VERSION ""

NS_ :

BS_:

BU_: AGSM ECM EVCU2 MCPA MCPB SGCP TCM

BO_ 262 ENGINE_FD_2: 64 ECM
 SG_ TxAC_EMCC_rq_W : 189|1@0+ (1,0) [0|1] "-"  TCM
 SG_ TRANS_CLU_SLIP_MODE_W : 71|3@0+ (1,0) [0|7] "-"  TCM
 SG_ PowertrainPrplsnActv : 181|1@0+ (1,0) [0|1] "" Vector__XXX
 SG_ MessageCounter_ENGINE2 : 435|4@0+ (1,0) [0|15] "-"  EVCU2,TCM
 SG_ LV12PwrFreeRq_W : 176|1@0+ (1,0) [0|1] "-"  EVCU2,TCM
 SG_ KickDownRequest_W : 182|1@0+ (1,0) [0|1] "-"  TCM
 SG_ IntakeAirTemperature_W : 151|8@0+ (1,-40) [-40|214] "C"  TCM
 SG_ GasPedalPositionFailSts_W : 169|1@0+ (1,0) [0|1] "-"  TCM
 SG_ GasPedalPosition_W : 143|8@0+ (0.392,0) [0|99.568] "%"  TCM
 SG_ ESS_RqShftPark_W : 115|1@0+ (1,0) [0|0] "-"  TCM
 SG_ ESS_ENG_ST_W : 175|4@0+ (1,0) [0|15] "-"  TCM
 SG_ EngTrq_Enbl_Rq_TCM_W : 178|1@0+ (1,0) [0|1] "-"  EVCU2,TCM
 SG_ EngineSts_W : 87|2@0+ (1,0) [0|3] "-"  EVCU2,TCM
 SG_ EngineSpeedFailSts_W : 168|1@0+ (1,0) [0|1] "-"  SGCP,MCPB,MCPA
 SG_ EngineSpeed_W : 21|14@0+ (1,0) [0|16382] "1/min"  SGCP,EVCU2,MCPB,MCPA,TCM
 SG_ EngineIdleRefSpeed : 35|12@0+ (1,0) [0|4094] "1/min"  EVCU2,TCM
 SG_ EngineFrictionTorque_W : 112|9@0+ (1,0) [0|510] "Nm"  EVCU2
 SG_ ECM_LHOM_W : 188|1@0+ (1,0) [0|1] "-"  EVCU2,TCM
 SG_ ECM_LHOM_Trans_W : 117|2@0+ (1,0) [0|3] "-"  EVCU2,TCM
 SG_ CRC_ENGINE2 : 447|8@0+ (1,0) [0|255] "-"  EVCU2,TCM
 SG_ CrankHold_W : 179|1@0+ (1,0) [0|1] "-" Vector__XXX
 SG_ ESS_EBOOST_BRKHLD_STATUS : 279|3@0+ (1,0) [0|6] "-" Vector__XXX
 SG_ Engine_Stall_Detected : 197|1@0+ (1,0) [0|1] "-"  EVCU2
 SG_ EssEngStrtIsNotAllwdID : 68|3@0+ (1,0) [0|7] ""  EVCU2
 SG_ EssEngStrtIsNotAllwd : 37|1@0+ (1,0) [0|1] ""  EVCU2
 SG_ EssEngStopIsNotAllwdID : 59|4@0+ (1,0) [0|15] ""  EVCU2
 SG_ EssEngStopIsNotAllwd : 255|1@0+ (1,0) [0|1] ""  EVCU2
 SG_ EssEngSt : 202|3@0+ (1,0) [0|7] ""  EVCU2
 SG_ EssEngModReq : 254|3@0+ (1,0) [0|7] ""  EVCU2
 SG_ CompressionTest : 36|1@0+ (1,0) [0|1] ""  EVCU2

BO_ 258 BRAKE_FD_2: 64 EVCU2
 SG_ VehicleSpeedVSOSig : 4|13@0+ (0.0625,0) [0|511.875] "Km/h"  SGCP,MCPB,MCPA
 SG_ MessageCounter_BRAKE2 : 435|4@0+ (1,0) [0|15] "-"  MCPB,MCPA
 SG_ LongAccelerationFailSts_BSM : 69|1@0+ (1,0) [0|1] "-"  MCPB,MCPA
 SG_ LongAcceleration_BSM : 35|12@0+ (0.02,-40.96) [-40.96|40.92] "m/s^2"  MCPB,MCPA
 SG_ LatAccelerationFailSts_BSM : 68|1@0+ (1,0) [0|1] "-"  MCPB,MCPA
 SG_ LatAcceleration_BSM : 19|12@0+ (0.02,-40.96) [-40.96|40.92] "m/s^2"  MCPB,MCPA
 SG_ ESCActive : 84|1@0+ (1,0) [0|1] "-"  MCPB,MCPA
 SG_ CRC_BRAKE2 : 447|8@0+ (1,0) [0|255] "-"  MCPB,MCPA
 SG_ ABSActive : 83|1@0+ (1,0) [0|1] "-"  MCPB,MCPA

BO_ 476 AGSM_FD_2: 32 AGSM
 SG_ ShiftLockFailSts : 91|1@0+ (1,0) [0|1] "-"  TCM
 SG_ PRNDFailSts : 82|1@0+ (1,0) [0|1] "-"  EVCU2,TCM
 SG_ PRNDdisplayFailSts : 83|1@0+ (1,0) [0|1] "-"  EVCU2,TCM
 SG_ MessageCounter_AGSM2 : 179|4@0+ (1,0) [0|15] "-"  EVCU2,TCM
 SG_ CRC_AGSM2 : 191|8@0+ (1,0) [0|255] "-"  EVCU2,TCM
 SG_ APCM_Stat : 107|2@0+ (1,0) [0|2] "-"  EVCU2,TCM
 SG_ SolenoidFlt : 100|1@0+ (1,0) [0|1] "-"  TCM
 SG_ ShiftLever_PositionFlt : 104|1@0+ (1,0) [0|1] "-"  TCM
 SG_ Low_Mode_Req : 5|1@0+ (1,0) [0|1] "-"  TCM
 SG_ ShiftLeverPositionReq : 95|4@0+ (1,0) [0|15] "-"  EVCU2,MCPB,TCM

BO_ 242 PIM_F: 64 MCPA
 SG_ MC_PF1 : 499|4@0+ (1,0) [0|15] "-"  EVCU2
 SG_ INVFInterlockSts : 229|2@0+ (1,0) [0|3] "-"  EVCU2
 SG_ InvF_DC_Voltage : 271|10@0+ (1,0) [0|1022] "V"  EVCU2
 SG_ CRC_PF1 : 511|8@0+ (1,0) [0|255] "-"  EVCU2
 SG_ InvF_DerateReason : 170|4@0+ (1,0) [0|15] "-"  EVCU2
 SG_ MCPA_Torque_Achieved : 44|13@0+ (0.125,-512) [-512|511.875] "Nm"  EVCU2
 SG_ MCPA_TorqAchieved_AEMD_V : 196|1@0+ (1,0) [0|1] ""  EVCU2
 SG_ MCPA_TorqAchieved_AEMD : 299|13@0+ (0.125,-512) [-512|511.875] "Nm"  EVCU2
 SG_ MCPA_Spd_Lim : 356|16@0+ (1,-32767) [-32767|32678] "rpm"  EVCU2
 SG_ MCPA_RPM_V : 234|1@0+ (1,0) [0|1] ""  EVCU2
 SG_ MCPA_RPM : 28|16@0+ (1,-32768) [-32768|32767] "rpm"  EVCU2
 SG_ MCPA_MtrMinCpbltyTrq : 321|13@0+ (0.125,-512) [-512|511.875] "Nm"  EVCU2
 SG_ MCPA_MtrMaxCpbltyTrq : 318|13@0+ (0.125,-512) [-512|511.875] "Nm"  EVCU2
 SG_ MCPA_MtrIndex : 398|5@0+ (1,0) [0|31] ""  EVCU2
 SG_ MCPA_MinTorq : 280|13@0+ (0.125,-512) [-512|511.875] "Nm"  EVCU2
 SG_ MCPA_MaxTorq : 277|13@0+ (0.125,-512) [-512|511.875] "Nm"  EVCU2
 SG_ MCPA_Invrtr_State : 186|4@0+ (1,0) [0|15] ""  EVCU2
 SG_ MCPA_HV_CnctrOpn_Req : 195|1@0+ (1,0) [0|1] ""  EVCU2
 SG_ MCPA_Dschrge_Status : 393|2@0+ (1,0) [0|3] ""  EVCU2
 SG_ MCPA_DeratingFactor : 388|6@0+ (0.02,0) [0|1.26] ""  EVCU2
 SG_ MCPA_DC_Volt_V : 197|1@0+ (1,0) [0|1] ""  EVCU2
 SG_ MCPA_DC_Current_V : 198|1@0+ (1,0) [0|1] ""  EVCU2
 SG_ MCPA_DC_Current : 63|15@0+ (0.1,-1638.4) [-1638.4|1638.3] "A"  EVCU2
 SG_ MCPA_CpbltySpdDivVolt : 340|16@0+ (1,0) [0|65535] "rpm"  EVCU2
 SG_ MCPA_AccelRawV : 193|1@0+ (1,0) [0|1] ""  EVCU2
 SG_ MCPA_AccelRaw : 372|16@0+ (1,0) [0|65535] ""  EVCU2
 SG_ MCPA_6SO_Status : 64|2@0+ (1,0) [0|3] ""  EVCU2
 SG_ MCPA_3PS_Pos : 194|1@0+ (1,0) [0|1] ""  EVCU2
 SG_ InvF_CoolantTemp : 407|11@0+ (0.1,-40) [-40|164.7] "°C"  EVCU2
 SG_ MCPA_Torque_Achieved_V : 129|1@0+ (1,0) [0|1] ""  EVCU2
 SG_ MCPA_SPT_Stat : 78|2@0+ (1,0) [0|3] ""  EVCU2

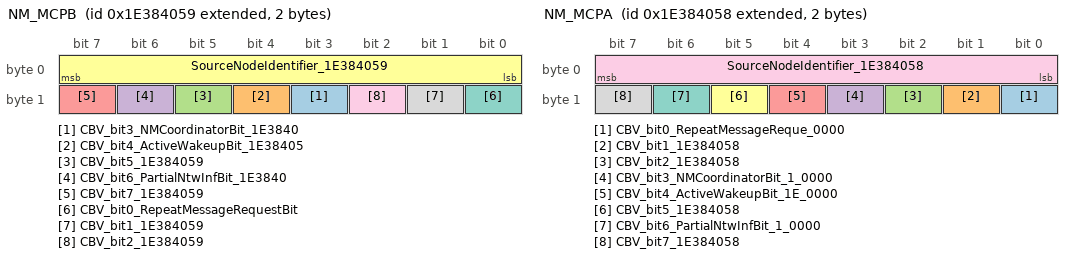
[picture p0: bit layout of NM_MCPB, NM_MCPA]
BO_ 2654486617 NM_MCPB: 2 MCPB
 SG_ CBV_bit3_NMCoordinatorBit_1E3840 : 11|1@0+ (1,0) [0|1] ""  SGCP,EVCU2,MCPA,AGSM
 SG_ CBV_bit4_ActiveWakeupBit_1E38405 : 12|1@0+ (1,0) [0|1] ""  SGCP,EVCU2,MCPA,AGSM
 SG_ CBV_bit5_1E384059 : 13|1@0+ (1,0) [0|1] ""  SGCP,EVCU2,MCPA,AGSM
 SG_ CBV_bit6_PartialNtwInfBit_1E3840 : 14|1@0+ (1,0) [0|1] ""  SGCP,EVCU2,MCPA,AGSM
 SG_ CBV_bit7_1E384059 : 15|1@0+ (1,0) [0|1] ""  SGCP,EVCU2,MCPA,AGSM
 SG_ SourceNodeIdentifier_1E384059 : 7|8@0+ (1,0) [0|255] "-"  SGCP,EVCU2,MCPA,AGSM
 SG_ CBV_bit0_RepeatMessageRequestBit : 8|1@0+ (1,0) [0|1] ""  SGCP,EVCU2,MCPA,AGSM
 SG_ CBV_bit1_1E384059 : 9|1@0+ (1,0) [0|1] ""  SGCP,EVCU2,MCPA,AGSM
 SG_ CBV_bit2_1E384059 : 10|1@0+ (1,0) [0|1] ""  SGCP,EVCU2,MCPA,AGSM

BO_ 2654486616 NM_MCPA: 2 MCPA
 SG_ CBV_bit0_RepeatMessageReque_0000 : 8|1@0+ (1,0) [0|1] ""  SGCP,EVCU2,MCPB,AGSM
 SG_ CBV_bit1_1E384058 : 9|1@0+ (1,0) [0|1] ""  SGCP,EVCU2,MCPB,AGSM
 SG_ CBV_bit2_1E384058 : 10|1@0+ (1,0) [0|1] ""  SGCP,EVCU2,MCPB,AGSM
 SG_ CBV_bit3_NMCoordinatorBit_1_0000 : 11|1@0+ (1,0) [0|1] ""  SGCP,EVCU2,MCPB,AGSM
 SG_ CBV_bit4_ActiveWakeupBit_1E_0000 : 12|1@0+ (1,0) [0|1] ""  SGCP,EVCU2,MCPB,AGSM
 SG_ CBV_bit5_1E384058 : 13|1@0+ (1,0) [0|1] ""  SGCP,EVCU2,MCPB,AGSM
 SG_ CBV_bit6_PartialNtwInfBit_1_0000 : 14|1@0+ (1,0) [0|1] ""  SGCP,EVCU2,MCPB,AGSM
 SG_ CBV_bit7_1E384058 : 15|1@0+ (1,0) [0|1] ""  SGCP,EVCU2,MCPB,AGSM
 SG_ SourceNodeIdentifier_1E384058 : 7|8@0+ (1,0) [0|255] "-"  SGCP,EVCU2,MCPB,AGSM

BO_ 2564682261 DIAGNOSTIC_ROE_FD_MCPB: 64 MCPB
 SG_ N_PDU_18DDF215 : 7|64@0+ (1,0) [0|0] ""  EVCU2

BO_ 2564682260 DIAGNOSTIC_ROE_FD_MCPA: 64 MCPA
 SG_ N_PDU_18DDF214 : 7|64@0+ (1,0) [0|0] ""  EVCU2

BO_ 2564485396 DIAGNOSTIC_RESPONSE_MCPA: 8 MCPA
 SG_ N_PDU_18DAF114 : 7|64@0+ (1,0) [0|0] ""  EVCU2

BO_ 2564485653 DIAGNOSTIC_RESPONSE_FD_MCPB: 64 MCPB
 SG_ N_PDU_18DAF215 : 7|64@0+ (1,0) [0|0] ""  EVCU2

BO_ 2564485652 DIAGNOSTIC_RESPONSE_FD_MCPA: 64 MCPA
 SG_ N_PDU_18DAF214 : 7|64@0+ (1,0) [0|0] ""  EVCU2

BO_ 2564429297 DIAGNOSTIC_REQUEST_MCPB: 8 EVCU2
 SG_ N_PDU_18DA15F1 : 7|64@0+ (1,0) [0|0] ""  MCPB

BO_ 2564429298 DIAGNOSTIC_REQUEST_FD_MCPB: 64 EVCU2
 SG_ N_PDU_18DA15F2 : 7|64@0+ (1,0) [0|0] ""  MCPB

BO_ 2564429042 DIAGNOSTIC_REQUEST_FD_MCPA: 64 EVCU2
 SG_ N_PDU_18DA14F2 : 7|64@0+ (1,0) [0|0] ""  MCPA

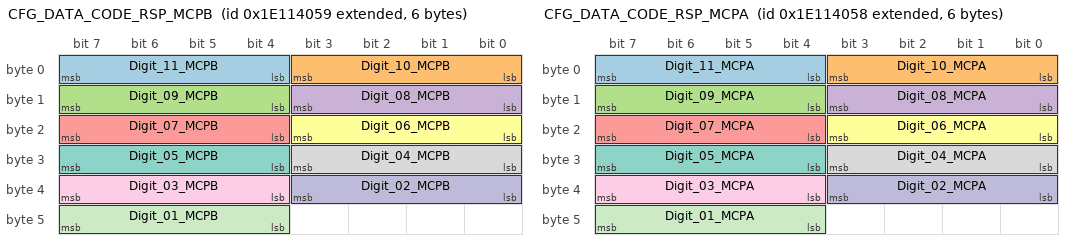
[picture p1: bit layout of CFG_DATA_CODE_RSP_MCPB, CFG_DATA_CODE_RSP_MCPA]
BO_ 2651930713 CFG_DATA_CODE_RSP_MCPB: 6 MCPB
 SG_ Digit_11_MCPB : 7|4@0+ (1,0) [0|15] "-"  EVCU2
 SG_ Digit_10_MCPB : 3|4@0+ (1,0) [0|15] "-"  EVCU2
 SG_ Digit_09_MCPB : 15|4@0+ (1,0) [0|15] "-"  EVCU2
 SG_ Digit_08_MCPB : 11|4@0+ (1,0) [0|15] "-"  EVCU2
 SG_ Digit_07_MCPB : 23|4@0+ (1,0) [0|15] "-"  EVCU2
 SG_ Digit_06_MCPB : 19|4@0+ (1,0) [0|15] "-"  EVCU2
 SG_ Digit_05_MCPB : 31|4@0+ (1,0) [0|15] "-"  EVCU2
 SG_ Digit_04_MCPB : 27|4@0+ (1,0) [0|15] "-"  EVCU2
 SG_ Digit_03_MCPB : 39|4@0+ (1,0) [0|15] "-"  EVCU2
 SG_ Digit_02_MCPB : 35|4@0+ (1,0) [0|15] "-"  EVCU2
 SG_ Digit_01_MCPB : 47|4@0+ (1,0) [0|15] "-"  EVCU2

BO_ 2651930712 CFG_DATA_CODE_RSP_MCPA: 6 MCPA
 SG_ Digit_11_MCPA : 7|4@0+ (1,0) [0|15] "-"  EVCU2
 SG_ Digit_10_MCPA : 3|4@0+ (1,0) [0|15] "-"  EVCU2
 SG_ Digit_09_MCPA : 15|4@0+ (1,0) [0|15] "-"  EVCU2
 SG_ Digit_08_MCPA : 11|4@0+ (1,0) [0|15] "-"  EVCU2
 SG_ Digit_07_MCPA : 23|4@0+ (1,0) [0|15] "-"  EVCU2
 SG_ Digit_06_MCPA : 19|4@0+ (1,0) [0|15] "-"  EVCU2
 SG_ Digit_05_MCPA : 31|4@0+ (1,0) [0|15] "-"  EVCU2
 SG_ Digit_04_MCPA : 27|4@0+ (1,0) [0|15] "-"  EVCU2
 SG_ Digit_03_MCPA : 39|4@0+ (1,0) [0|15] "-"  EVCU2
 SG_ Digit_02_MCPA : 35|4@0+ (1,0) [0|15] "-"  EVCU2
 SG_ Digit_01_MCPA : 47|4@0+ (1,0) [0|15] "-"  EVCU2

BO_ 496 PARK_DATA: 24 MCPB
 SG_ MessageCounter_PARK_DATA : 115|4@0+ (1,0) [0|15] ""  EVCU2
 SG_ CRC_PARK_DATA : 127|8@0+ (1,0) [0|255] ""  EVCU2
 SG_ PlockFailSts : 4|3@0+ (1,0) [0|6] ""  EVCU2
 SG_ Plock_PosSensor : 1|3@0+ (1,0) [0|6] ""  EVCU2
 SG_ Plock_MotorPosSts : 29|3@0+ (1,0) [0|6] ""  EVCU2
 SG_ MPR_PosSensor : 14|3@0+ (1,0) [0|6] ""  EVCU2
 SG_ Plock_fdbk_sts : 7|3@0+ (1,0) [0|7] ""  EVCU2

BO_ 1454 MCPB_DATA: 16 MCPB
 SG_ MCPB_Service_Lamp_Request : 22|1@0+ (1,0) [0|1] ""  EVCU2

BO_ 1444 MCPA_DATA: 16 MCPA
 SG_ MCPA_Service_Lamp_Request : 22|1@0+ (1,0) [0|1] ""  EVCU2

BO_ 105 VDCM_PWT3: 64 EVCU2
 SG_ T7_Sensor_Temp : 330|11@0+ (0.1,-40) [-40|164.7] "°C"  SGCP,MCPB,MCPA
 SG_ T7_CoolantTempVldty : 331|1@0+ (1,0) [0|1] ""  SGCP,MCPB,MCPA
 SG_ T4_Sensor_Temp : 378|11@0+ (0.1,-40) [-40|164.7] "°C"  SGCP,MCPB,MCPA
 SG_ PwrElecSnsr_TEMP : 55|8@0+ (1,-40) [-40|215] "°C"  SGCP
 SG_ PwrElecPmp_TEMP : 47|8@0+ (1,-40) [-40|215] "°C"  SGCP
 SG_ PIMRR_CoolantFlow : 318|7@0+ (0.5,0) [0|63.5] "Lpm"  SGCP

BO_ 260 PIM_RR: 64 MCPB
 SG_ INVRRInterlockSts : 253|2@0+ (1,0) [0|3] ""  EVCU2
 SG_ InvRR_DC_Voltage : 191|10@0+ (1,0) [0|1022] "V"  EVCU2
 SG_ InvRR_DerateReason : 143|4@0+ (1,0) [0|15] "-"  EVCU2
 SG_ InvRR_ACVoltage : 104|10@0+ (1,0) [0|1022] "V"  EVCU2
 SG_ RPM_MCPB : 22|16@0+ (1,-32768) [-32768|32767] "rpm"  EVCU2
 SG_ MCPB_Torque_Achieved_V : 38|1@0+ (1,0) [0|1] ""  EVCU2
 SG_ MCPB_Torque_Achieved : 251|13@0+ (0.125,-512) [-512|511.875] "Nm"  EVCU2
 SG_ MCPB_TorqAchieved_AEMD_V : 35|1@0+ (1,0) [0|1] ""  EVCU2
 SG_ MCPB_TorqAchieved_AEMD : 302|13@0+ (0.125,-512) [-512|511.875] "Nm"  EVCU2
 SG_ MCPB_Spd_Lim : 343|16@0+ (1,-32767) [-32767|32678] "rpm"  EVCU2
 SG_ MCPB_RPM_V : 204|1@0+ (1,0) [0|1] ""  EVCU2
 SG_ MCPB_MtrMinCpbltyTrq : 324|13@0+ (0.125,-512) [-512|511.875] "Nm"  EVCU2
 SG_ MCPB_MtrMaxCpbltyTrq : 305|13@0+ (0.125,-512) [-512|511.875] "Nm"  EVCU2
 SG_ MCPB_MtrIndex : 147|5@0+ (1,0) [0|31] ""  EVCU2
 SG_ MCPB_MinTorq : 283|13@0+ (0.125,-512) [-512|511.875] "Nm"  EVCU2
 SG_ MCPB_MaxTorq : 264|13@0+ (0.125,-512) [-512|511.875] "Nm"  EVCU2
 SG_ MCPB_Invrtr_State : 151|4@0+ (1,0) [0|15] ""  EVCU2
 SG_ MCPB_HV_CnctrOpn_Req : 34|1@0+ (1,0) [0|1] ""  EVCU2
 SG_ MCPB_Dschrge_Status : 102|2@0+ (1,0) [0|3] ""  EVCU2
 SG_ MCPB_DeratingFactor : 270|6@0+ (0.02,0) [0|1.26] ""  EVCU2
 SG_ MCPB_DC_Volt_V : 36|1@0+ (1,0) [0|1] ""  EVCU2
 SG_ MCPB_DC_Current_V : 37|1@0+ (1,0) [0|1] ""  EVCU2
 SG_ MCPB_DC_Current : 391|15@0+ (0.1,-1638.4) [-1638.4|1638.3] "A"  EVCU2
 SG_ MCPB_CpbltySpdDivVolt : 392|16@0+ (1,0) [0|65535] "V"  EVCU2
 SG_ MCPB_AccelRawV : 32|1@0+ (1,0) [0|1] ""  EVCU2
 SG_ MCPB_AccelRaw : 359|16@0+ (1,0) [0|65535] ""  EVCU2
 SG_ MCPB_6SO_Status : 47|2@0+ (1,0) [0|3] ""  EVCU2
 SG_ MCPB_3PS_Pos : 33|1@0+ (1,0) [0|1] ""  EVCU2
 SG_ MC_PRR1 : 499|4@0+ (1,0) [0|15] ""  EVCU2
 SG_ InvRR_CoolantTemp : 375|11@0+ (0.1,-40) [-40|164.7] "°C"  EVCU2
 SG_ CRC_PRR1 : 511|8@0+ (1,0) [0|255] ""  EVCU2
 SG_ MCPB_SPT_Stat : 158|2@0+ (1,0) [0|3] ""  EVCU2

BO_ 1062 MCPA_DATA2: 64 MCPA
 SG_ MCPA_Temp : 7|8@0+ (1,-40) [-40|215] "°C"  EVCU2
 SG_ MCPA_Rotor_Temperature : 31|8@0+ (1,-40) [-40|215] "°C"  EVCU2
 SG_ MCPA_Inverter_Temp : 15|8@0+ (1,-40) [-40|215] "°C"  EVCU2
 SG_ MCPA_Control_Board_Temperature : 23|8@0+ (1,-40) [-40|215] "°C"  EVCU2
 SG_ CLrDiagInfo_MCPA : 248|1@0+ (1,0) [0|1] ""  EVCU2
 SG_ MessageCounter_MCPA_DATA2 : 435|4@0+ (1,0) [0|15] ""  EVCU2
 SG_ CRC_MCPA_DATA2 : 447|8@0+ (1,0) [0|255] ""  EVCU2
 SG_ MCPA_PIM_DC_Side_Busbar_Temp : 423|8@0+ (1,-40) [-40|215] "°C"  EVCU2
 SG_ MCPA_Service_Lamp_Request_2 : 47|1@0+ (1,0) [0|1] ""  EVCU2

BO_ 300 INVTARGET1: 64 EVCU2
 SG_ UDCMax_Unlim_MCPB : 113|16@0+ (0.01,0) [0|655.35] "V"  MCPB
 SG_ UDCMax_Unlim_MCPA : 65|16@0+ (0.01,0) [0|655.35] "V"  MCPA
 SG_ TqGrdtLim_MCPB : 144|16@0+ (0.1,0) [0|6553.5] "Nm/s"  MCPB
 SG_ TqGrdtLim_MCPA : 97|16@0+ (0.1,0) [0|6553.5] "Nm/s"  MCPA
 SG_ TorqueCommand_MCPB : 201|13@0+ (0.125,-512) [-512|511.875] "Nm"  MCPB
 SG_ TorqueCommand_MCPA : 7|13@0+ (0.125,-512) [-512|511.875] "Nm"  MCPA
 SG_ TargetMotorRPM_MCPB : 216|16@0+ (0.5,-16384) [-16384|16383.5] "rpm"  MCPB
 SG_ TargetMotorRPM_MCPA : 22|16@0+ (0.5,-16384) [-16384|16383.5] "rpm"  MCPA
 SG_ SpdGrdtLim_MCPB : 273|11@0+ (20,0) [0|40940] "rpm/s"  MCPB
 SG_ SpdGrdtLim_MCPA : 160|11@0+ (20,0) [0|40940] "rpm/s"  MCPA
 SG_ Mtr_6SO_Request_MCPB : 145|1@0+ (1,0) [0|1] ""  MCPB
 SG_ Mtr_6SO_Request_MCPA : 38|1@0+ (1,0) [0|1] ""  MCPA
 SG_ ModeCommand_MCPB : 220|4@0+ (1,0) [0|15] ""  MCPB
 SG_ ModeCommand_MCPA : 10|4@0+ (1,0) [0|15] ""  MCPA
 SG_ MessageCounter_INVTARGET1 : 435|4@0+ (1,0) [0|15] ""  SGCP,MCPB,MCPA
 SG_ CRC_INVTARGET1 : 447|8@0+ (1,0) [0|255] ""  SGCP,MCPB,MCPA
 SG_ AEMD_MinOffset_MCPB : 252|12@0+ (0.125,-511.875) [-511.875|0] "Nm"  MCPB
 SG_ AEMD_MinOffset_MCPA : 41|12@0+ (0.125,-511.875) [-511.875|0] "Nm"  MCPA
 SG_ AEMD_MaxOffset_MCPB : 232|12@0+ (0.125,0) [0|511.875] "Nm"  MCPB
 SG_ AEMD_MaxOffset_MCPA : 37|12@0+ (0.125,0) [0|511.875] "Nm"  MCPA
 SG_ AEMD_Sclr_Gn_MCPB : 356|9@0+ (0.01,0) [0|5.11] "rad/s"  MCPB
 SG_ AEMD_Sclr_Gn_MCPA : 349|9@0+ (0.01,0) [0|5.11] "rad/s"  MCPA
 SG_ AEMD_Cutoff_FreqHigh_MCPB : 383|8@0+ (0.1,0) [0|25.5] "Hz"  MCPB
 SG_ AEMD_Cutoff_FreqHigh_MCPA : 375|8@0+ (0.1,0) [0|25.5] "Hz"  MCPA
 SG_ Pwr_Electronics_Loop_FlwRate_MCP : 57|8@0+ (0.1,0) [0|25.5] "LPM"  MCPA
 SG_ AEMD_Cutoff_FreqLow_MCPB : 407|8@0+ (0.1,4.5) [4.5|30] "Hz"  MCPB
 SG_ AEMD_Cutoff_FreqLow_MCPA : 399|8@0+ (0.1,4.5) [4.5|30] "Hz"  MCPA
 SG_ Pwr_Electronics_Loop_FlwRat_0000 : 265|8@0+ (0.1,0) [0|25.5] "LPM"  MCPB

BO_ 1063 MCPB_DATA2: 64 MCPB
 SG_ MCPB_Temp : 6|8@0+ (1,-40) [-40|215] "°C"  EVCU2
 SG_ MCPB_Rotor_Temperature : 30|8@0+ (1,-40) [-40|215] "°C"  EVCU2
 SG_ MCPB_Inverter_Temp : 14|8@0+ (1,-40) [-40|215] "°C"  EVCU2
 SG_ MCPB_Control_Board_Temperature : 22|8@0+ (1,-40) [-40|215] "°C"  EVCU2
 SG_ CLrDiagInfo_MCPB : 7|1@0+ (1,0) [0|1] ""  EVCU2
 SG_ MessageCounter_MCPB_DATA2 : 435|4@0+ (1,0) [0|15] ""  EVCU2
 SG_ CRC_MCPB_DATA2 : 447|8@0+ (1,0) [0|255] ""  EVCU2
 SG_ MCPB_PIM_DC_Side_Busbar_Temp : 55|8@0+ (1,-40) [-40|215] "°C"  EVCU2
 SG_ MCPB_Service_Lamp_Request_2 : 47|1@0+ (1,0) [0|1] ""  EVCU2

BO_ 292 BATTERY_HV_STATUS1: 64 EVCU2
 SG_ MessageCounter_BATT_HV_STATUS1 : 435|4@0+ (1,0) [0|15] "-"  SGCP,MCPB,MCPA
 SG_ CRC_BATT_HV_STATUS1 : 447|8@0+ (1,0) [0|255] "-"  SGCP,MCPB,MCPA
 SG_ BPCM_HV_TractionBusVoltage : 146|11@0+ (1,0) [0|2047] "V"  SGCP,MCPB,MCPA
 SG_ BPCM_HV_Trac_Bus_Sts : 36|3@0+ (1,0) [0|7] ""  SGCP,MCPB,MCPA

BO_ 2654339273 PDC_INFO_FD_SGCP: 32 SGCP
 SG_ GenericFailSts_FD16_SGCP : 180|1@0+ (1,0) [0|1] ""  EVCU2
 SG_ EOL_FD16_SGCP : 2|1@0+ (1,0) [0|1] "-"  EVCU2
 SG_ CurrentFailSts_FD16_SGCP : 181|1@0+ (1,0) [0|1] ""  EVCU2

BO_ 2654339161 PDC_INFO_FD_MCPB: 32 MCPB
 SG_ EOL_FD16_MCPB : 2|1@0+ (1,0) [0|1] "-"  EVCU2
 SG_ GenericFailSts_FD16_MCPB : 172|1@0+ (1,0) [0|1] ""  EVCU2
 SG_ CurrentFailSts_FD16_MCPB : 173|1@0+ (1,0) [0|1] ""  EVCU2

BO_ 2654339160 PDC_INFO_FD_MCPA: 32 MCPA
 SG_ EOL_FD16_MCPA : 2|1@0+ (1,0) [0|1] "-"  EVCU2
 SG_ GenericFailSts_FD16_MCPA : 172|1@0+ (1,0) [0|1] ""  EVCU2
 SG_ CurrentFailSts_FD16_MCPA : 173|1@0+ (1,0) [0|1] ""  EVCU2

BO_ 2564682364 DIAGNOSTIC_ROE_FD_SGCP: 64 SGCP
 SG_ N_PDU_18DDF27C : 7|64@0+ (1,0) [0|0] ""  EVCU2

BO_ 2564485756 DIAGNOSTIC_RESPONSE_FD_SGCP: 64 SGCP
 SG_ N_PDU_18DAF27C : 7|64@0+ (1,0) [0|0] ""  EVCU2

BO_ 2564455666 DIAGNOSTIC_REQUEST_FD_SGCP: 64 EVCU2
 SG_ N_PDU_18DA7CF2 : 7|64@0+ (1,0) [0|0] ""  SGCP

BO_ 243 SGCP_PWT1: 64 SGCP
 SG_ SGCP_Torque_Achieved_V : 195|1@0+ (1,0) [0|1] ""  EVCU2
 SG_ SGCP_Torque_Achieved : 44|13@0+ (0.125,-512) [-512|511.875] "Nm"  EVCU2
 SG_ SGCP_TorqAchieved_AEMD_V : 45|1@0+ (1,0) [0|1] ""  EVCU2
 SG_ SGCP_TorqAchieved_AEMD : 299|13@0+ (0.125,-512) [-512|511.875] "Nm"  EVCU2
 SG_ SGCP_SPT_Stat : 78|2@0+ (1,0) [0|3] ""  EVCU2
 SG_ SGCP_Spd_Lim : 356|16@0+ (1,-32767) [-32767|32678] "rpm"  EVCU2
 SG_ SGCP_RPM_V : 192|1@0+ (1,0) [0|1] ""  EVCU2
 SG_ SGCP_RPM : 7|16@0+ (1,-32768) [-32768|32767] "rpm"  EVCU2
 SG_ SGCP_MtrMinCpbltyTrq : 321|13@0+ (0.125,-512) [-512|511.875] "Nm"  EVCU2
 SG_ SGCP_MtrMaxCpbltyTrq : 318|13@0+ (0.125,-512) [-512|511.875] "Nm"  EVCU2
 SG_ SGCP_MtrIndex : 398|5@0+ (1,0) [0|31] ""  EVCU2
 SG_ SGCP_MinTorq : 280|13@0+ (0.125,-512) [-512|511.875] "Nm"  EVCU2
 SG_ SGCP_MaxTorq : 277|13@0+ (0.125,-512) [-512|511.875] "Nm"  EVCU2
 SG_ SGCP_Invrtr_State : 187|4@0+ (1,0) [0|15] ""  EVCU2
 SG_ SGCP_InterlockSts : 194|2@0+ (1,0) [0|3] "-"  EVCU2
 SG_ SGCP_HV_CnctrOpn_Req : 74|1@0+ (1,0) [0|1] ""  EVCU2
 SG_ SGCP_Dschrge_Status : 393|2@0+ (1,0) [0|3] ""  EVCU2
 SG_ SGCP_DeratingFactor : 388|6@0+ (0.02,0) [0|1.26] ""  EVCU2
 SG_ SGCP_DerateReason : 191|4@0+ (1,0) [0|15] "-"  EVCU2
 SG_ SGCP_DC_Voltage : 271|10@0+ (1,0) [0|1022] "V"  EVCU2
 SG_ SGCP_DC_Volt_V : 75|1@0+ (1,0) [0|1] ""  EVCU2
 SG_ SGCP_DC_Current_V : 76|1@0+ (1,0) [0|1] ""  EVCU2
 SG_ SGCP_DC_Current : 63|15@0+ (0.1,-1638.4) [-1638.4|1638.3] "A"  EVCU2
 SG_ SGCP_CpbltySpdDivVolt : 340|16@0+ (1,0) [0|65535] "rpm"  EVCU2
 SG_ SGCP_Comm_Fail_CAN : 199|4@0+ (1,0) [0|14] ""  EVCU2
 SG_ SGCP_AccelRawV : 72|1@0+ (1,0) [0|1] ""  EVCU2
 SG_ SGCP_AccelRaw : 372|16@0+ (1,0) [0|65535] ""  EVCU2
 SG_ SGCP_6SO_Status : 64|2@0+ (1,0) [0|3] ""  EVCU2
 SG_ SGCP_3PS_Pos : 73|1@0+ (1,0) [0|1] ""  EVCU2
 SG_ MC_SGCP_PWT1 : 435|4@0+ (1,0) [0|15] "-"  EVCU2
 SG_ CRC_SGCP_PWT1 : 447|8@0+ (1,0) [0|255] "-"  EVCU2

CM_ SG_ 262 TxAC_EMCC_rq_W "-";
CM_ SG_ 262 TRANS_CLU_SLIP_MODE_W "-";
CM_ SG_ 262 PowertrainPrplsnActv "Powertrain Propulsion Status.";
CM_ SG_ 262 MessageCounter_ENGINE2 "This signal is a counter used for safety checks strategies. This counter is incremented of 1 (one) unit at each frame transmission.";
CM_ SG_ 262 LV12PwrFreeRq_W "-";
CM_ SG_ 262 KickDownRequest_W "It is set to KD_requested whenever the Kick-Down condition is detected by the ECM.";
CM_ SG_ 262 GasPedalPositionFailSts_W "-";
CM_ SG_ 262 GasPedalPosition_W "-";
CM_ SG_ 262 ESS_RqShftPark_W "ESS Request shift to Park.  1 = True, 0 = False";
CM_ SG_ 262 ESS_ENG_ST_W "ESS Engine State";
CM_ SG_ 262 EngTrq_Enbl_Rq_TCM_W "Allow TRANS torque request";
CM_ SG_ 262 EngineSts_W "-";
CM_ SG_ 262 EngineSpeedFailSts_W "Used to indicate if a Fail is present for the engine speed";
CM_ SG_ 262 EngineSpeed_W "It gives information on C-CAN network about  engine speed";
CM_ SG_ 262 EngineIdleRefSpeed "This signal represents target of engine speed for the idle control function, at the end of dynamic transient conditions. It takes into account changes of idle speed due to temperature and auxiliary loads. It is updated even when the engine is ou(...)";
CM_ SG_ 262 EngineFrictionTorque_W "-";
CM_ SG_ 262 ECM_LHOM_W "-";
CM_ SG_ 262 ECM_LHOM_Trans_W "Indicates to the transmission the Limp Home Status of ECM and Torque Accuracy";
CM_ SG_ 262 CRC_ENGINE2 "CRC according to SAE J1850 standard at each frame transmission.";
CM_ SG_ 262 CrankHold_W "Used by ECM to command an action to the BCM cranking relay during cranking phase";
CM_ SG_ 262 ESS_EBOOST_BRKHLD_STATUS "ESS brake hold release status";
CM_ SG_ 262 Engine_Stall_Detected "Engine stall detected flag";
CM_ SG_ 262 EssEngStrtIsNotAllwdID "This is an enumerated interface that reports the reason why a Start is not allowed by the ECM";
CM_ SG_ 262 EssEngStrtIsNotAllwd "This is a flag that signifies if a start is allowed by the ECM";
CM_ SG_ 262 EssEngStopIsNotAllwdID "This is an enumerated interface that reports the reason why a Stop is not allowed by the ECM";
CM_ SG_ 262 EssEngStopIsNotAllwd "This is a flag that signifies if a stop is allowed by the ECM";
CM_ SG_ 262 EssEngSt "Signal that gives feedback on the current engine state";
CM_ SG_ 262 EssEngModReq "Command signal from EssEveMgr that directs the engine actuators for turning On or Off the engine";
CM_ SG_ 262 CompressionTest "This signal requests a compression test";
CM_ SG_ 258 VehicleSpeedVSOSig "It is the average vehicle speed calculated.";
CM_ SG_ 258 MessageCounter_BRAKE2 "This signal is a counter used for safety checks strategies. This counter is incremented of 1 (one) unit at each frame transmission.";
CM_ SG_ 258 LongAccelerationFailSts_BSM "This signal indicates the status of Longitudinal acceleration signal";
CM_ SG_ 258 LongAcceleration_BSM "This signal indicates the Longitudinal Acceleration Value";
CM_ SG_ 258 LatAccelerationFailSts_BSM "This signal indicates the status of Lateral Acceleration Signal";
CM_ SG_ 258 LatAcceleration_BSM "This signal indicates the Lateral Acceleration Value";
CM_ SG_ 258 ESCActive "This signal is set to Active when the brake intervention by ESC is active.";
CM_ SG_ 258 CRC_BRAKE2 "CRC according to SAE J1850 standard at each frame transmission.";
CM_ SG_ 258 ABSActive "This signal is set to Active when the ABS functionality is active.";
CM_ SG_ 476 ShiftLockFailSts "-";
CM_ SG_ 476 PRNDFailSts "-";
CM_ SG_ 476 PRNDdisplayFailSts "-";
CM_ SG_ 476 MessageCounter_AGSM2 "This signal is a counter used for safety checks strategies. This counter is incremented of 1 (one) unit at each frame transmission.";
CM_ SG_ 476 CRC_AGSM2 "CRC according to SAE J1850 standard at each frame transmission.";
CM_ SG_ 476 APCM_Stat "Auto position correction mode status";
CM_ SG_ 476 SolenoidFlt "Rack / detent sensor fault, 1=fault";
CM_ SG_ 476 ShiftLever_PositionFlt "Shifter Position Failure";
CM_ SG_ 476 Low_Mode_Req "Signal Indicating L Button Pressed Status";
CM_ SG_ 476 ShiftLeverPositionReq "This signal describes the shift lever position requested by the driver.";
CM_ SG_ 242 MC_PF1 "Message counter according to SAE J1850 standard that has to be calculated from bit 63 to bit 8 at each frame transmission.";
CM_ SG_ 242 INVFInterlockSts "Front inverter interlock state";
CM_ SG_ 242 InvF_DC_Voltage "Inverter Front DC Voltage.";
CM_ SG_ 242 CRC_PF1 "CRC according to SAE J1850 standard that has to be calculated from bit 63 to bit 8 at each frame transmission.";
CM_ SG_ 242 InvF_DerateReason "Inverter Derating Reason";
CM_ SG_ 242 MCPA_Torque_Achieved "Motr B Torque Achieved";
CM_ SG_ 242 MCPA_TorqAchieved_AEMD_V "Motor Torque Achieved Validity";
CM_ SG_ 242 MCPA_TorqAchieved_AEMD "Motor Torque Achieved";
CM_ SG_ 242 MCPA_Spd_Lim "Limited motor speed during reduced performance from MCP B";
CM_ SG_ 242 MCPA_RPM_V "Motor A Speed Validity, [1] = True";
CM_ SG_ 242 MCPA_RPM "Motor A Speed Raw";
CM_ SG_ 242 MCPA_MtrMinCpbltyTrq "Motor A Min Capability Torque";
CM_ SG_ 242 MCPA_MtrMaxCpbltyTrq "Motor A Max Capability Torque";
CM_ SG_ 242 MCPA_MtrIndex "Motor A Capability Curve Array Index";
CM_ SG_ 242 MCPA_MinTorq "Motor A Minimum Torque";
CM_ SG_ 242 MCPA_MaxTorq "Motor A Maximum Torque";
CM_ SG_ 242 MCPA_Invrtr_State "Inverter State of Operation of Motor A";
CM_ SG_ 242 MCPA_HV_CnctrOpn_Req "HV Battery pack contactor request";
CM_ SG_ 242 MCPA_Dschrge_Status "The active discharge status of MCPA";
CM_ SG_ 242 MCPA_DeratingFactor "Motor A Derating Factor";
CM_ SG_ 242 MCPA_DC_Volt_V "Motor A DC current  validity, [1] = True";
CM_ SG_ 242 MCPA_DC_Current_V "Motor A DC current  validity, [1] = True";
CM_ SG_ 242 MCPA_DC_Current "Motor A DC Current";
CM_ SG_ 242 MCPA_CpbltySpdDivVolt "Motor A Speed at Capability Curve";
CM_ SG_ 242 MCPA_AccelRawV "Motor A Acceleration Validity";
CM_ SG_ 242 MCPA_AccelRaw "Motor A Acceleration";
CM_ SG_ 242 MCPA_6SO_Status "Motor A 6SO Status";
CM_ SG_ 242 MCPA_3PS_Pos "3 phase motor short possible from MCP B; True = [1]";
CM_ SG_ 242 InvF_CoolantTemp "PIM Coolant Temperature";
CM_ SG_ 242 MCPA_Torque_Achieved_V "Achieved Torque value Validity, [1] = True";
CM_ SG_ 242 MCPA_SPT_Stat "Inverter Isolation Status";
CM_ SG_ 2654486617 CBV_bit3_NMCoordinatorBit_1E3840 "NM Coordinator Sleep Bit";
CM_ SG_ 2654486617 CBV_bit4_ActiveWakeupBit_1E38405 "Active Wakeup Bit";
CM_ SG_ 2654486617 CBV_bit6_PartialNtwInfBit_1E3840 "Partial Network Information Bit (PNI)";
CM_ SG_ 2654486617 SourceNodeIdentifier_1E384059 "Source Node Identifier";
CM_ SG_ 2654486617 CBV_bit0_RepeatMessageRequestBit "Repeat Message Request Bit";
CM_ SG_ 2654486616 CBV_bit0_RepeatMessageReque_0000 "Repeat Message Request Bit";
CM_ SG_ 2654486616 CBV_bit3_NMCoordinatorBit_1_0000 "NM Coordinator Sleep Bit";
CM_ SG_ 2654486616 CBV_bit4_ActiveWakeupBit_1E_0000 "Active Wakeup Bit";
CM_ SG_ 2654486616 CBV_bit6_PartialNtwInfBit_1_0000 "Partial Network Information Bit (PNI)";
CM_ SG_ 2654486616 SourceNodeIdentifier_1E384058 "Source Node Identifier";
CM_ SG_ 2564682261 N_PDU_18DDF215 "This signal is used for diagnostic purposes";
CM_ SG_ 2564682260 N_PDU_18DDF214 "This signal is used for diagnostic purposes";
CM_ SG_ 2564485396 N_PDU_18DAF114 "This signal is used for diagnostic purposes";
CM_ SG_ 2564485653 N_PDU_18DAF215 "This signal is used for diagnostic purposes";
CM_ SG_ 2564485652 N_PDU_18DAF214 "This signal is used for diagnostic purposes";
CM_ SG_ 2564429297 N_PDU_18DA15F1 "This signal is used for diagnostic purposes";
CM_ SG_ 2564429298 N_PDU_18DA15F2 "This signal is used for diagnostic purposes";
CM_ SG_ 2564429042 N_PDU_18DA14F2 "This signal is used for diagnostic purposes";
CM_ SG_ 496 MessageCounter_PARK_DATA "This signal is a counter used for safety checks strategies. This counter is incremented of 1 (one) unit at each frame transmission.";
CM_ SG_ 496 CRC_PARK_DATA "CRC according to SAE J1850 standard at each frame transmission.";
CM_ SG_ 496 PlockFailSts "Park Lock Fail Sts";
CM_ SG_ 496 Plock_PosSensor "Par lock physical position sensor feedback";
CM_ SG_ 496 Plock_MotorPosSts "Park lock motor position status";
CM_ SG_ 496 MPR_PosSensor "Manual Park Release sensor feedback";
CM_ SG_ 496 Plock_fdbk_sts "Park lock status";
CM_ SG_ 1454 MCPB_Service_Lamp_Request "The Service Lamp Request from the MCPB";
CM_ SG_ 1444 MCPA_Service_Lamp_Request "The Service Light Request from the MCPA";
CM_ SG_ 105 T7_Sensor_Temp "T7 Temperature sensor";
CM_ SG_ 105 T7_CoolantTempVldty "Inlet inverter temperature validity";
CM_ SG_ 105 T4_Sensor_Temp "T4 Temperature sensor";
CM_ SG_ 105 PwrElecSnsr_TEMP "PwrElecSensor_TEMP";
CM_ SG_ 105 PwrElecPmp_TEMP "PwrElecPmp temperature";
CM_ SG_ 105 PIMRR_CoolantFlow "Rear PIM flow rate";
CM_ SG_ 260 INVRRInterlockSts "Rear right inverter interlock state";
CM_ SG_ 260 InvRR_DC_Voltage "This signal indicates the Inverter Rear Right DC Voltage.";
CM_ SG_ 260 InvRR_DerateReason "Inverter Derating Reason.";
CM_ SG_ 260 InvRR_ACVoltage "AC RMS Voltage.";
CM_ SG_ 260 RPM_MCPB "Motor B Speed Raw";
CM_ SG_ 260 MCPB_Torque_Achieved_V "Achieved Torque value Validity, [1] = True";
CM_ SG_ 260 MCPB_Torque_Achieved "Motr B Torque Achieved";
CM_ SG_ 260 MCPB_TorqAchieved_AEMD_V "Motor Torque Achieved Validity";
CM_ SG_ 260 MCPB_TorqAchieved_AEMD "Motor Torque Achieved";
CM_ SG_ 260 MCPB_Spd_Lim "Limited motor speed during reduced performance from MCP B";
CM_ SG_ 260 MCPB_RPM_V "Motor B Speed Validity, [1] = True";
CM_ SG_ 260 MCPB_MtrMinCpbltyTrq "Motor B Min Capability Torque";
CM_ SG_ 260 MCPB_MtrMaxCpbltyTrq "Motor B Max Capability Torque";
CM_ SG_ 260 MCPB_MtrIndex "Motor B Capability Curve Array Index";
CM_ SG_ 260 MCPB_MinTorq "Motor B Minimum Torque";
CM_ SG_ 260 MCPB_MaxTorq "Motor B Maximum Torque";
CM_ SG_ 260 MCPB_Invrtr_State "Inverter State of Operation of Motor B";
CM_ SG_ 260 MCPB_HV_CnctrOpn_Req "HV Battery pack contactor request";
CM_ SG_ 260 MCPB_Dschrge_Status "The active discharge status of MCPB";
CM_ SG_ 260 MCPB_DeratingFactor "Motor B Derating Factor";
CM_ SG_ 260 MCPB_DC_Volt_V "Achieved Torque value Validity, [1] = True";
CM_ SG_ 260 MCPB_DC_Current_V "Achieved Torque value Validity, [1] = True";
CM_ SG_ 260 MCPB_DC_Current "Motor B DC Current";
CM_ SG_ 260 MCPB_CpbltySpdDivVolt "Motor B Speed at Capability Curve";
CM_ SG_ 260 MCPB_AccelRawV "Motor B Acceleration Validity";
CM_ SG_ 260 MCPB_AccelRaw "Motor B Acceleration";
CM_ SG_ 260 MCPB_6SO_Status "Motor B 6SO Status";
CM_ SG_ 260 MCPB_3PS_Pos "3 phase motor short possible from MCP B; True = [1]";
CM_ SG_ 260 MC_PRR1 "This signal indicates the Message Counter SaeJ1850.";
CM_ SG_ 260 InvRR_CoolantTemp "PIM Coolant Temperature";
CM_ SG_ 260 CRC_PRR1 "This signal indicates the CRC SaeJ1850.";
CM_ SG_ 260 MCPB_SPT_Stat "Inverter Isolation Status";
CM_ SG_ 1062 MCPA_Temp "Motor A temperature";
CM_ SG_ 1062 MCPA_Rotor_Temperature "Rotor Temperature from Motor";
CM_ SG_ 1062 MCPA_Inverter_Temp "Inverter B Temperature";
CM_ SG_ 1062 MCPA_Control_Board_Temperature "Control Board temperature from Motor";
CM_ SG_ 1062 CLrDiagInfo_MCPA "Legislative Diagnostic Clear information for MCPA";
CM_ SG_ 1062 MessageCounter_MCPA_DATA2 "This signal is a counter used for safety checks strategies. This counter is incremented of 1 (one) unit at each frame transmission.";
CM_ SG_ 1062 CRC_MCPA_DATA2 "CRC according to SAE J1850 standard at each frame transmission.";
CM_ SG_ 1062 MCPA_PIM_DC_Side_Busbar_Temp "MCPA busbar temperature in DC side";
CM_ SG_ 1062 MCPA_Service_Lamp_Request_2 "The Service Light Request from the MCPA";
CM_ SG_ 300 UDCMax_Unlim_MCPB "Maximum DC voltage limit before linear generator derating Consider Max or Min torque. Default 52V";
CM_ SG_ 300 UDCMax_Unlim_MCPA "Maximum DC voltage limit before linear generator derating Consider Max or Min torque. Default 52V";
CM_ SG_ 300 TqGrdtLim_MCPB "Positive or Negative Torque Gradient applied for Torque Control Mode and Speed Control Mode. Default 1000Nm/s";
CM_ SG_ 300 TqGrdtLim_MCPA "Positive or Negative Torque Gradient applied for Torque Control Mode and Speed Control Mode. Default 1000Nm/s";
CM_ SG_ 300 TorqueCommand_MCPB "Torque command for MCPB";
CM_ SG_ 300 TorqueCommand_MCPA "Torque command for MCPA";
CM_ SG_ 300 TargetMotorRPM_MCPB "Target Motor RPM for MCPB";
CM_ SG_ 300 TargetMotorRPM_MCPA "Target Motor RPM for MCPA";
CM_ SG_ 300 SpdGrdtLim_MCPB "Positive or negative (symetric) Speed Request Gradient applicable on both sign only for Speed Control Mode. Default 25,000 rpm/s";
CM_ SG_ 300 SpdGrdtLim_MCPA "Positive or negative (symetric) Speed Request Gradient applicable on both sign only for Speed Control Mode. Default 25,000 rpm/s";
CM_ SG_ 300 Mtr_6SO_Request_MCPB "Six Switch Open Request  for MCPB (1=RequestActive; 0=RequestNotActive)";
CM_ SG_ 300 Mtr_6SO_Request_MCPA "Six Switch Open Request  for MCPA (1=RequestActive; 0=RequestNotActive)";
CM_ SG_ 300 ModeCommand_MCPB "Mode command for MCPB";
CM_ SG_ 300 ModeCommand_MCPA "Mode command for MCPA";
CM_ SG_ 300 MessageCounter_INVTARGET1 "This signal is a counter used for safety checks strategies. This counter is incremented of 1 (one) unit at each frame transmission.";
CM_ SG_ 300 CRC_INVTARGET1 "CRC according to SAE J1850 standard at each frame transmission.";
CM_ SG_ 300 AEMD_MinOffset_MCPB "MCPB AEMD Min Offset";
CM_ SG_ 300 AEMD_MinOffset_MCPA "MCPA AEMD Min Offset";
CM_ SG_ 300 AEMD_MaxOffset_MCPB "MCPB AEMD Max Offset";
CM_ SG_ 300 AEMD_MaxOffset_MCPA "MCPA AEMD Max Offset";
CM_ SG_ 300 AEMD_Sclr_Gn_MCPB "MCPB AEMD Scalar Gain";
CM_ SG_ 300 AEMD_Sclr_Gn_MCPA "MCPA AEMD Scalar Gain";
CM_ SG_ 300 AEMD_Cutoff_FreqHigh_MCPB "AEMD cut-off Frequency High for MCPB";
CM_ SG_ 300 AEMD_Cutoff_FreqHigh_MCPA "AEMD cut-off Frequency High for MCPA";
CM_ SG_ 300 Pwr_Electronics_Loop_FlwRate_MCP "Inverter cooling liquid flow rate information";
CM_ SG_ 300 AEMD_Cutoff_FreqLow_MCPB "AEMD cut-off Frequency Low for MCPB";
CM_ SG_ 300 AEMD_Cutoff_FreqLow_MCPA "AEMD cut-off Frequency Low for MCPA";
CM_ SG_ 300 Pwr_Electronics_Loop_FlwRat_0000 "Inverter cooling liquid flow rate information";
CM_ SG_ 1063 MCPB_Temp "Motor B temperature";
CM_ SG_ 1063 MCPB_Rotor_Temperature "Rotor Temperature from Motor";
CM_ SG_ 1063 MCPB_Inverter_Temp "Inverter B Temperature";
CM_ SG_ 1063 MCPB_Control_Board_Temperature "Control Board temperature from Motor";
CM_ SG_ 1063 CLrDiagInfo_MCPB "Legislative Diagnostic Clear information for MCPB";
CM_ SG_ 1063 MessageCounter_MCPB_DATA2 "This signal is a counter used for safety checks strategies. This counter is incremented of 1 (one) unit at each frame transmission.";
CM_ SG_ 1063 CRC_MCPB_DATA2 "CRC according to SAE J1850 standard at each frame transmission.";
CM_ SG_ 1063 MCPB_PIM_DC_Side_Busbar_Temp "MCPB busbar temperature in DC side";
CM_ SG_ 1063 MCPB_Service_Lamp_Request_2 "The Service Light Request from the MCPB";
CM_ SG_ 292 MessageCounter_BATT_HV_STATUS1 "This signal is a counter used for safety checks strategies. This counter is incremented of 1 (one) unit at each frame transmission.";
CM_ SG_ 292 CRC_BATT_HV_STATUS1 "CRC according to SAE J1850 standard at each frame transmission.";
CM_ SG_ 292 BPCM_HV_TractionBusVoltage "Battery link traction bus voltage.";
CM_ SG_ 2654339273 GenericFailSts_FD16_SGCP "Indicates the presence/absent of at least one DTC in the System Memory";
CM_ SG_ 2654339273 EOL_FD16_SGCP "Indicates if the ECU requires configuration data at the assembly plant End Of Line";
CM_ SG_ 2654339273 CurrentFailSts_FD16_SGCP "Indicates the presence/absence of at least one DTC with DTCStatus = present in the System Memory";
CM_ SG_ 2654339161 EOL_FD16_MCPB "Indicates if the ECU requires configuration data at the assembly plant End Of Line";
CM_ SG_ 2654339161 GenericFailSts_FD16_MCPB "Indicates the presence/absent of at least one DTC in the System Memory";
CM_ SG_ 2654339161 CurrentFailSts_FD16_MCPB "Indicates the presence/absence of at least one DTC with DTCStatus = present in the System Memory";
CM_ SG_ 2654339160 EOL_FD16_MCPA "Indicates if the ECU requires configuration data at the assembly plant End Of Line";
CM_ SG_ 2654339160 GenericFailSts_FD16_MCPA "Indicates the presence/absent of at least one DTC in the System Memory";
CM_ SG_ 2654339160 CurrentFailSts_FD16_MCPA "Indicates the presence/absence of at least one DTC with DTCStatus = present in the System Memory";
CM_ SG_ 2564682364 N_PDU_18DDF27C "This signal is used for diagnostic purposes";
CM_ SG_ 2564485756 N_PDU_18DAF27C "This signal is used for diagnostic purposes";
CM_ SG_ 2564455666 N_PDU_18DA7CF2 "This signal is used for diagnostic purposes";
CM_ SG_ 243 SGCP_Torque_Achieved_V "Achieved Torque value Validity, [1] = True";
CM_ SG_ 243 SGCP_Torque_Achieved "SGCP Torque Achieved";
CM_ SG_ 243 SGCP_TorqAchieved_AEMD_V "Motor Torque Achieved Validity";
CM_ SG_ 243 SGCP_TorqAchieved_AEMD "SGCP Torque Achieved";
CM_ SG_ 243 SGCP_SPT_Stat "Inverter Isolation Status";
CM_ SG_ 243 SGCP_Spd_Lim "Limited motor speed during reduced performance from SGCP";
CM_ SG_ 243 SGCP_RPM_V "SGCP Speed Validity, [1] = True";
CM_ SG_ 243 SGCP_RPM "SGCP Speed Raw";
CM_ SG_ 243 SGCP_MtrMinCpbltyTrq "SGCP Min Capability Torque";
CM_ SG_ 243 SGCP_MtrMaxCpbltyTrq "SGCP Max Capability Torque";
CM_ SG_ 243 SGCP_MtrIndex "SGCP Capability Curve Array Index";
CM_ SG_ 243 SGCP_MinTorq "Motor A Minimum Torque";
CM_ SG_ 243 SGCP_MaxTorq "SGCP Maximum Torque";
CM_ SG_ 243 SGCP_Invrtr_State "Inverter State of Operation of SGCP";
CM_ SG_ 243 SGCP_InterlockSts "SGCP interlock state";
CM_ SG_ 243 SGCP_HV_CnctrOpn_Req "HV Battery pack contactor request";
CM_ SG_ 243 SGCP_Dschrge_Status "The active discharge status of SGCP";
CM_ SG_ 243 SGCP_DeratingFactor "SGCP Derating Factor";
CM_ SG_ 243 SGCP_DerateReason "Inverter Derating Reason";
CM_ SG_ 243 SGCP_DC_Voltage "SGCP DC Voltage.";
CM_ SG_ 243 SGCP_DC_Volt_V "SGCP DC current  validity, [1] = True";
CM_ SG_ 243 SGCP_DC_Current_V "SGCP DC current  validity, [1] = True";
CM_ SG_ 243 SGCP_DC_Current "SGCP DC Current";
CM_ SG_ 243 SGCP_CpbltySpdDivVolt "SGCP Speed at Capability Curve";
CM_ SG_ 243 SGCP_Comm_Fail_CAN "Communication fault on CAN detected by SGCP.";
CM_ SG_ 243 SGCP_AccelRawV "SGCP Acceleration Validity";
CM_ SG_ 243 SGCP_AccelRaw "SGCP Acceleration";
CM_ SG_ 243 SGCP_6SO_Status "SGCP 6SO Status";
CM_ SG_ 243 SGCP_3PS_Pos "3 phase motor short possible from SGCP; True = [1]";
CM_ SG_ 243 MC_SGCP_PWT1 "Message counter according to SAE J1850 standard that has to be calculated from bit 63 to bit 8 at each frame transmission.";
CM_ SG_ 243 CRC_SGCP_PWT1 "CRC according to SAE J1850 standard that has to be calculated from bit 63 to bit 8 at each frame transmission.";
BA_DEF_ BO_  "CANFD_BRS" ENUM  "0","1";
BA_DEF_ BO_  "VFrameFormat" ENUM  "StandardCAN","ExtendedCAN","reserved","reserved","reserved","reserved","reserved","reserved","reserved","reserved","reserved","reserved","reserved","reserved","StandardCAN_FD","ExtendedCAN_FD";
BA_DEF_ BO_  "DiagConnection" HEX 0 65535;
BA_DEF_ BO_  "DiagState" ENUM  "No","Yes";
BA_DEF_ BO_  "NmAsrMessage" ENUM  "No","Yes";
BA_DEF_ BO_  "GenMsgDelayTime" INT 0 65535;
BA_DEF_ BO_  "GenMsgCycleTime" INT 0 65535;
BA_DEF_ BO_  "GenMsgCycleTimeFast" INT 0 65535;
BA_DEF_ BO_  "GenMsgStartDelayTime" INT 0 65535;
BA_DEF_ BO_  "GenMsgILSupport" ENUM  "No","Yes";
BA_DEF_ BO_  "GenMsgNrOfRepetition" INT 0 255;
BA_DEF_ BO_  "GenMsgSendType" ENUM  "Cyclic","NotUsed","NotUsed","NotUsed","NotUsed","NotUsed","NotUsed","NotUsed","NoMsgSendType";
BA_DEF_ BO_  "NmMessage" ENUM  "No","Yes";
BA_DEF_ BO_  "DiagResponse" ENUM  "No","Yes";
BA_DEF_ BO_  "Type" ENUM  "P","C","PE","COC","PE_Cntrl","E","E_Cntrl","OC","S","BAF","DC","EM","MM","ISO-TP","-";
BA_DEF_ BO_  "DiagRequest" ENUM  "No","Yes";
BA_DEF_ SG_  "GenSigTimeoutTime_TCM" INT 0 65535;
BA_DEF_ SG_  "GenSigTimeoutTime_SGCP" INT 0 65535;
BA_DEF_ SG_  "GenSigTimeoutTime_MCPB" INT 0 65535;
BA_DEF_ SG_  "GenSigTimeoutTime_MCPA" INT 0 65535;
BA_DEF_ SG_  "GenSigTimeoutTime_EVCU2" INT 0 65535;
BA_DEF_ SG_  "GenSigTimeoutTime_ECM" INT 0 65535;
BA_DEF_ SG_  "GenSigTimeoutTime_AGSM" INT 0 65535;
BA_DEF_ SG_  "GenSigSendType" ENUM  "NotUsed","OnWrite","OnWriteWithRepetition","OnChange","OnChangeWithRepetition","IfActive","IfActiveWithRepetition","NoSigSendType";
BA_DEF_ SG_  "GenSigInactiveValue" INT 0 2147483647;
BA_DEF_ SG_  "GenSigStartValue" INT 0 2147483647;
BA_DEF_ SG_  "SystemSignalLongSymbol" STRING ;
BA_DEF_DEF_  "CANFD_BRS" "0";
BA_DEF_DEF_  "VFrameFormat" "StandardCAN_FD";
BA_DEF_DEF_  "DiagConnection" 0;
BA_DEF_DEF_  "DiagState" "No";
BA_DEF_DEF_  "NmAsrMessage" "No";
BA_DEF_DEF_  "GenMsgDelayTime" 0;
BA_DEF_DEF_  "GenMsgCycleTime" 0;
BA_DEF_DEF_  "GenMsgCycleTimeFast" 0;
BA_DEF_DEF_  "GenMsgStartDelayTime" 0;
BA_DEF_DEF_  "GenMsgILSupport" "No";
BA_DEF_DEF_  "GenMsgNrOfRepetition" 0;
BA_DEF_DEF_  "GenMsgSendType" "NoMsgSendType";
BA_DEF_DEF_  "NmMessage" "No";
BA_DEF_DEF_  "DiagResponse" "No";
BA_DEF_DEF_  "Type" "-";
BA_DEF_DEF_  "DiagRequest" "No";
BA_DEF_DEF_  "GenSigTimeoutTime_TCM" 2500;
BA_DEF_DEF_  "GenSigTimeoutTime_SGCP" 2500;
BA_DEF_DEF_  "GenSigTimeoutTime_MCPB" 2500;
BA_DEF_DEF_  "GenSigTimeoutTime_MCPA" 2500;
BA_DEF_DEF_  "GenSigTimeoutTime_EVCU2" 2500;
BA_DEF_DEF_  "GenSigTimeoutTime_ECM" 2500;
BA_DEF_DEF_  "GenSigTimeoutTime_AGSM" 2500;
BA_DEF_DEF_  "GenSigSendType" "NoSigSendType";
BA_DEF_DEF_  "GenSigInactiveValue" 0;
BA_DEF_DEF_  "GenSigStartValue" 0;
BA_DEF_DEF_  "SystemSignalLongSymbol" "";
BA_ "GenMsgCycleTime" BO_ 262 10;
BA_ "CANFD_BRS" BO_ 262 1;
BA_ "Type" BO_ 262 1;
BA_ "GenMsgSendType" BO_ 262 0;
BA_ "GenMsgILSupport" BO_ 262 1;
BA_ "GenMsgCycleTime" BO_ 258 10;
BA_ "CANFD_BRS" BO_ 258 1;
BA_ "Type" BO_ 258 1;
BA_ "GenMsgSendType" BO_ 258 0;
BA_ "GenMsgILSupport" BO_ 258 1;
BA_ "Type" BO_ 476 3;
BA_ "GenMsgSendType" BO_ 476 0;
BA_ "GenMsgNrOfRepetition" BO_ 476 2;
BA_ "GenMsgILSupport" BO_ 476 1;
BA_ "GenMsgCycleTimeFast" BO_ 476 20;
BA_ "GenMsgCycleTime" BO_ 476 20;
BA_ "GenMsgDelayTime" BO_ 476 15;
BA_ "CANFD_BRS" BO_ 476 1;
BA_ "Type" BO_ 242 1;
BA_ "GenMsgSendType" BO_ 242 0;
BA_ "GenMsgILSupport" BO_ 242 1;
BA_ "GenMsgCycleTime" BO_ 242 10;
BA_ "CANFD_BRS" BO_ 242 1;
BA_ "Type" BO_ 2654486617 8;
BA_ "NmMessage" BO_ 2654486617 1;
BA_ "NmAsrMessage" BO_ 2654486617 1;
BA_ "CANFD_BRS" BO_ 2654486617 1;
BA_ "VFrameFormat" BO_ 2654486617 15;
BA_ "Type" BO_ 2654486616 8;
BA_ "NmMessage" BO_ 2654486616 1;
BA_ "NmAsrMessage" BO_ 2654486616 1;
BA_ "CANFD_BRS" BO_ 2654486616 1;
BA_ "VFrameFormat" BO_ 2654486616 15;
BA_ "Type" BO_ 2564682261 8;
BA_ "DiagResponse" BO_ 2564682261 1;
BA_ "DiagConnection" BO_ 2564682261 61973;
BA_ "CANFD_BRS" BO_ 2564682261 1;
BA_ "VFrameFormat" BO_ 2564682261 15;
BA_ "Type" BO_ 2564682260 8;
BA_ "DiagResponse" BO_ 2564682260 1;
BA_ "DiagConnection" BO_ 2564682260 61972;
BA_ "CANFD_BRS" BO_ 2564682260 1;
BA_ "VFrameFormat" BO_ 2564682260 15;
BA_ "Type" BO_ 2564485396 8;
BA_ "DiagResponse" BO_ 2564485396 1;
BA_ "DiagConnection" BO_ 2564485396 61716;
BA_ "VFrameFormat" BO_ 2564485396 1;
BA_ "Type" BO_ 2564485653 8;
BA_ "DiagResponse" BO_ 2564485653 1;
BA_ "DiagConnection" BO_ 2564485653 61973;
BA_ "CANFD_BRS" BO_ 2564485653 1;
BA_ "VFrameFormat" BO_ 2564485653 15;
BA_ "Type" BO_ 2564485652 8;
BA_ "DiagResponse" BO_ 2564485652 1;
BA_ "DiagConnection" BO_ 2564485652 61972;
BA_ "CANFD_BRS" BO_ 2564485652 1;
BA_ "VFrameFormat" BO_ 2564485652 15;
BA_ "DiagRequest" BO_ 2564429297 1;
BA_ "Type" BO_ 2564429297 8;
BA_ "DiagConnection" BO_ 2564429297 61717;
BA_ "VFrameFormat" BO_ 2564429297 1;
BA_ "DiagRequest" BO_ 2564429298 1;
BA_ "Type" BO_ 2564429298 8;
BA_ "DiagConnection" BO_ 2564429298 61973;
BA_ "CANFD_BRS" BO_ 2564429298 1;
BA_ "VFrameFormat" BO_ 2564429298 15;
BA_ "DiagRequest" BO_ 2564429042 1;
BA_ "Type" BO_ 2564429042 8;
BA_ "DiagConnection" BO_ 2564429042 61972;
BA_ "CANFD_BRS" BO_ 2564429042 1;
BA_ "VFrameFormat" BO_ 2564429042 15;
BA_ "Type" BO_ 2651930713 11;
BA_ "GenMsgILSupport" BO_ 2651930713 1;
BA_ "CANFD_BRS" BO_ 2651930713 1;
BA_ "VFrameFormat" BO_ 2651930713 15;
BA_ "Type" BO_ 2651930712 11;
BA_ "GenMsgILSupport" BO_ 2651930712 1;
BA_ "CANFD_BRS" BO_ 2651930712 1;
BA_ "VFrameFormat" BO_ 2651930712 15;
BA_ "Type" BO_ 496 1;
BA_ "GenMsgSendType" BO_ 496 0;
BA_ "GenMsgILSupport" BO_ 496 1;
BA_ "GenMsgCycleTime" BO_ 496 10;
BA_ "CANFD_BRS" BO_ 496 1;
BA_ "GenMsgSendType" BO_ 1454 0;
BA_ "GenMsgNrOfRepetition" BO_ 1454 3;
BA_ "GenMsgILSupport" BO_ 1454 1;
BA_ "GenMsgCycleTimeFast" BO_ 1454 20;
BA_ "GenMsgCycleTime" BO_ 1454 1000;
BA_ "GenMsgDelayTime" BO_ 1454 20;
BA_ "CANFD_BRS" BO_ 1454 1;
BA_ "Type" BO_ 1454 3;
BA_ "Type" BO_ 1444 3;
BA_ "GenMsgSendType" BO_ 1444 0;
BA_ "GenMsgNrOfRepetition" BO_ 1444 3;
BA_ "GenMsgILSupport" BO_ 1444 1;
BA_ "GenMsgCycleTimeFast" BO_ 1444 20;
BA_ "GenMsgCycleTime" BO_ 1444 1000;
BA_ "GenMsgDelayTime" BO_ 1444 20;
BA_ "CANFD_BRS" BO_ 1444 1;
BA_ "Type" BO_ 105 3;
BA_ "GenMsgSendType" BO_ 105 0;
BA_ "GenMsgILSupport" BO_ 105 1;
BA_ "GenMsgCycleTime" BO_ 105 1000;
BA_ "GenMsgDelayTime" BO_ 105 100;
BA_ "CANFD_BRS" BO_ 105 1;
BA_ "Type" BO_ 260 1;
BA_ "GenMsgSendType" BO_ 260 0;
BA_ "GenMsgILSupport" BO_ 260 1;
BA_ "GenMsgCycleTime" BO_ 260 10;
BA_ "CANFD_BRS" BO_ 260 1;
BA_ "Type" BO_ 1062 1;
BA_ "GenMsgSendType" BO_ 1062 0;
BA_ "GenMsgILSupport" BO_ 1062 1;
BA_ "GenMsgCycleTime" BO_ 1062 100;
BA_ "CANFD_BRS" BO_ 1062 1;
BA_ "Type" BO_ 300 1;
BA_ "GenMsgSendType" BO_ 300 0;
BA_ "GenMsgILSupport" BO_ 300 1;
BA_ "GenMsgCycleTime" BO_ 300 10;
BA_ "CANFD_BRS" BO_ 300 1;
BA_ "Type" BO_ 1063 1;
BA_ "GenMsgSendType" BO_ 1063 0;
BA_ "GenMsgILSupport" BO_ 1063 1;
BA_ "GenMsgCycleTime" BO_ 1063 100;
BA_ "CANFD_BRS" BO_ 1063 1;
BA_ "Type" BO_ 292 1;
BA_ "GenMsgSendType" BO_ 292 0;
BA_ "GenMsgILSupport" BO_ 292 1;
BA_ "GenMsgCycleTime" BO_ 292 10;
BA_ "CANFD_BRS" BO_ 292 1;
BA_ "Type" BO_ 2654339273 1;
BA_ "GenMsgSendType" BO_ 2654339273 0;
BA_ "GenMsgILSupport" BO_ 2654339273 1;
BA_ "GenMsgCycleTime" BO_ 2654339273 1000;
BA_ "CANFD_BRS" BO_ 2654339273 1;
BA_ "VFrameFormat" BO_ 2654339273 15;
BA_ "Type" BO_ 2654339161 1;
BA_ "GenMsgSendType" BO_ 2654339161 0;
BA_ "GenMsgILSupport" BO_ 2654339161 1;
BA_ "GenMsgCycleTime" BO_ 2654339161 1000;
BA_ "CANFD_BRS" BO_ 2654339161 1;
BA_ "VFrameFormat" BO_ 2654339161 15;
BA_ "Type" BO_ 2654339160 1;
BA_ "GenMsgSendType" BO_ 2654339160 0;
BA_ "GenMsgILSupport" BO_ 2654339160 1;
BA_ "GenMsgCycleTime" BO_ 2654339160 1000;
BA_ "CANFD_BRS" BO_ 2654339160 1;
BA_ "VFrameFormat" BO_ 2654339160 15;
BA_ "Type" BO_ 2564682364 8;
BA_ "DiagResponse" BO_ 2564682364 1;
BA_ "DiagConnection" BO_ 2564682364 62076;
BA_ "CANFD_BRS" BO_ 2564682364 1;
BA_ "VFrameFormat" BO_ 2564682364 15;
BA_ "Type" BO_ 2564485756 8;
BA_ "DiagResponse" BO_ 2564485756 1;
BA_ "DiagConnection" BO_ 2564485756 62076;
BA_ "CANFD_BRS" BO_ 2564485756 1;
BA_ "VFrameFormat" BO_ 2564485756 15;
BA_ "DiagRequest" BO_ 2564455666 1;
BA_ "Type" BO_ 2564455666 8;
BA_ "DiagConnection" BO_ 2564455666 62076;
BA_ "CANFD_BRS" BO_ 2564455666 1;
BA_ "VFrameFormat" BO_ 2564455666 15;
BA_ "Type" BO_ 243 1;
BA_ "GenMsgSendType" BO_ 243 0;
BA_ "GenMsgILSupport" BO_ 243 1;
BA_ "GenMsgCycleTime" BO_ 243 10;
BA_ "CANFD_BRS" BO_ 243 1;
BA_ "GenSigTimeoutTime_AGSM" SG_ 262 TxAC_EMCC_rq_W 0;
BA_ "GenSigTimeoutTime_ECM" SG_ 262 TxAC_EMCC_rq_W 0;
BA_ "GenSigTimeoutTime_EVCU2" SG_ 262 TxAC_EMCC_rq_W 0;
BA_ "GenSigTimeoutTime_MCPA" SG_ 262 TxAC_EMCC_rq_W 0;
BA_ "GenSigTimeoutTime_MCPB" SG_ 262 TxAC_EMCC_rq_W 0;
BA_ "GenSigTimeoutTime_SGCP" SG_ 262 TxAC_EMCC_rq_W 0;
BA_ "GenSigTimeoutTime_AGSM" SG_ 262 TRANS_CLU_SLIP_MODE_W 0;
BA_ "GenSigTimeoutTime_ECM" SG_ 262 TRANS_CLU_SLIP_MODE_W 0;
BA_ "GenSigTimeoutTime_EVCU2" SG_ 262 TRANS_CLU_SLIP_MODE_W 0;
BA_ "GenSigTimeoutTime_MCPA" SG_ 262 TRANS_CLU_SLIP_MODE_W 0;
BA_ "GenSigTimeoutTime_MCPB" SG_ 262 TRANS_CLU_SLIP_MODE_W 0;
BA_ "GenSigTimeoutTime_SGCP" SG_ 262 TRANS_CLU_SLIP_MODE_W 0;
BA_ "GenSigTimeoutTime_AGSM" SG_ 262 PowertrainPrplsnActv 0;
BA_ "GenSigTimeoutTime_ECM" SG_ 262 PowertrainPrplsnActv 0;
BA_ "GenSigTimeoutTime_EVCU2" SG_ 262 PowertrainPrplsnActv 0;
BA_ "GenSigTimeoutTime_MCPA" SG_ 262 PowertrainPrplsnActv 0;
BA_ "GenSigTimeoutTime_MCPB" SG_ 262 PowertrainPrplsnActv 0;
BA_ "GenSigTimeoutTime_SGCP" SG_ 262 PowertrainPrplsnActv 0;
BA_ "GenSigTimeoutTime_TCM" SG_ 262 PowertrainPrplsnActv 0;
BA_ "GenSigTimeoutTime_AGSM" SG_ 262 MessageCounter_ENGINE2 0;
BA_ "GenSigTimeoutTime_ECM" SG_ 262 MessageCounter_ENGINE2 0;
BA_ "GenSigTimeoutTime_MCPA" SG_ 262 MessageCounter_ENGINE2 0;
BA_ "GenSigTimeoutTime_MCPB" SG_ 262 MessageCounter_ENGINE2 0;
BA_ "GenSigTimeoutTime_SGCP" SG_ 262 MessageCounter_ENGINE2 0;
BA_ "GenSigTimeoutTime_EVCU2" SG_ 262 MessageCounter_ENGINE2 0;
BA_ "GenSigTimeoutTime_AGSM" SG_ 262 LV12PwrFreeRq_W 0;
BA_ "GenSigTimeoutTime_ECM" SG_ 262 LV12PwrFreeRq_W 0;
BA_ "GenSigTimeoutTime_MCPA" SG_ 262 LV12PwrFreeRq_W 0;
BA_ "GenSigTimeoutTime_MCPB" SG_ 262 LV12PwrFreeRq_W 0;
BA_ "GenSigTimeoutTime_SGCP" SG_ 262 LV12PwrFreeRq_W 0;
BA_ "GenSigTimeoutTime_EVCU2" SG_ 262 LV12PwrFreeRq_W 0;
BA_ "GenSigTimeoutTime_AGSM" SG_ 262 KickDownRequest_W 0;
BA_ "GenSigTimeoutTime_ECM" SG_ 262 KickDownRequest_W 0;
BA_ "GenSigTimeoutTime_EVCU2" SG_ 262 KickDownRequest_W 0;
BA_ "GenSigTimeoutTime_MCPA" SG_ 262 KickDownRequest_W 0;
BA_ "GenSigTimeoutTime_MCPB" SG_ 262 KickDownRequest_W 0;
BA_ "GenSigTimeoutTime_SGCP" SG_ 262 KickDownRequest_W 0;
BA_ "GenSigStartValue" SG_ 262 IntakeAirTemperature_W 65;
BA_ "GenSigTimeoutTime_AGSM" SG_ 262 IntakeAirTemperature_W 0;
BA_ "GenSigTimeoutTime_ECM" SG_ 262 IntakeAirTemperature_W 0;
BA_ "GenSigTimeoutTime_EVCU2" SG_ 262 IntakeAirTemperature_W 0;
BA_ "GenSigTimeoutTime_MCPA" SG_ 262 IntakeAirTemperature_W 0;
BA_ "GenSigTimeoutTime_MCPB" SG_ 262 IntakeAirTemperature_W 0;
BA_ "GenSigTimeoutTime_SGCP" SG_ 262 IntakeAirTemperature_W 0;
BA_ "GenSigTimeoutTime_AGSM" SG_ 262 GasPedalPositionFailSts_W 0;
BA_ "GenSigTimeoutTime_ECM" SG_ 262 GasPedalPositionFailSts_W 0;
BA_ "GenSigTimeoutTime_EVCU2" SG_ 262 GasPedalPositionFailSts_W 0;
BA_ "GenSigTimeoutTime_MCPA" SG_ 262 GasPedalPositionFailSts_W 0;
BA_ "GenSigTimeoutTime_MCPB" SG_ 262 GasPedalPositionFailSts_W 0;
BA_ "GenSigTimeoutTime_SGCP" SG_ 262 GasPedalPositionFailSts_W 0;
BA_ "GenSigTimeoutTime_AGSM" SG_ 262 GasPedalPosition_W 0;
BA_ "GenSigTimeoutTime_ECM" SG_ 262 GasPedalPosition_W 0;
BA_ "GenSigTimeoutTime_EVCU2" SG_ 262 GasPedalPosition_W 0;
BA_ "GenSigTimeoutTime_MCPA" SG_ 262 GasPedalPosition_W 0;
BA_ "GenSigTimeoutTime_MCPB" SG_ 262 GasPedalPosition_W 0;
BA_ "GenSigTimeoutTime_SGCP" SG_ 262 GasPedalPosition_W 0;
BA_ "GenSigTimeoutTime_TCM" SG_ 262 ESS_RqShftPark_W 0;
BA_ "GenSigTimeoutTime_AGSM" SG_ 262 ESS_RqShftPark_W 0;
BA_ "GenSigTimeoutTime_ECM" SG_ 262 ESS_RqShftPark_W 0;
BA_ "GenSigTimeoutTime_EVCU2" SG_ 262 ESS_RqShftPark_W 0;
BA_ "GenSigTimeoutTime_MCPA" SG_ 262 ESS_RqShftPark_W 0;
BA_ "GenSigTimeoutTime_MCPB" SG_ 262 ESS_RqShftPark_W 0;
BA_ "GenSigTimeoutTime_SGCP" SG_ 262 ESS_RqShftPark_W 0;
BA_ "GenSigStartValue" SG_ 262 ESS_ENG_ST_W 15;
BA_ "GenSigSendType" SG_ 262 ESS_ENG_ST_W 3;
BA_ "GenSigTimeoutTime_AGSM" SG_ 262 ESS_ENG_ST_W 0;
BA_ "GenSigTimeoutTime_ECM" SG_ 262 ESS_ENG_ST_W 0;
BA_ "GenSigTimeoutTime_EVCU2" SG_ 262 ESS_ENG_ST_W 0;
BA_ "GenSigTimeoutTime_MCPA" SG_ 262 ESS_ENG_ST_W 0;
BA_ "GenSigTimeoutTime_MCPB" SG_ 262 ESS_ENG_ST_W 0;
BA_ "GenSigTimeoutTime_SGCP" SG_ 262 ESS_ENG_ST_W 0;
BA_ "GenSigTimeoutTime_EVCU2" SG_ 262 EngTrq_Enbl_Rq_TCM_W 0;
BA_ "GenSigTimeoutTime_AGSM" SG_ 262 EngTrq_Enbl_Rq_TCM_W 0;
BA_ "GenSigTimeoutTime_ECM" SG_ 262 EngTrq_Enbl_Rq_TCM_W 0;
BA_ "GenSigTimeoutTime_MCPA" SG_ 262 EngTrq_Enbl_Rq_TCM_W 0;
BA_ "GenSigTimeoutTime_MCPB" SG_ 262 EngTrq_Enbl_Rq_TCM_W 0;
BA_ "GenSigTimeoutTime_SGCP" SG_ 262 EngTrq_Enbl_Rq_TCM_W 0;
BA_ "GenSigStartValue" SG_ 262 EngineSts_W 3;
BA_ "GenSigTimeoutTime_AGSM" SG_ 262 EngineSts_W 0;
BA_ "GenSigTimeoutTime_ECM" SG_ 262 EngineSts_W 0;
BA_ "GenSigTimeoutTime_MCPA" SG_ 262 EngineSts_W 0;
BA_ "GenSigTimeoutTime_MCPB" SG_ 262 EngineSts_W 0;
BA_ "GenSigTimeoutTime_SGCP" SG_ 262 EngineSts_W 0;
BA_ "GenSigTimeoutTime_EVCU2" SG_ 262 EngineSts_W 0;
BA_ "GenSigTimeoutTime_AGSM" SG_ 262 EngineSpeedFailSts_W 0;
BA_ "GenSigTimeoutTime_ECM" SG_ 262 EngineSpeedFailSts_W 0;
BA_ "GenSigTimeoutTime_EVCU2" SG_ 262 EngineSpeedFailSts_W 0;
BA_ "GenSigTimeoutTime_SGCP" SG_ 262 EngineSpeed_W 0;
BA_ "GenSigTimeoutTime_EVCU2" SG_ 262 EngineSpeed_W 0;
BA_ "GenSigTimeoutTime_AGSM" SG_ 262 EngineSpeed_W 0;
BA_ "GenSigTimeoutTime_ECM" SG_ 262 EngineSpeed_W 0;
BA_ "GenSigTimeoutTime_MCPA" SG_ 262 EngineSpeed_W 0;
BA_ "GenSigTimeoutTime_MCPB" SG_ 262 EngineSpeed_W 0;
BA_ "GenSigTimeoutTime_EVCU2" SG_ 262 EngineIdleRefSpeed 0;
BA_ "GenSigTimeoutTime_AGSM" SG_ 262 EngineIdleRefSpeed 0;
BA_ "GenSigTimeoutTime_ECM" SG_ 262 EngineIdleRefSpeed 0;
BA_ "GenSigTimeoutTime_MCPA" SG_ 262 EngineIdleRefSpeed 0;
BA_ "GenSigTimeoutTime_MCPB" SG_ 262 EngineIdleRefSpeed 0;
BA_ "GenSigTimeoutTime_SGCP" SG_ 262 EngineIdleRefSpeed 0;
BA_ "GenSigTimeoutTime_EVCU2" SG_ 262 EngineFrictionTorque_W 0;
BA_ "GenSigTimeoutTime_AGSM" SG_ 262 EngineFrictionTorque_W 0;
BA_ "GenSigTimeoutTime_ECM" SG_ 262 EngineFrictionTorque_W 0;
BA_ "GenSigTimeoutTime_MCPA" SG_ 262 EngineFrictionTorque_W 0;
BA_ "GenSigTimeoutTime_MCPB" SG_ 262 EngineFrictionTorque_W 0;
BA_ "GenSigTimeoutTime_SGCP" SG_ 262 EngineFrictionTorque_W 0;
BA_ "GenSigTimeoutTime_TCM" SG_ 262 EngineFrictionTorque_W 0;
BA_ "GenSigTimeoutTime_EVCU2" SG_ 262 ECM_LHOM_W 0;
BA_ "GenSigTimeoutTime_AGSM" SG_ 262 ECM_LHOM_W 0;
BA_ "GenSigTimeoutTime_ECM" SG_ 262 ECM_LHOM_W 0;
BA_ "GenSigTimeoutTime_MCPA" SG_ 262 ECM_LHOM_W 0;
BA_ "GenSigTimeoutTime_MCPB" SG_ 262 ECM_LHOM_W 0;
BA_ "GenSigTimeoutTime_SGCP" SG_ 262 ECM_LHOM_W 0;
BA_ "GenSigTimeoutTime_EVCU2" SG_ 262 ECM_LHOM_Trans_W 0;
BA_ "GenSigTimeoutTime_AGSM" SG_ 262 ECM_LHOM_Trans_W 0;
BA_ "GenSigTimeoutTime_ECM" SG_ 262 ECM_LHOM_Trans_W 0;
BA_ "GenSigTimeoutTime_MCPA" SG_ 262 ECM_LHOM_Trans_W 0;
BA_ "GenSigTimeoutTime_MCPB" SG_ 262 ECM_LHOM_Trans_W 0;
BA_ "GenSigTimeoutTime_SGCP" SG_ 262 ECM_LHOM_Trans_W 0;
BA_ "GenSigTimeoutTime_AGSM" SG_ 262 CRC_ENGINE2 0;
BA_ "GenSigTimeoutTime_ECM" SG_ 262 CRC_ENGINE2 0;
BA_ "GenSigTimeoutTime_MCPA" SG_ 262 CRC_ENGINE2 0;
BA_ "GenSigTimeoutTime_MCPB" SG_ 262 CRC_ENGINE2 0;
BA_ "GenSigTimeoutTime_SGCP" SG_ 262 CRC_ENGINE2 0;
BA_ "GenSigTimeoutTime_EVCU2" SG_ 262 CRC_ENGINE2 0;
BA_ "GenSigTimeoutTime_AGSM" SG_ 262 CrankHold_W 0;
BA_ "GenSigTimeoutTime_ECM" SG_ 262 CrankHold_W 0;
BA_ "GenSigTimeoutTime_EVCU2" SG_ 262 CrankHold_W 0;
BA_ "GenSigTimeoutTime_MCPA" SG_ 262 CrankHold_W 0;
BA_ "GenSigTimeoutTime_MCPB" SG_ 262 CrankHold_W 0;
BA_ "GenSigTimeoutTime_SGCP" SG_ 262 CrankHold_W 0;
BA_ "GenSigTimeoutTime_TCM" SG_ 262 CrankHold_W 0;
BA_ "GenSigTimeoutTime_AGSM" SG_ 262 ESS_EBOOST_BRKHLD_STATUS 0;
BA_ "GenSigTimeoutTime_ECM" SG_ 262 ESS_EBOOST_BRKHLD_STATUS 0;
BA_ "GenSigTimeoutTime_EVCU2" SG_ 262 ESS_EBOOST_BRKHLD_STATUS 0;
BA_ "GenSigTimeoutTime_MCPA" SG_ 262 ESS_EBOOST_BRKHLD_STATUS 0;
BA_ "GenSigTimeoutTime_MCPB" SG_ 262 ESS_EBOOST_BRKHLD_STATUS 0;
BA_ "GenSigTimeoutTime_TCM" SG_ 262 ESS_EBOOST_BRKHLD_STATUS 0;
BA_ "GenSigTimeoutTime_ECM" SG_ 262 Engine_Stall_Detected 0;
BA_ "GenSigTimeoutTime_MCPA" SG_ 262 Engine_Stall_Detected 0;
BA_ "GenSigTimeoutTime_MCPB" SG_ 262 Engine_Stall_Detected 0;
BA_ "GenSigTimeoutTime_SGCP" SG_ 262 Engine_Stall_Detected 0;
BA_ "GenSigTimeoutTime_TCM" SG_ 262 Engine_Stall_Detected 0;
BA_ "GenSigTimeoutTime_AGSM" SG_ 262 Engine_Stall_Detected 0;
BA_ "GenSigTimeoutTime_AGSM" SG_ 262 EssEngStrtIsNotAllwdID 0;
BA_ "GenSigTimeoutTime_ECM" SG_ 262 EssEngStrtIsNotAllwdID 0;
BA_ "GenSigTimeoutTime_MCPA" SG_ 262 EssEngStrtIsNotAllwdID 0;
BA_ "GenSigTimeoutTime_MCPB" SG_ 262 EssEngStrtIsNotAllwdID 0;
BA_ "GenSigTimeoutTime_SGCP" SG_ 262 EssEngStrtIsNotAllwdID 0;
BA_ "GenSigTimeoutTime_TCM" SG_ 262 EssEngStrtIsNotAllwdID 0;
BA_ "GenSigTimeoutTime_AGSM" SG_ 262 EssEngStrtIsNotAllwd 0;
BA_ "GenSigTimeoutTime_ECM" SG_ 262 EssEngStrtIsNotAllwd 0;
BA_ "GenSigTimeoutTime_MCPA" SG_ 262 EssEngStrtIsNotAllwd 0;
BA_ "GenSigTimeoutTime_MCPB" SG_ 262 EssEngStrtIsNotAllwd 0;
BA_ "GenSigTimeoutTime_SGCP" SG_ 262 EssEngStrtIsNotAllwd 0;
BA_ "GenSigTimeoutTime_TCM" SG_ 262 EssEngStrtIsNotAllwd 0;
BA_ "GenSigTimeoutTime_AGSM" SG_ 262 EssEngStopIsNotAllwdID 0;
BA_ "GenSigTimeoutTime_ECM" SG_ 262 EssEngStopIsNotAllwdID 0;
BA_ "GenSigTimeoutTime_MCPA" SG_ 262 EssEngStopIsNotAllwdID 0;
BA_ "GenSigTimeoutTime_MCPB" SG_ 262 EssEngStopIsNotAllwdID 0;
BA_ "GenSigTimeoutTime_SGCP" SG_ 262 EssEngStopIsNotAllwdID 0;
BA_ "GenSigTimeoutTime_TCM" SG_ 262 EssEngStopIsNotAllwdID 0;
BA_ "GenSigTimeoutTime_AGSM" SG_ 262 EssEngStopIsNotAllwd 0;
BA_ "GenSigTimeoutTime_ECM" SG_ 262 EssEngStopIsNotAllwd 0;
BA_ "GenSigTimeoutTime_MCPA" SG_ 262 EssEngStopIsNotAllwd 0;
BA_ "GenSigTimeoutTime_MCPB" SG_ 262 EssEngStopIsNotAllwd 0;
BA_ "GenSigTimeoutTime_SGCP" SG_ 262 EssEngStopIsNotAllwd 0;
BA_ "GenSigTimeoutTime_TCM" SG_ 262 EssEngStopIsNotAllwd 0;
BA_ "GenSigTimeoutTime_AGSM" SG_ 262 EssEngSt 0;
BA_ "GenSigTimeoutTime_ECM" SG_ 262 EssEngSt 0;
BA_ "GenSigTimeoutTime_MCPA" SG_ 262 EssEngSt 0;
BA_ "GenSigTimeoutTime_MCPB" SG_ 262 EssEngSt 0;
BA_ "GenSigTimeoutTime_SGCP" SG_ 262 EssEngSt 0;
BA_ "GenSigTimeoutTime_TCM" SG_ 262 EssEngSt 0;
BA_ "GenSigTimeoutTime_AGSM" SG_ 262 EssEngModReq 0;
BA_ "GenSigTimeoutTime_ECM" SG_ 262 EssEngModReq 0;
BA_ "GenSigTimeoutTime_MCPA" SG_ 262 EssEngModReq 0;
BA_ "GenSigTimeoutTime_MCPB" SG_ 262 EssEngModReq 0;
BA_ "GenSigTimeoutTime_SGCP" SG_ 262 EssEngModReq 0;
BA_ "GenSigTimeoutTime_TCM" SG_ 262 EssEngModReq 0;
BA_ "GenSigTimeoutTime_AGSM" SG_ 262 CompressionTest 0;
BA_ "GenSigTimeoutTime_ECM" SG_ 262 CompressionTest 0;
BA_ "GenSigTimeoutTime_MCPA" SG_ 262 CompressionTest 0;
BA_ "GenSigTimeoutTime_MCPB" SG_ 262 CompressionTest 0;
BA_ "GenSigTimeoutTime_SGCP" SG_ 262 CompressionTest 0;
BA_ "GenSigTimeoutTime_TCM" SG_ 262 CompressionTest 0;
BA_ "GenSigTimeoutTime_AGSM" SG_ 258 VehicleSpeedVSOSig 0;
BA_ "GenSigTimeoutTime_ECM" SG_ 258 VehicleSpeedVSOSig 0;
BA_ "GenSigTimeoutTime_EVCU2" SG_ 258 VehicleSpeedVSOSig 0;
BA_ "GenSigTimeoutTime_TCM" SG_ 258 VehicleSpeedVSOSig 0;
BA_ "GenSigTimeoutTime_AGSM" SG_ 258 MessageCounter_BRAKE2 0;
BA_ "GenSigTimeoutTime_ECM" SG_ 258 MessageCounter_BRAKE2 0;
BA_ "GenSigTimeoutTime_EVCU2" SG_ 258 MessageCounter_BRAKE2 0;
BA_ "GenSigTimeoutTime_SGCP" SG_ 258 MessageCounter_BRAKE2 0;
BA_ "GenSigTimeoutTime_TCM" SG_ 258 MessageCounter_BRAKE2 0;
BA_ "GenSigTimeoutTime_AGSM" SG_ 258 LongAccelerationFailSts_BSM 0;
BA_ "GenSigTimeoutTime_ECM" SG_ 258 LongAccelerationFailSts_BSM 0;
BA_ "GenSigTimeoutTime_EVCU2" SG_ 258 LongAccelerationFailSts_BSM 0;
BA_ "GenSigTimeoutTime_SGCP" SG_ 258 LongAccelerationFailSts_BSM 0;
BA_ "GenSigTimeoutTime_TCM" SG_ 258 LongAccelerationFailSts_BSM 0;
BA_ "GenSigTimeoutTime_SGCP" SG_ 258 LongAcceleration_BSM 0;
BA_ "GenSigTimeoutTime_TCM" SG_ 258 LongAcceleration_BSM 0;
BA_ "GenSigStartValue" SG_ 258 LongAcceleration_BSM 4095;
BA_ "GenSigTimeoutTime_AGSM" SG_ 258 LongAcceleration_BSM 0;
BA_ "GenSigTimeoutTime_ECM" SG_ 258 LongAcceleration_BSM 0;
BA_ "GenSigTimeoutTime_EVCU2" SG_ 258 LongAcceleration_BSM 0;
BA_ "GenSigTimeoutTime_AGSM" SG_ 258 LatAccelerationFailSts_BSM 0;
BA_ "GenSigTimeoutTime_ECM" SG_ 258 LatAccelerationFailSts_BSM 0;
BA_ "GenSigTimeoutTime_EVCU2" SG_ 258 LatAccelerationFailSts_BSM 0;
BA_ "GenSigTimeoutTime_SGCP" SG_ 258 LatAccelerationFailSts_BSM 0;
BA_ "GenSigTimeoutTime_TCM" SG_ 258 LatAccelerationFailSts_BSM 0;
BA_ "GenSigStartValue" SG_ 258 LatAcceleration_BSM 4095;
BA_ "GenSigTimeoutTime_AGSM" SG_ 258 LatAcceleration_BSM 0;
BA_ "GenSigTimeoutTime_ECM" SG_ 258 LatAcceleration_BSM 0;
BA_ "GenSigTimeoutTime_EVCU2" SG_ 258 LatAcceleration_BSM 0;
BA_ "GenSigTimeoutTime_SGCP" SG_ 258 LatAcceleration_BSM 0;
BA_ "GenSigTimeoutTime_TCM" SG_ 258 LatAcceleration_BSM 0;
BA_ "GenSigTimeoutTime_AGSM" SG_ 258 ESCActive 0;
BA_ "GenSigTimeoutTime_ECM" SG_ 258 ESCActive 0;
BA_ "GenSigTimeoutTime_EVCU2" SG_ 258 ESCActive 0;
BA_ "GenSigTimeoutTime_SGCP" SG_ 258 ESCActive 0;
BA_ "GenSigTimeoutTime_TCM" SG_ 258 ESCActive 0;
BA_ "GenSigTimeoutTime_AGSM" SG_ 258 CRC_BRAKE2 0;
BA_ "GenSigTimeoutTime_ECM" SG_ 258 CRC_BRAKE2 0;
BA_ "GenSigTimeoutTime_EVCU2" SG_ 258 CRC_BRAKE2 0;
BA_ "GenSigTimeoutTime_SGCP" SG_ 258 CRC_BRAKE2 0;
BA_ "GenSigTimeoutTime_TCM" SG_ 258 CRC_BRAKE2 0;
BA_ "GenSigTimeoutTime_AGSM" SG_ 258 ABSActive 0;
BA_ "GenSigTimeoutTime_ECM" SG_ 258 ABSActive 0;
BA_ "GenSigTimeoutTime_EVCU2" SG_ 258 ABSActive 0;
BA_ "GenSigTimeoutTime_SGCP" SG_ 258 ABSActive 0;
BA_ "GenSigTimeoutTime_TCM" SG_ 258 ABSActive 0;
BA_ "GenSigTimeoutTime_AGSM" SG_ 476 ShiftLockFailSts 0;
BA_ "GenSigTimeoutTime_ECM" SG_ 476 ShiftLockFailSts 0;
BA_ "GenSigTimeoutTime_EVCU2" SG_ 476 ShiftLockFailSts 0;
BA_ "GenSigTimeoutTime_MCPA" SG_ 476 ShiftLockFailSts 0;
BA_ "GenSigTimeoutTime_MCPB" SG_ 476 ShiftLockFailSts 0;
BA_ "GenSigTimeoutTime_SGCP" SG_ 476 ShiftLockFailSts 0;
BA_ "GenSigTimeoutTime_AGSM" SG_ 476 PRNDFailSts 0;
BA_ "GenSigTimeoutTime_ECM" SG_ 476 PRNDFailSts 0;
BA_ "GenSigTimeoutTime_MCPA" SG_ 476 PRNDFailSts 0;
BA_ "GenSigTimeoutTime_MCPB" SG_ 476 PRNDFailSts 0;
BA_ "GenSigTimeoutTime_SGCP" SG_ 476 PRNDFailSts 0;
BA_ "GenSigTimeoutTime_AGSM" SG_ 476 PRNDdisplayFailSts 0;
BA_ "GenSigTimeoutTime_ECM" SG_ 476 PRNDdisplayFailSts 0;
BA_ "GenSigTimeoutTime_MCPA" SG_ 476 PRNDdisplayFailSts 0;
BA_ "GenSigTimeoutTime_MCPB" SG_ 476 PRNDdisplayFailSts 0;
BA_ "GenSigTimeoutTime_SGCP" SG_ 476 PRNDdisplayFailSts 0;
BA_ "GenSigTimeoutTime_AGSM" SG_ 476 MessageCounter_AGSM2 0;
BA_ "GenSigTimeoutTime_ECM" SG_ 476 MessageCounter_AGSM2 0;
BA_ "GenSigTimeoutTime_EVCU2" SG_ 476 MessageCounter_AGSM2 0;
BA_ "GenSigTimeoutTime_MCPA" SG_ 476 MessageCounter_AGSM2 0;
BA_ "GenSigTimeoutTime_MCPB" SG_ 476 MessageCounter_AGSM2 0;
BA_ "GenSigTimeoutTime_SGCP" SG_ 476 MessageCounter_AGSM2 0;
BA_ "GenSigTimeoutTime_AGSM" SG_ 476 CRC_AGSM2 0;
BA_ "GenSigTimeoutTime_ECM" SG_ 476 CRC_AGSM2 0;
BA_ "GenSigTimeoutTime_EVCU2" SG_ 476 CRC_AGSM2 0;
BA_ "GenSigTimeoutTime_MCPA" SG_ 476 CRC_AGSM2 0;
BA_ "GenSigTimeoutTime_MCPB" SG_ 476 CRC_AGSM2 0;
BA_ "GenSigTimeoutTime_SGCP" SG_ 476 CRC_AGSM2 0;
BA_ "GenSigTimeoutTime_AGSM" SG_ 476 APCM_Stat 0;
BA_ "GenSigTimeoutTime_ECM" SG_ 476 APCM_Stat 0;
BA_ "GenSigTimeoutTime_MCPA" SG_ 476 APCM_Stat 0;
BA_ "GenSigTimeoutTime_MCPB" SG_ 476 APCM_Stat 0;
BA_ "GenSigTimeoutTime_SGCP" SG_ 476 APCM_Stat 0;
BA_ "GenSigSendType" SG_ 476 SolenoidFlt 3;
BA_ "GenSigTimeoutTime_AGSM" SG_ 476 SolenoidFlt 0;
BA_ "GenSigTimeoutTime_ECM" SG_ 476 SolenoidFlt 0;
BA_ "GenSigTimeoutTime_EVCU2" SG_ 476 SolenoidFlt 0;
BA_ "GenSigTimeoutTime_MCPA" SG_ 476 SolenoidFlt 0;
BA_ "GenSigTimeoutTime_MCPB" SG_ 476 SolenoidFlt 0;
BA_ "GenSigTimeoutTime_SGCP" SG_ 476 SolenoidFlt 0;
BA_ "GenSigTimeoutTime_AGSM" SG_ 476 ShiftLever_PositionFlt 0;
BA_ "GenSigTimeoutTime_ECM" SG_ 476 ShiftLever_PositionFlt 0;
BA_ "GenSigTimeoutTime_EVCU2" SG_ 476 ShiftLever_PositionFlt 0;
BA_ "GenSigTimeoutTime_MCPA" SG_ 476 ShiftLever_PositionFlt 0;
BA_ "GenSigTimeoutTime_MCPB" SG_ 476 ShiftLever_PositionFlt 0;
BA_ "GenSigSendType" SG_ 476 Low_Mode_Req 3;
BA_ "GenSigTimeoutTime_AGSM" SG_ 476 Low_Mode_Req 0;
BA_ "GenSigTimeoutTime_ECM" SG_ 476 Low_Mode_Req 0;
BA_ "GenSigTimeoutTime_EVCU2" SG_ 476 Low_Mode_Req 0;
BA_ "GenSigTimeoutTime_MCPA" SG_ 476 Low_Mode_Req 0;
BA_ "GenSigTimeoutTime_MCPB" SG_ 476 Low_Mode_Req 0;
BA_ "GenSigSendType" SG_ 476 ShiftLeverPositionReq 3;
BA_ "GenSigTimeoutTime_AGSM" SG_ 476 ShiftLeverPositionReq 0;
BA_ "GenSigTimeoutTime_ECM" SG_ 476 ShiftLeverPositionReq 0;
BA_ "GenSigTimeoutTime_MCPA" SG_ 476 ShiftLeverPositionReq 0;
BA_ "GenSigTimeoutTime_SGCP" SG_ 476 ShiftLeverPositionReq 0;
BA_ "GenSigTimeoutTime_AGSM" SG_ 242 MC_PF1 0;
BA_ "GenSigTimeoutTime_ECM" SG_ 242 MC_PF1 0;
BA_ "GenSigTimeoutTime_MCPA" SG_ 242 MC_PF1 0;
BA_ "GenSigTimeoutTime_MCPB" SG_ 242 MC_PF1 0;
BA_ "GenSigTimeoutTime_SGCP" SG_ 242 MC_PF1 0;
BA_ "GenSigTimeoutTime_TCM" SG_ 242 MC_PF1 0;
BA_ "GenSigTimeoutTime_ECM" SG_ 242 INVFInterlockSts 0;
BA_ "GenSigTimeoutTime_MCPA" SG_ 242 INVFInterlockSts 0;
BA_ "GenSigTimeoutTime_MCPB" SG_ 242 INVFInterlockSts 0;
BA_ "GenSigTimeoutTime_SGCP" SG_ 242 INVFInterlockSts 0;
BA_ "GenSigTimeoutTime_TCM" SG_ 242 INVFInterlockSts 0;
BA_ "GenSigTimeoutTime_AGSM" SG_ 242 INVFInterlockSts 0;
BA_ "GenSigTimeoutTime_AGSM" SG_ 242 InvF_DC_Voltage 0;
BA_ "GenSigTimeoutTime_ECM" SG_ 242 InvF_DC_Voltage 0;
BA_ "GenSigTimeoutTime_MCPA" SG_ 242 InvF_DC_Voltage 0;
BA_ "GenSigTimeoutTime_MCPB" SG_ 242 InvF_DC_Voltage 0;
BA_ "GenSigTimeoutTime_SGCP" SG_ 242 InvF_DC_Voltage 0;
BA_ "GenSigTimeoutTime_TCM" SG_ 242 InvF_DC_Voltage 0;
BA_ "GenSigTimeoutTime_AGSM" SG_ 242 CRC_PF1 0;
BA_ "GenSigTimeoutTime_ECM" SG_ 242 CRC_PF1 0;
BA_ "GenSigTimeoutTime_MCPA" SG_ 242 CRC_PF1 0;
BA_ "GenSigTimeoutTime_MCPB" SG_ 242 CRC_PF1 0;
BA_ "GenSigTimeoutTime_SGCP" SG_ 242 CRC_PF1 0;
BA_ "GenSigTimeoutTime_TCM" SG_ 242 CRC_PF1 0;
BA_ "GenSigTimeoutTime_AGSM" SG_ 242 InvF_DerateReason 0;
BA_ "GenSigTimeoutTime_ECM" SG_ 242 InvF_DerateReason 0;
BA_ "GenSigTimeoutTime_MCPA" SG_ 242 InvF_DerateReason 0;
BA_ "GenSigTimeoutTime_MCPB" SG_ 242 InvF_DerateReason 0;
BA_ "GenSigTimeoutTime_SGCP" SG_ 242 InvF_DerateReason 0;
BA_ "GenSigTimeoutTime_TCM" SG_ 242 InvF_DerateReason 0;
BA_ "GenSigStartValue" SG_ 242 MCPA_Torque_Achieved 4096;
BA_ "GenSigTimeoutTime_AGSM" SG_ 242 MCPA_Torque_Achieved 0;
BA_ "GenSigTimeoutTime_ECM" SG_ 242 MCPA_Torque_Achieved 0;
BA_ "GenSigTimeoutTime_MCPA" SG_ 242 MCPA_Torque_Achieved 0;
BA_ "GenSigTimeoutTime_MCPB" SG_ 242 MCPA_Torque_Achieved 0;
BA_ "GenSigTimeoutTime_SGCP" SG_ 242 MCPA_Torque_Achieved 0;
BA_ "GenSigTimeoutTime_TCM" SG_ 242 MCPA_Torque_Achieved 0;
BA_ "GenSigTimeoutTime_AGSM" SG_ 242 MCPA_TorqAchieved_AEMD_V 0;
BA_ "GenSigTimeoutTime_ECM" SG_ 242 MCPA_TorqAchieved_AEMD_V 0;
BA_ "GenSigTimeoutTime_MCPA" SG_ 242 MCPA_TorqAchieved_AEMD_V 0;
BA_ "GenSigTimeoutTime_MCPB" SG_ 242 MCPA_TorqAchieved_AEMD_V 0;
BA_ "GenSigTimeoutTime_SGCP" SG_ 242 MCPA_TorqAchieved_AEMD_V 0;
BA_ "GenSigTimeoutTime_TCM" SG_ 242 MCPA_TorqAchieved_AEMD_V 0;
BA_ "GenSigStartValue" SG_ 242 MCPA_TorqAchieved_AEMD 4096;
BA_ "GenSigTimeoutTime_AGSM" SG_ 242 MCPA_TorqAchieved_AEMD 0;
BA_ "GenSigTimeoutTime_ECM" SG_ 242 MCPA_TorqAchieved_AEMD 0;
BA_ "GenSigTimeoutTime_MCPA" SG_ 242 MCPA_TorqAchieved_AEMD 0;
BA_ "GenSigTimeoutTime_MCPB" SG_ 242 MCPA_TorqAchieved_AEMD 0;
BA_ "GenSigTimeoutTime_SGCP" SG_ 242 MCPA_TorqAchieved_AEMD 0;
BA_ "GenSigTimeoutTime_TCM" SG_ 242 MCPA_TorqAchieved_AEMD 0;
BA_ "GenSigTimeoutTime_AGSM" SG_ 242 MCPA_Spd_Lim 0;
BA_ "GenSigTimeoutTime_ECM" SG_ 242 MCPA_Spd_Lim 0;
BA_ "GenSigTimeoutTime_MCPA" SG_ 242 MCPA_Spd_Lim 0;
BA_ "GenSigTimeoutTime_MCPB" SG_ 242 MCPA_Spd_Lim 0;
BA_ "GenSigTimeoutTime_SGCP" SG_ 242 MCPA_Spd_Lim 0;
BA_ "GenSigTimeoutTime_TCM" SG_ 242 MCPA_Spd_Lim 0;
BA_ "GenSigTimeoutTime_AGSM" SG_ 242 MCPA_RPM_V 0;
BA_ "GenSigTimeoutTime_ECM" SG_ 242 MCPA_RPM_V 0;
BA_ "GenSigTimeoutTime_MCPA" SG_ 242 MCPA_RPM_V 0;
BA_ "GenSigTimeoutTime_MCPB" SG_ 242 MCPA_RPM_V 0;
BA_ "GenSigTimeoutTime_SGCP" SG_ 242 MCPA_RPM_V 0;
BA_ "GenSigTimeoutTime_TCM" SG_ 242 MCPA_RPM_V 0;
BA_ "GenSigStartValue" SG_ 242 MCPA_RPM 32768;
BA_ "GenSigTimeoutTime_AGSM" SG_ 242 MCPA_RPM 0;
BA_ "GenSigTimeoutTime_ECM" SG_ 242 MCPA_RPM 0;
BA_ "GenSigTimeoutTime_MCPA" SG_ 242 MCPA_RPM 0;
BA_ "GenSigTimeoutTime_MCPB" SG_ 242 MCPA_RPM 0;
BA_ "GenSigTimeoutTime_SGCP" SG_ 242 MCPA_RPM 0;
BA_ "GenSigTimeoutTime_TCM" SG_ 242 MCPA_RPM 0;
BA_ "GenSigStartValue" SG_ 242 MCPA_MtrMinCpbltyTrq 4096;
BA_ "GenSigTimeoutTime_AGSM" SG_ 242 MCPA_MtrMinCpbltyTrq 0;
BA_ "GenSigTimeoutTime_ECM" SG_ 242 MCPA_MtrMinCpbltyTrq 0;
BA_ "GenSigTimeoutTime_MCPA" SG_ 242 MCPA_MtrMinCpbltyTrq 0;
BA_ "GenSigTimeoutTime_MCPB" SG_ 242 MCPA_MtrMinCpbltyTrq 0;
BA_ "GenSigTimeoutTime_SGCP" SG_ 242 MCPA_MtrMinCpbltyTrq 0;
BA_ "GenSigTimeoutTime_TCM" SG_ 242 MCPA_MtrMinCpbltyTrq 0;
BA_ "GenSigStartValue" SG_ 242 MCPA_MtrMaxCpbltyTrq 4096;
BA_ "GenSigTimeoutTime_AGSM" SG_ 242 MCPA_MtrMaxCpbltyTrq 0;
BA_ "GenSigTimeoutTime_ECM" SG_ 242 MCPA_MtrMaxCpbltyTrq 0;
BA_ "GenSigTimeoutTime_MCPA" SG_ 242 MCPA_MtrMaxCpbltyTrq 0;
BA_ "GenSigTimeoutTime_MCPB" SG_ 242 MCPA_MtrMaxCpbltyTrq 0;
BA_ "GenSigTimeoutTime_SGCP" SG_ 242 MCPA_MtrMaxCpbltyTrq 0;
BA_ "GenSigTimeoutTime_TCM" SG_ 242 MCPA_MtrMaxCpbltyTrq 0;
BA_ "GenSigTimeoutTime_AGSM" SG_ 242 MCPA_MtrIndex 0;
BA_ "GenSigTimeoutTime_ECM" SG_ 242 MCPA_MtrIndex 0;
BA_ "GenSigTimeoutTime_MCPA" SG_ 242 MCPA_MtrIndex 0;
BA_ "GenSigTimeoutTime_MCPB" SG_ 242 MCPA_MtrIndex 0;
BA_ "GenSigTimeoutTime_SGCP" SG_ 242 MCPA_MtrIndex 0;
BA_ "GenSigTimeoutTime_TCM" SG_ 242 MCPA_MtrIndex 0;
BA_ "GenSigStartValue" SG_ 242 MCPA_MinTorq 4096;
BA_ "GenSigTimeoutTime_AGSM" SG_ 242 MCPA_MinTorq 0;
BA_ "GenSigTimeoutTime_ECM" SG_ 242 MCPA_MinTorq 0;
BA_ "GenSigTimeoutTime_MCPA" SG_ 242 MCPA_MinTorq 0;
BA_ "GenSigTimeoutTime_MCPB" SG_ 242 MCPA_MinTorq 0;
BA_ "GenSigTimeoutTime_SGCP" SG_ 242 MCPA_MinTorq 0;
BA_ "GenSigTimeoutTime_TCM" SG_ 242 MCPA_MinTorq 0;
BA_ "GenSigStartValue" SG_ 242 MCPA_MaxTorq 4096;
BA_ "GenSigTimeoutTime_AGSM" SG_ 242 MCPA_MaxTorq 0;
BA_ "GenSigTimeoutTime_ECM" SG_ 242 MCPA_MaxTorq 0;
BA_ "GenSigTimeoutTime_MCPA" SG_ 242 MCPA_MaxTorq 0;
BA_ "GenSigTimeoutTime_MCPB" SG_ 242 MCPA_MaxTorq 0;
BA_ "GenSigTimeoutTime_SGCP" SG_ 242 MCPA_MaxTorq 0;
BA_ "GenSigTimeoutTime_TCM" SG_ 242 MCPA_MaxTorq 0;
BA_ "GenSigTimeoutTime_AGSM" SG_ 242 MCPA_Invrtr_State 0;
BA_ "GenSigTimeoutTime_ECM" SG_ 242 MCPA_Invrtr_State 0;
BA_ "GenSigTimeoutTime_MCPA" SG_ 242 MCPA_Invrtr_State 0;
BA_ "GenSigTimeoutTime_MCPB" SG_ 242 MCPA_Invrtr_State 0;
BA_ "GenSigTimeoutTime_SGCP" SG_ 242 MCPA_Invrtr_State 0;
BA_ "GenSigTimeoutTime_TCM" SG_ 242 MCPA_Invrtr_State 0;
BA_ "GenSigTimeoutTime_AGSM" SG_ 242 MCPA_HV_CnctrOpn_Req 0;
BA_ "GenSigTimeoutTime_ECM" SG_ 242 MCPA_HV_CnctrOpn_Req 0;
BA_ "GenSigTimeoutTime_MCPA" SG_ 242 MCPA_HV_CnctrOpn_Req 0;
BA_ "GenSigTimeoutTime_MCPB" SG_ 242 MCPA_HV_CnctrOpn_Req 0;
BA_ "GenSigTimeoutTime_SGCP" SG_ 242 MCPA_HV_CnctrOpn_Req 0;
BA_ "GenSigTimeoutTime_TCM" SG_ 242 MCPA_HV_CnctrOpn_Req 0;
BA_ "GenSigTimeoutTime_AGSM" SG_ 242 MCPA_Dschrge_Status 0;
BA_ "GenSigTimeoutTime_ECM" SG_ 242 MCPA_Dschrge_Status 0;
BA_ "GenSigTimeoutTime_MCPA" SG_ 242 MCPA_Dschrge_Status 0;
BA_ "GenSigTimeoutTime_MCPB" SG_ 242 MCPA_Dschrge_Status 0;
BA_ "GenSigTimeoutTime_SGCP" SG_ 242 MCPA_Dschrge_Status 0;
BA_ "GenSigTimeoutTime_TCM" SG_ 242 MCPA_Dschrge_Status 0;
BA_ "GenSigTimeoutTime_AGSM" SG_ 242 MCPA_DeratingFactor 0;
BA_ "GenSigTimeoutTime_ECM" SG_ 242 MCPA_DeratingFactor 0;
BA_ "GenSigTimeoutTime_MCPA" SG_ 242 MCPA_DeratingFactor 0;
BA_ "GenSigTimeoutTime_MCPB" SG_ 242 MCPA_DeratingFactor 0;
BA_ "GenSigTimeoutTime_SGCP" SG_ 242 MCPA_DeratingFactor 0;
BA_ "GenSigTimeoutTime_TCM" SG_ 242 MCPA_DeratingFactor 0;
BA_ "GenSigTimeoutTime_AGSM" SG_ 242 MCPA_DC_Volt_V 0;
BA_ "GenSigTimeoutTime_ECM" SG_ 242 MCPA_DC_Volt_V 0;
BA_ "GenSigTimeoutTime_MCPA" SG_ 242 MCPA_DC_Volt_V 0;
BA_ "GenSigTimeoutTime_MCPB" SG_ 242 MCPA_DC_Volt_V 0;
BA_ "GenSigTimeoutTime_SGCP" SG_ 242 MCPA_DC_Volt_V 0;
BA_ "GenSigTimeoutTime_TCM" SG_ 242 MCPA_DC_Volt_V 0;
BA_ "GenSigTimeoutTime_AGSM" SG_ 242 MCPA_DC_Current_V 0;
BA_ "GenSigTimeoutTime_ECM" SG_ 242 MCPA_DC_Current_V 0;
BA_ "GenSigTimeoutTime_MCPA" SG_ 242 MCPA_DC_Current_V 0;
BA_ "GenSigTimeoutTime_MCPB" SG_ 242 MCPA_DC_Current_V 0;
BA_ "GenSigTimeoutTime_SGCP" SG_ 242 MCPA_DC_Current_V 0;
BA_ "GenSigTimeoutTime_TCM" SG_ 242 MCPA_DC_Current_V 0;
BA_ "GenSigStartValue" SG_ 242 MCPA_DC_Current 16384;
BA_ "GenSigTimeoutTime_AGSM" SG_ 242 MCPA_DC_Current 0;
BA_ "GenSigTimeoutTime_ECM" SG_ 242 MCPA_DC_Current 0;
BA_ "GenSigTimeoutTime_MCPA" SG_ 242 MCPA_DC_Current 0;
BA_ "GenSigTimeoutTime_MCPB" SG_ 242 MCPA_DC_Current 0;
BA_ "GenSigTimeoutTime_SGCP" SG_ 242 MCPA_DC_Current 0;
BA_ "GenSigTimeoutTime_TCM" SG_ 242 MCPA_DC_Current 0;
BA_ "GenSigTimeoutTime_AGSM" SG_ 242 MCPA_CpbltySpdDivVolt 0;
BA_ "GenSigTimeoutTime_ECM" SG_ 242 MCPA_CpbltySpdDivVolt 0;
BA_ "GenSigTimeoutTime_MCPA" SG_ 242 MCPA_CpbltySpdDivVolt 0;
BA_ "GenSigTimeoutTime_MCPB" SG_ 242 MCPA_CpbltySpdDivVolt 0;
BA_ "GenSigTimeoutTime_SGCP" SG_ 242 MCPA_CpbltySpdDivVolt 0;
BA_ "GenSigTimeoutTime_TCM" SG_ 242 MCPA_CpbltySpdDivVolt 0;
BA_ "GenSigTimeoutTime_AGSM" SG_ 242 MCPA_AccelRawV 0;
BA_ "GenSigTimeoutTime_ECM" SG_ 242 MCPA_AccelRawV 0;
BA_ "GenSigTimeoutTime_MCPA" SG_ 242 MCPA_AccelRawV 0;
BA_ "GenSigTimeoutTime_MCPB" SG_ 242 MCPA_AccelRawV 0;
BA_ "GenSigTimeoutTime_SGCP" SG_ 242 MCPA_AccelRawV 0;
BA_ "GenSigTimeoutTime_TCM" SG_ 242 MCPA_AccelRawV 0;
BA_ "GenSigTimeoutTime_AGSM" SG_ 242 MCPA_AccelRaw 0;
BA_ "GenSigTimeoutTime_ECM" SG_ 242 MCPA_AccelRaw 0;
BA_ "GenSigTimeoutTime_MCPA" SG_ 242 MCPA_AccelRaw 0;
BA_ "GenSigTimeoutTime_MCPB" SG_ 242 MCPA_AccelRaw 0;
BA_ "GenSigTimeoutTime_SGCP" SG_ 242 MCPA_AccelRaw 0;
BA_ "GenSigTimeoutTime_TCM" SG_ 242 MCPA_AccelRaw 0;
BA_ "GenSigTimeoutTime_AGSM" SG_ 242 MCPA_6SO_Status 0;
BA_ "GenSigTimeoutTime_ECM" SG_ 242 MCPA_6SO_Status 0;
BA_ "GenSigTimeoutTime_MCPA" SG_ 242 MCPA_6SO_Status 0;
BA_ "GenSigTimeoutTime_MCPB" SG_ 242 MCPA_6SO_Status 0;
BA_ "GenSigTimeoutTime_SGCP" SG_ 242 MCPA_6SO_Status 0;
BA_ "GenSigTimeoutTime_TCM" SG_ 242 MCPA_6SO_Status 0;
BA_ "GenSigTimeoutTime_AGSM" SG_ 242 MCPA_3PS_Pos 0;
BA_ "GenSigTimeoutTime_ECM" SG_ 242 MCPA_3PS_Pos 0;
BA_ "GenSigTimeoutTime_MCPA" SG_ 242 MCPA_3PS_Pos 0;
BA_ "GenSigTimeoutTime_MCPB" SG_ 242 MCPA_3PS_Pos 0;
BA_ "GenSigTimeoutTime_SGCP" SG_ 242 MCPA_3PS_Pos 0;
BA_ "GenSigTimeoutTime_TCM" SG_ 242 MCPA_3PS_Pos 0;
BA_ "GenSigTimeoutTime_AGSM" SG_ 242 InvF_CoolantTemp 0;
BA_ "GenSigTimeoutTime_ECM" SG_ 242 InvF_CoolantTemp 0;
BA_ "GenSigTimeoutTime_MCPA" SG_ 242 InvF_CoolantTemp 0;
BA_ "GenSigTimeoutTime_MCPB" SG_ 242 InvF_CoolantTemp 0;
BA_ "GenSigTimeoutTime_SGCP" SG_ 242 InvF_CoolantTemp 0;
BA_ "GenSigTimeoutTime_TCM" SG_ 242 InvF_CoolantTemp 0;
BA_ "GenSigTimeoutTime_AGSM" SG_ 242 MCPA_Torque_Achieved_V 0;
BA_ "GenSigTimeoutTime_ECM" SG_ 242 MCPA_Torque_Achieved_V 0;
BA_ "GenSigTimeoutTime_MCPA" SG_ 242 MCPA_Torque_Achieved_V 0;
BA_ "GenSigTimeoutTime_MCPB" SG_ 242 MCPA_Torque_Achieved_V 0;
BA_ "GenSigTimeoutTime_SGCP" SG_ 242 MCPA_Torque_Achieved_V 0;
BA_ "GenSigTimeoutTime_TCM" SG_ 242 MCPA_Torque_Achieved_V 0;
BA_ "GenSigTimeoutTime_AGSM" SG_ 242 MCPA_SPT_Stat 0;
BA_ "GenSigTimeoutTime_ECM" SG_ 242 MCPA_SPT_Stat 0;
BA_ "GenSigTimeoutTime_MCPA" SG_ 242 MCPA_SPT_Stat 0;
BA_ "GenSigTimeoutTime_MCPB" SG_ 242 MCPA_SPT_Stat 0;
BA_ "GenSigTimeoutTime_SGCP" SG_ 242 MCPA_SPT_Stat 0;
BA_ "GenSigTimeoutTime_TCM" SG_ 242 MCPA_SPT_Stat 0;
BA_ "GenSigTimeoutTime_MCPA" SG_ 2654486617 CBV_bit3_NMCoordinatorBit_1E3840 0;
BA_ "GenSigTimeoutTime_MCPB" SG_ 2654486617 CBV_bit3_NMCoordinatorBit_1E3840 0;
BA_ "GenSigTimeoutTime_SGCP" SG_ 2654486617 CBV_bit3_NMCoordinatorBit_1E3840 0;
BA_ "GenSigTimeoutTime_TCM" SG_ 2654486617 CBV_bit3_NMCoordinatorBit_1E3840 0;
BA_ "GenSigTimeoutTime_AGSM" SG_ 2654486617 CBV_bit3_NMCoordinatorBit_1E3840 0;
BA_ "GenSigTimeoutTime_ECM" SG_ 2654486617 CBV_bit3_NMCoordinatorBit_1E3840 0;
BA_ "GenSigTimeoutTime_EVCU2" SG_ 2654486617 CBV_bit3_NMCoordinatorBit_1E3840 0;
BA_ "SystemSignalLongSymbol" SG_ 2654486617 CBV_bit3_NMCoordinatorBit_1E3840 "CBV_bit3_NMCoordinatorBit_1E384059";
BA_ "GenSigTimeoutTime_AGSM" SG_ 2654486617 CBV_bit4_ActiveWakeupBit_1E38405 0;
BA_ "GenSigTimeoutTime_ECM" SG_ 2654486617 CBV_bit4_ActiveWakeupBit_1E38405 0;
BA_ "GenSigTimeoutTime_EVCU2" SG_ 2654486617 CBV_bit4_ActiveWakeupBit_1E38405 0;
BA_ "GenSigTimeoutTime_MCPA" SG_ 2654486617 CBV_bit4_ActiveWakeupBit_1E38405 0;
BA_ "GenSigTimeoutTime_MCPB" SG_ 2654486617 CBV_bit4_ActiveWakeupBit_1E38405 0;
BA_ "GenSigTimeoutTime_SGCP" SG_ 2654486617 CBV_bit4_ActiveWakeupBit_1E38405 0;
BA_ "GenSigTimeoutTime_TCM" SG_ 2654486617 CBV_bit4_ActiveWakeupBit_1E38405 0;
BA_ "SystemSignalLongSymbol" SG_ 2654486617 CBV_bit4_ActiveWakeupBit_1E38405 "CBV_bit4_ActiveWakeupBit_1E384059";
BA_ "GenSigTimeoutTime_AGSM" SG_ 2654486617 CBV_bit5_1E384059 0;
BA_ "GenSigTimeoutTime_ECM" SG_ 2654486617 CBV_bit5_1E384059 0;
BA_ "GenSigTimeoutTime_EVCU2" SG_ 2654486617 CBV_bit5_1E384059 0;
BA_ "GenSigTimeoutTime_MCPA" SG_ 2654486617 CBV_bit5_1E384059 0;
BA_ "GenSigTimeoutTime_MCPB" SG_ 2654486617 CBV_bit5_1E384059 0;
BA_ "GenSigTimeoutTime_SGCP" SG_ 2654486617 CBV_bit5_1E384059 0;
BA_ "GenSigTimeoutTime_TCM" SG_ 2654486617 CBV_bit5_1E384059 0;
BA_ "GenSigTimeoutTime_AGSM" SG_ 2654486617 CBV_bit6_PartialNtwInfBit_1E3840 0;
BA_ "GenSigTimeoutTime_ECM" SG_ 2654486617 CBV_bit6_PartialNtwInfBit_1E3840 0;
BA_ "GenSigTimeoutTime_EVCU2" SG_ 2654486617 CBV_bit6_PartialNtwInfBit_1E3840 0;
BA_ "GenSigTimeoutTime_MCPA" SG_ 2654486617 CBV_bit6_PartialNtwInfBit_1E3840 0;
BA_ "GenSigTimeoutTime_MCPB" SG_ 2654486617 CBV_bit6_PartialNtwInfBit_1E3840 0;
BA_ "GenSigTimeoutTime_SGCP" SG_ 2654486617 CBV_bit6_PartialNtwInfBit_1E3840 0;
BA_ "GenSigTimeoutTime_TCM" SG_ 2654486617 CBV_bit6_PartialNtwInfBit_1E3840 0;
BA_ "SystemSignalLongSymbol" SG_ 2654486617 CBV_bit6_PartialNtwInfBit_1E3840 "CBV_bit6_PartialNtwInfBit_1E384059";
BA_ "GenSigTimeoutTime_AGSM" SG_ 2654486617 CBV_bit7_1E384059 0;
BA_ "GenSigTimeoutTime_ECM" SG_ 2654486617 CBV_bit7_1E384059 0;
BA_ "GenSigTimeoutTime_EVCU2" SG_ 2654486617 CBV_bit7_1E384059 0;
BA_ "GenSigTimeoutTime_MCPA" SG_ 2654486617 CBV_bit7_1E384059 0;
BA_ "GenSigTimeoutTime_MCPB" SG_ 2654486617 CBV_bit7_1E384059 0;
BA_ "GenSigTimeoutTime_SGCP" SG_ 2654486617 CBV_bit7_1E384059 0;
BA_ "GenSigTimeoutTime_TCM" SG_ 2654486617 CBV_bit7_1E384059 0;
BA_ "GenSigTimeoutTime_AGSM" SG_ 2654486617 SourceNodeIdentifier_1E384059 0;
BA_ "GenSigTimeoutTime_ECM" SG_ 2654486617 SourceNodeIdentifier_1E384059 0;
BA_ "GenSigTimeoutTime_EVCU2" SG_ 2654486617 SourceNodeIdentifier_1E384059 0;
BA_ "GenSigTimeoutTime_MCPA" SG_ 2654486617 SourceNodeIdentifier_1E384059 0;
BA_ "GenSigTimeoutTime_MCPB" SG_ 2654486617 SourceNodeIdentifier_1E384059 0;
BA_ "GenSigTimeoutTime_SGCP" SG_ 2654486617 SourceNodeIdentifier_1E384059 0;
BA_ "GenSigTimeoutTime_TCM" SG_ 2654486617 SourceNodeIdentifier_1E384059 0;
BA_ "GenSigTimeoutTime_AGSM" SG_ 2654486617 CBV_bit0_RepeatMessageRequestBit 0;
BA_ "GenSigTimeoutTime_ECM" SG_ 2654486617 CBV_bit0_RepeatMessageRequestBit 0;
BA_ "GenSigTimeoutTime_EVCU2" SG_ 2654486617 CBV_bit0_RepeatMessageRequestBit 0;
BA_ "GenSigTimeoutTime_MCPA" SG_ 2654486617 CBV_bit0_RepeatMessageRequestBit 0;
BA_ "GenSigTimeoutTime_MCPB" SG_ 2654486617 CBV_bit0_RepeatMessageRequestBit 0;
BA_ "GenSigTimeoutTime_SGCP" SG_ 2654486617 CBV_bit0_RepeatMessageRequestBit 0;
BA_ "GenSigTimeoutTime_TCM" SG_ 2654486617 CBV_bit0_RepeatMessageRequestBit 0;
BA_ "SystemSignalLongSymbol" SG_ 2654486617 CBV_bit0_RepeatMessageRequestBit "CBV_bit0_RepeatMessageRequestBit_1E384059";
BA_ "GenSigTimeoutTime_AGSM" SG_ 2654486617 CBV_bit1_1E384059 0;
BA_ "GenSigTimeoutTime_ECM" SG_ 2654486617 CBV_bit1_1E384059 0;
BA_ "GenSigTimeoutTime_EVCU2" SG_ 2654486617 CBV_bit1_1E384059 0;
BA_ "GenSigTimeoutTime_MCPA" SG_ 2654486617 CBV_bit1_1E384059 0;
BA_ "GenSigTimeoutTime_MCPB" SG_ 2654486617 CBV_bit1_1E384059 0;
BA_ "GenSigTimeoutTime_SGCP" SG_ 2654486617 CBV_bit1_1E384059 0;
BA_ "GenSigTimeoutTime_TCM" SG_ 2654486617 CBV_bit1_1E384059 0;
BA_ "GenSigTimeoutTime_AGSM" SG_ 2654486617 CBV_bit2_1E384059 0;
BA_ "GenSigTimeoutTime_ECM" SG_ 2654486617 CBV_bit2_1E384059 0;
BA_ "GenSigTimeoutTime_EVCU2" SG_ 2654486617 CBV_bit2_1E384059 0;
BA_ "GenSigTimeoutTime_MCPA" SG_ 2654486617 CBV_bit2_1E384059 0;
BA_ "GenSigTimeoutTime_MCPB" SG_ 2654486617 CBV_bit2_1E384059 0;
BA_ "GenSigTimeoutTime_SGCP" SG_ 2654486617 CBV_bit2_1E384059 0;
BA_ "GenSigTimeoutTime_TCM" SG_ 2654486617 CBV_bit2_1E384059 0;
BA_ "GenSigTimeoutTime_AGSM" SG_ 2654486616 CBV_bit0_RepeatMessageReque_0000 0;
BA_ "GenSigTimeoutTime_ECM" SG_ 2654486616 CBV_bit0_RepeatMessageReque_0000 0;
BA_ "GenSigTimeoutTime_EVCU2" SG_ 2654486616 CBV_bit0_RepeatMessageReque_0000 0;
BA_ "GenSigTimeoutTime_MCPA" SG_ 2654486616 CBV_bit0_RepeatMessageReque_0000 0;
BA_ "GenSigTimeoutTime_MCPB" SG_ 2654486616 CBV_bit0_RepeatMessageReque_0000 0;
BA_ "GenSigTimeoutTime_SGCP" SG_ 2654486616 CBV_bit0_RepeatMessageReque_0000 0;
BA_ "GenSigTimeoutTime_TCM" SG_ 2654486616 CBV_bit0_RepeatMessageReque_0000 0;
BA_ "SystemSignalLongSymbol" SG_ 2654486616 CBV_bit0_RepeatMessageReque_0000 "CBV_bit0_RepeatMessageRequestBit_1E384058";
BA_ "GenSigTimeoutTime_AGSM" SG_ 2654486616 CBV_bit1_1E384058 0;
BA_ "GenSigTimeoutTime_ECM" SG_ 2654486616 CBV_bit1_1E384058 0;
BA_ "GenSigTimeoutTime_EVCU2" SG_ 2654486616 CBV_bit1_1E384058 0;
BA_ "GenSigTimeoutTime_MCPA" SG_ 2654486616 CBV_bit1_1E384058 0;
BA_ "GenSigTimeoutTime_MCPB" SG_ 2654486616 CBV_bit1_1E384058 0;
BA_ "GenSigTimeoutTime_SGCP" SG_ 2654486616 CBV_bit1_1E384058 0;
BA_ "GenSigTimeoutTime_TCM" SG_ 2654486616 CBV_bit1_1E384058 0;
BA_ "GenSigTimeoutTime_AGSM" SG_ 2654486616 CBV_bit2_1E384058 0;
BA_ "GenSigTimeoutTime_ECM" SG_ 2654486616 CBV_bit2_1E384058 0;
BA_ "GenSigTimeoutTime_EVCU2" SG_ 2654486616 CBV_bit2_1E384058 0;
BA_ "GenSigTimeoutTime_MCPA" SG_ 2654486616 CBV_bit2_1E384058 0;
BA_ "GenSigTimeoutTime_MCPB" SG_ 2654486616 CBV_bit2_1E384058 0;
BA_ "GenSigTimeoutTime_SGCP" SG_ 2654486616 CBV_bit2_1E384058 0;
BA_ "GenSigTimeoutTime_TCM" SG_ 2654486616 CBV_bit2_1E384058 0;
BA_ "GenSigTimeoutTime_AGSM" SG_ 2654486616 CBV_bit3_NMCoordinatorBit_1_0000 0;
BA_ "GenSigTimeoutTime_ECM" SG_ 2654486616 CBV_bit3_NMCoordinatorBit_1_0000 0;
BA_ "GenSigTimeoutTime_EVCU2" SG_ 2654486616 CBV_bit3_NMCoordinatorBit_1_0000 0;
BA_ "GenSigTimeoutTime_MCPA" SG_ 2654486616 CBV_bit3_NMCoordinatorBit_1_0000 0;
BA_ "GenSigTimeoutTime_MCPB" SG_ 2654486616 CBV_bit3_NMCoordinatorBit_1_0000 0;
BA_ "GenSigTimeoutTime_SGCP" SG_ 2654486616 CBV_bit3_NMCoordinatorBit_1_0000 0;
BA_ "GenSigTimeoutTime_TCM" SG_ 2654486616 CBV_bit3_NMCoordinatorBit_1_0000 0;
BA_ "SystemSignalLongSymbol" SG_ 2654486616 CBV_bit3_NMCoordinatorBit_1_0000 "CBV_bit3_NMCoordinatorBit_1E384058";
BA_ "GenSigTimeoutTime_AGSM" SG_ 2654486616 CBV_bit4_ActiveWakeupBit_1E_0000 0;
BA_ "GenSigTimeoutTime_ECM" SG_ 2654486616 CBV_bit4_ActiveWakeupBit_1E_0000 0;
BA_ "GenSigTimeoutTime_EVCU2" SG_ 2654486616 CBV_bit4_ActiveWakeupBit_1E_0000 0;
BA_ "GenSigTimeoutTime_MCPA" SG_ 2654486616 CBV_bit4_ActiveWakeupBit_1E_0000 0;
BA_ "GenSigTimeoutTime_MCPB" SG_ 2654486616 CBV_bit4_ActiveWakeupBit_1E_0000 0;
BA_ "GenSigTimeoutTime_SGCP" SG_ 2654486616 CBV_bit4_ActiveWakeupBit_1E_0000 0;
BA_ "GenSigTimeoutTime_TCM" SG_ 2654486616 CBV_bit4_ActiveWakeupBit_1E_0000 0;
BA_ "SystemSignalLongSymbol" SG_ 2654486616 CBV_bit4_ActiveWakeupBit_1E_0000 "CBV_bit4_ActiveWakeupBit_1E384058";
BA_ "GenSigTimeoutTime_AGSM" SG_ 2654486616 CBV_bit5_1E384058 0;
BA_ "GenSigTimeoutTime_ECM" SG_ 2654486616 CBV_bit5_1E384058 0;
BA_ "GenSigTimeoutTime_EVCU2" SG_ 2654486616 CBV_bit5_1E384058 0;
BA_ "GenSigTimeoutTime_MCPA" SG_ 2654486616 CBV_bit5_1E384058 0;
BA_ "GenSigTimeoutTime_MCPB" SG_ 2654486616 CBV_bit5_1E384058 0;
BA_ "GenSigTimeoutTime_SGCP" SG_ 2654486616 CBV_bit5_1E384058 0;
BA_ "GenSigTimeoutTime_TCM" SG_ 2654486616 CBV_bit5_1E384058 0;
BA_ "GenSigTimeoutTime_AGSM" SG_ 2654486616 CBV_bit6_PartialNtwInfBit_1_0000 0;
BA_ "GenSigTimeoutTime_ECM" SG_ 2654486616 CBV_bit6_PartialNtwInfBit_1_0000 0;
BA_ "GenSigTimeoutTime_EVCU2" SG_ 2654486616 CBV_bit6_PartialNtwInfBit_1_0000 0;
BA_ "GenSigTimeoutTime_MCPA" SG_ 2654486616 CBV_bit6_PartialNtwInfBit_1_0000 0;
BA_ "GenSigTimeoutTime_MCPB" SG_ 2654486616 CBV_bit6_PartialNtwInfBit_1_0000 0;
BA_ "GenSigTimeoutTime_SGCP" SG_ 2654486616 CBV_bit6_PartialNtwInfBit_1_0000 0;
BA_ "GenSigTimeoutTime_TCM" SG_ 2654486616 CBV_bit6_PartialNtwInfBit_1_0000 0;
BA_ "SystemSignalLongSymbol" SG_ 2654486616 CBV_bit6_PartialNtwInfBit_1_0000 "CBV_bit6_PartialNtwInfBit_1E384058";
BA_ "GenSigTimeoutTime_AGSM" SG_ 2654486616 CBV_bit7_1E384058 0;
BA_ "GenSigTimeoutTime_ECM" SG_ 2654486616 CBV_bit7_1E384058 0;
BA_ "GenSigTimeoutTime_EVCU2" SG_ 2654486616 CBV_bit7_1E384058 0;
BA_ "GenSigTimeoutTime_MCPA" SG_ 2654486616 CBV_bit7_1E384058 0;
BA_ "GenSigTimeoutTime_MCPB" SG_ 2654486616 CBV_bit7_1E384058 0;
BA_ "GenSigTimeoutTime_SGCP" SG_ 2654486616 CBV_bit7_1E384058 0;
BA_ "GenSigTimeoutTime_TCM" SG_ 2654486616 CBV_bit7_1E384058 0;
BA_ "GenSigTimeoutTime_AGSM" SG_ 2654486616 SourceNodeIdentifier_1E384058 0;
BA_ "GenSigTimeoutTime_ECM" SG_ 2654486616 SourceNodeIdentifier_1E384058 0;
BA_ "GenSigTimeoutTime_EVCU2" SG_ 2654486616 SourceNodeIdentifier_1E384058 0;
BA_ "GenSigTimeoutTime_MCPA" SG_ 2654486616 SourceNodeIdentifier_1E384058 0;
BA_ "GenSigTimeoutTime_MCPB" SG_ 2654486616 SourceNodeIdentifier_1E384058 0;
BA_ "GenSigTimeoutTime_SGCP" SG_ 2654486616 SourceNodeIdentifier_1E384058 0;
BA_ "GenSigTimeoutTime_TCM" SG_ 2654486616 SourceNodeIdentifier_1E384058 0;
BA_ "GenSigTimeoutTime_AGSM" SG_ 2564682261 N_PDU_18DDF215 0;
BA_ "GenSigTimeoutTime_ECM" SG_ 2564682261 N_PDU_18DDF215 0;
BA_ "GenSigTimeoutTime_EVCU2" SG_ 2564682261 N_PDU_18DDF215 0;
BA_ "GenSigTimeoutTime_MCPA" SG_ 2564682261 N_PDU_18DDF215 0;
BA_ "GenSigTimeoutTime_MCPB" SG_ 2564682261 N_PDU_18DDF215 0;
BA_ "GenSigTimeoutTime_SGCP" SG_ 2564682261 N_PDU_18DDF215 0;
BA_ "GenSigTimeoutTime_AGSM" SG_ 2564682260 N_PDU_18DDF214 0;
BA_ "GenSigTimeoutTime_ECM" SG_ 2564682260 N_PDU_18DDF214 0;
BA_ "GenSigTimeoutTime_EVCU2" SG_ 2564682260 N_PDU_18DDF214 0;
BA_ "GenSigTimeoutTime_MCPA" SG_ 2564682260 N_PDU_18DDF214 0;
BA_ "GenSigTimeoutTime_MCPB" SG_ 2564682260 N_PDU_18DDF214 0;
BA_ "GenSigTimeoutTime_SGCP" SG_ 2564682260 N_PDU_18DDF214 0;
BA_ "GenSigTimeoutTime_AGSM" SG_ 2564485396 N_PDU_18DAF114 0;
BA_ "GenSigTimeoutTime_EVCU2" SG_ 2564485396 N_PDU_18DAF114 0;
BA_ "GenSigTimeoutTime_MCPA" SG_ 2564485396 N_PDU_18DAF114 0;
BA_ "GenSigTimeoutTime_MCPB" SG_ 2564485396 N_PDU_18DAF114 0;
BA_ "GenSigTimeoutTime_AGSM" SG_ 2564485653 N_PDU_18DAF215 0;
BA_ "GenSigTimeoutTime_ECM" SG_ 2564485653 N_PDU_18DAF215 0;
BA_ "GenSigTimeoutTime_EVCU2" SG_ 2564485653 N_PDU_18DAF215 0;
BA_ "GenSigTimeoutTime_MCPA" SG_ 2564485653 N_PDU_18DAF215 0;
BA_ "GenSigTimeoutTime_MCPB" SG_ 2564485653 N_PDU_18DAF215 0;
BA_ "GenSigTimeoutTime_SGCP" SG_ 2564485653 N_PDU_18DAF215 0;
BA_ "GenSigTimeoutTime_AGSM" SG_ 2564485652 N_PDU_18DAF214 0;
BA_ "GenSigTimeoutTime_ECM" SG_ 2564485652 N_PDU_18DAF214 0;
BA_ "GenSigTimeoutTime_EVCU2" SG_ 2564485652 N_PDU_18DAF214 0;
BA_ "GenSigTimeoutTime_MCPA" SG_ 2564485652 N_PDU_18DAF214 0;
BA_ "GenSigTimeoutTime_MCPB" SG_ 2564485652 N_PDU_18DAF214 0;
BA_ "GenSigTimeoutTime_SGCP" SG_ 2564485652 N_PDU_18DAF214 0;
BA_ "GenSigTimeoutTime_AGSM" SG_ 2564429297 N_PDU_18DA15F1 0;
BA_ "GenSigTimeoutTime_EVCU2" SG_ 2564429297 N_PDU_18DA15F1 0;
BA_ "GenSigTimeoutTime_MCPA" SG_ 2564429297 N_PDU_18DA15F1 0;
BA_ "GenSigTimeoutTime_MCPB" SG_ 2564429297 N_PDU_18DA15F1 0;
BA_ "GenSigTimeoutTime_EVCU2" SG_ 2564429298 N_PDU_18DA15F2 0;
BA_ "GenSigTimeoutTime_MCPA" SG_ 2564429298 N_PDU_18DA15F2 0;
BA_ "GenSigTimeoutTime_MCPB" SG_ 2564429298 N_PDU_18DA15F2 0;
BA_ "GenSigTimeoutTime_SGCP" SG_ 2564429298 N_PDU_18DA15F2 0;
BA_ "GenSigTimeoutTime_AGSM" SG_ 2564429298 N_PDU_18DA15F2 0;
BA_ "GenSigTimeoutTime_ECM" SG_ 2564429298 N_PDU_18DA15F2 0;
BA_ "GenSigTimeoutTime_AGSM" SG_ 2564429042 N_PDU_18DA14F2 0;
BA_ "GenSigTimeoutTime_ECM" SG_ 2564429042 N_PDU_18DA14F2 0;
BA_ "GenSigTimeoutTime_EVCU2" SG_ 2564429042 N_PDU_18DA14F2 0;
BA_ "GenSigTimeoutTime_MCPA" SG_ 2564429042 N_PDU_18DA14F2 0;
BA_ "GenSigTimeoutTime_MCPB" SG_ 2564429042 N_PDU_18DA14F2 0;
BA_ "GenSigTimeoutTime_SGCP" SG_ 2564429042 N_PDU_18DA14F2 0;
BA_ "GenSigTimeoutTime_AGSM" SG_ 2651930713 Digit_11_MCPB 0;
BA_ "GenSigTimeoutTime_ECM" SG_ 2651930713 Digit_11_MCPB 0;
BA_ "GenSigTimeoutTime_MCPA" SG_ 2651930713 Digit_11_MCPB 0;
BA_ "GenSigTimeoutTime_MCPB" SG_ 2651930713 Digit_11_MCPB 0;
BA_ "GenSigTimeoutTime_SGCP" SG_ 2651930713 Digit_11_MCPB 0;
BA_ "GenSigTimeoutTime_TCM" SG_ 2651930713 Digit_11_MCPB 0;
BA_ "GenSigTimeoutTime_AGSM" SG_ 2651930713 Digit_10_MCPB 0;
BA_ "GenSigTimeoutTime_ECM" SG_ 2651930713 Digit_10_MCPB 0;
BA_ "GenSigTimeoutTime_MCPA" SG_ 2651930713 Digit_10_MCPB 0;
BA_ "GenSigTimeoutTime_MCPB" SG_ 2651930713 Digit_10_MCPB 0;
BA_ "GenSigTimeoutTime_SGCP" SG_ 2651930713 Digit_10_MCPB 0;
BA_ "GenSigTimeoutTime_TCM" SG_ 2651930713 Digit_10_MCPB 0;
BA_ "GenSigTimeoutTime_AGSM" SG_ 2651930713 Digit_09_MCPB 0;
BA_ "GenSigTimeoutTime_ECM" SG_ 2651930713 Digit_09_MCPB 0;
BA_ "GenSigTimeoutTime_MCPA" SG_ 2651930713 Digit_09_MCPB 0;
BA_ "GenSigTimeoutTime_MCPB" SG_ 2651930713 Digit_09_MCPB 0;
BA_ "GenSigTimeoutTime_SGCP" SG_ 2651930713 Digit_09_MCPB 0;
BA_ "GenSigTimeoutTime_TCM" SG_ 2651930713 Digit_09_MCPB 0;
BA_ "GenSigTimeoutTime_AGSM" SG_ 2651930713 Digit_08_MCPB 0;
BA_ "GenSigTimeoutTime_ECM" SG_ 2651930713 Digit_08_MCPB 0;
BA_ "GenSigTimeoutTime_MCPA" SG_ 2651930713 Digit_08_MCPB 0;
BA_ "GenSigTimeoutTime_MCPB" SG_ 2651930713 Digit_08_MCPB 0;
BA_ "GenSigTimeoutTime_SGCP" SG_ 2651930713 Digit_08_MCPB 0;
BA_ "GenSigTimeoutTime_TCM" SG_ 2651930713 Digit_08_MCPB 0;
BA_ "GenSigTimeoutTime_AGSM" SG_ 2651930713 Digit_07_MCPB 0;
BA_ "GenSigTimeoutTime_ECM" SG_ 2651930713 Digit_07_MCPB 0;
BA_ "GenSigTimeoutTime_MCPA" SG_ 2651930713 Digit_07_MCPB 0;
BA_ "GenSigTimeoutTime_MCPB" SG_ 2651930713 Digit_07_MCPB 0;
BA_ "GenSigTimeoutTime_SGCP" SG_ 2651930713 Digit_07_MCPB 0;
BA_ "GenSigTimeoutTime_TCM" SG_ 2651930713 Digit_07_MCPB 0;
BA_ "GenSigTimeoutTime_AGSM" SG_ 2651930713 Digit_06_MCPB 0;
BA_ "GenSigTimeoutTime_ECM" SG_ 2651930713 Digit_06_MCPB 0;
BA_ "GenSigTimeoutTime_MCPA" SG_ 2651930713 Digit_06_MCPB 0;
BA_ "GenSigTimeoutTime_MCPB" SG_ 2651930713 Digit_06_MCPB 0;
BA_ "GenSigTimeoutTime_SGCP" SG_ 2651930713 Digit_06_MCPB 0;
BA_ "GenSigTimeoutTime_TCM" SG_ 2651930713 Digit_06_MCPB 0;
BA_ "GenSigTimeoutTime_AGSM" SG_ 2651930713 Digit_05_MCPB 0;
BA_ "GenSigTimeoutTime_ECM" SG_ 2651930713 Digit_05_MCPB 0;
BA_ "GenSigTimeoutTime_MCPA" SG_ 2651930713 Digit_05_MCPB 0;
BA_ "GenSigTimeoutTime_MCPB" SG_ 2651930713 Digit_05_MCPB 0;
BA_ "GenSigTimeoutTime_SGCP" SG_ 2651930713 Digit_05_MCPB 0;
BA_ "GenSigTimeoutTime_TCM" SG_ 2651930713 Digit_05_MCPB 0;
BA_ "GenSigTimeoutTime_AGSM" SG_ 2651930713 Digit_04_MCPB 0;
BA_ "GenSigTimeoutTime_ECM" SG_ 2651930713 Digit_04_MCPB 0;
BA_ "GenSigTimeoutTime_MCPA" SG_ 2651930713 Digit_04_MCPB 0;
BA_ "GenSigTimeoutTime_MCPB" SG_ 2651930713 Digit_04_MCPB 0;
BA_ "GenSigTimeoutTime_SGCP" SG_ 2651930713 Digit_04_MCPB 0;
BA_ "GenSigTimeoutTime_TCM" SG_ 2651930713 Digit_04_MCPB 0;
BA_ "GenSigTimeoutTime_AGSM" SG_ 2651930713 Digit_03_MCPB 0;
BA_ "GenSigTimeoutTime_ECM" SG_ 2651930713 Digit_03_MCPB 0;
BA_ "GenSigTimeoutTime_MCPA" SG_ 2651930713 Digit_03_MCPB 0;
BA_ "GenSigTimeoutTime_MCPB" SG_ 2651930713 Digit_03_MCPB 0;
BA_ "GenSigTimeoutTime_SGCP" SG_ 2651930713 Digit_03_MCPB 0;
BA_ "GenSigTimeoutTime_TCM" SG_ 2651930713 Digit_03_MCPB 0;
BA_ "GenSigTimeoutTime_AGSM" SG_ 2651930713 Digit_02_MCPB 0;
BA_ "GenSigTimeoutTime_ECM" SG_ 2651930713 Digit_02_MCPB 0;
BA_ "GenSigTimeoutTime_MCPA" SG_ 2651930713 Digit_02_MCPB 0;
BA_ "GenSigTimeoutTime_MCPB" SG_ 2651930713 Digit_02_MCPB 0;
BA_ "GenSigTimeoutTime_SGCP" SG_ 2651930713 Digit_02_MCPB 0;
BA_ "GenSigTimeoutTime_TCM" SG_ 2651930713 Digit_02_MCPB 0;
BA_ "GenSigSendType" SG_ 2651930713 Digit_01_MCPB 1;
BA_ "GenSigTimeoutTime_AGSM" SG_ 2651930713 Digit_01_MCPB 0;
BA_ "GenSigTimeoutTime_ECM" SG_ 2651930713 Digit_01_MCPB 0;
BA_ "GenSigTimeoutTime_MCPA" SG_ 2651930713 Digit_01_MCPB 0;
BA_ "GenSigTimeoutTime_MCPB" SG_ 2651930713 Digit_01_MCPB 0;
BA_ "GenSigTimeoutTime_SGCP" SG_ 2651930713 Digit_01_MCPB 0;
BA_ "GenSigTimeoutTime_TCM" SG_ 2651930713 Digit_01_MCPB 0;
BA_ "GenSigTimeoutTime_AGSM" SG_ 2651930712 Digit_11_MCPA 0;
BA_ "GenSigTimeoutTime_ECM" SG_ 2651930712 Digit_11_MCPA 0;
BA_ "GenSigTimeoutTime_MCPA" SG_ 2651930712 Digit_11_MCPA 0;
BA_ "GenSigTimeoutTime_MCPB" SG_ 2651930712 Digit_11_MCPA 0;
BA_ "GenSigTimeoutTime_SGCP" SG_ 2651930712 Digit_11_MCPA 0;
BA_ "GenSigTimeoutTime_TCM" SG_ 2651930712 Digit_11_MCPA 0;
BA_ "GenSigTimeoutTime_AGSM" SG_ 2651930712 Digit_10_MCPA 0;
BA_ "GenSigTimeoutTime_ECM" SG_ 2651930712 Digit_10_MCPA 0;
BA_ "GenSigTimeoutTime_MCPA" SG_ 2651930712 Digit_10_MCPA 0;
BA_ "GenSigTimeoutTime_MCPB" SG_ 2651930712 Digit_10_MCPA 0;
BA_ "GenSigTimeoutTime_SGCP" SG_ 2651930712 Digit_10_MCPA 0;
BA_ "GenSigTimeoutTime_TCM" SG_ 2651930712 Digit_10_MCPA 0;
BA_ "GenSigTimeoutTime_AGSM" SG_ 2651930712 Digit_09_MCPA 0;
BA_ "GenSigTimeoutTime_ECM" SG_ 2651930712 Digit_09_MCPA 0;
BA_ "GenSigTimeoutTime_MCPA" SG_ 2651930712 Digit_09_MCPA 0;
BA_ "GenSigTimeoutTime_MCPB" SG_ 2651930712 Digit_09_MCPA 0;
BA_ "GenSigTimeoutTime_SGCP" SG_ 2651930712 Digit_09_MCPA 0;
BA_ "GenSigTimeoutTime_TCM" SG_ 2651930712 Digit_09_MCPA 0;
BA_ "GenSigTimeoutTime_AGSM" SG_ 2651930712 Digit_08_MCPA 0;
BA_ "GenSigTimeoutTime_ECM" SG_ 2651930712 Digit_08_MCPA 0;
BA_ "GenSigTimeoutTime_MCPA" SG_ 2651930712 Digit_08_MCPA 0;
BA_ "GenSigTimeoutTime_MCPB" SG_ 2651930712 Digit_08_MCPA 0;
BA_ "GenSigTimeoutTime_SGCP" SG_ 2651930712 Digit_08_MCPA 0;
BA_ "GenSigTimeoutTime_TCM" SG_ 2651930712 Digit_08_MCPA 0;
BA_ "GenSigTimeoutTime_AGSM" SG_ 2651930712 Digit_07_MCPA 0;
BA_ "GenSigTimeoutTime_ECM" SG_ 2651930712 Digit_07_MCPA 0;
BA_ "GenSigTimeoutTime_MCPA" SG_ 2651930712 Digit_07_MCPA 0;
BA_ "GenSigTimeoutTime_MCPB" SG_ 2651930712 Digit_07_MCPA 0;
BA_ "GenSigTimeoutTime_SGCP" SG_ 2651930712 Digit_07_MCPA 0;
BA_ "GenSigTimeoutTime_TCM" SG_ 2651930712 Digit_07_MCPA 0;
BA_ "GenSigTimeoutTime_AGSM" SG_ 2651930712 Digit_06_MCPA 0;
BA_ "GenSigTimeoutTime_ECM" SG_ 2651930712 Digit_06_MCPA 0;
BA_ "GenSigTimeoutTime_MCPA" SG_ 2651930712 Digit_06_MCPA 0;
BA_ "GenSigTimeoutTime_MCPB" SG_ 2651930712 Digit_06_MCPA 0;
BA_ "GenSigTimeoutTime_SGCP" SG_ 2651930712 Digit_06_MCPA 0;
BA_ "GenSigTimeoutTime_TCM" SG_ 2651930712 Digit_06_MCPA 0;
BA_ "GenSigTimeoutTime_AGSM" SG_ 2651930712 Digit_05_MCPA 0;
BA_ "GenSigTimeoutTime_ECM" SG_ 2651930712 Digit_05_MCPA 0;
BA_ "GenSigTimeoutTime_MCPA" SG_ 2651930712 Digit_05_MCPA 0;
BA_ "GenSigTimeoutTime_MCPB" SG_ 2651930712 Digit_05_MCPA 0;
BA_ "GenSigTimeoutTime_SGCP" SG_ 2651930712 Digit_05_MCPA 0;
BA_ "GenSigTimeoutTime_TCM" SG_ 2651930712 Digit_05_MCPA 0;
BA_ "GenSigTimeoutTime_AGSM" SG_ 2651930712 Digit_04_MCPA 0;
BA_ "GenSigTimeoutTime_ECM" SG_ 2651930712 Digit_04_MCPA 0;
BA_ "GenSigTimeoutTime_MCPA" SG_ 2651930712 Digit_04_MCPA 0;
BA_ "GenSigTimeoutTime_MCPB" SG_ 2651930712 Digit_04_MCPA 0;
BA_ "GenSigTimeoutTime_SGCP" SG_ 2651930712 Digit_04_MCPA 0;
BA_ "GenSigTimeoutTime_TCM" SG_ 2651930712 Digit_04_MCPA 0;
BA_ "GenSigTimeoutTime_AGSM" SG_ 2651930712 Digit_03_MCPA 0;
BA_ "GenSigTimeoutTime_ECM" SG_ 2651930712 Digit_03_MCPA 0;
BA_ "GenSigTimeoutTime_MCPA" SG_ 2651930712 Digit_03_MCPA 0;
BA_ "GenSigTimeoutTime_MCPB" SG_ 2651930712 Digit_03_MCPA 0;
BA_ "GenSigTimeoutTime_SGCP" SG_ 2651930712 Digit_03_MCPA 0;
BA_ "GenSigTimeoutTime_TCM" SG_ 2651930712 Digit_03_MCPA 0;
BA_ "GenSigTimeoutTime_AGSM" SG_ 2651930712 Digit_02_MCPA 0;
BA_ "GenSigTimeoutTime_ECM" SG_ 2651930712 Digit_02_MCPA 0;
BA_ "GenSigTimeoutTime_MCPA" SG_ 2651930712 Digit_02_MCPA 0;
BA_ "GenSigTimeoutTime_MCPB" SG_ 2651930712 Digit_02_MCPA 0;
BA_ "GenSigTimeoutTime_SGCP" SG_ 2651930712 Digit_02_MCPA 0;
BA_ "GenSigTimeoutTime_TCM" SG_ 2651930712 Digit_02_MCPA 0;
BA_ "GenSigSendType" SG_ 2651930712 Digit_01_MCPA 1;
BA_ "GenSigTimeoutTime_AGSM" SG_ 2651930712 Digit_01_MCPA 0;
BA_ "GenSigTimeoutTime_ECM" SG_ 2651930712 Digit_01_MCPA 0;
BA_ "GenSigTimeoutTime_MCPA" SG_ 2651930712 Digit_01_MCPA 0;
BA_ "GenSigTimeoutTime_MCPB" SG_ 2651930712 Digit_01_MCPA 0;
BA_ "GenSigTimeoutTime_SGCP" SG_ 2651930712 Digit_01_MCPA 0;
BA_ "GenSigTimeoutTime_TCM" SG_ 2651930712 Digit_01_MCPA 0;
BA_ "GenSigTimeoutTime_AGSM" SG_ 496 MessageCounter_PARK_DATA 0;
BA_ "GenSigTimeoutTime_ECM" SG_ 496 MessageCounter_PARK_DATA 0;
BA_ "GenSigTimeoutTime_MCPA" SG_ 496 MessageCounter_PARK_DATA 0;
BA_ "GenSigTimeoutTime_MCPB" SG_ 496 MessageCounter_PARK_DATA 0;
BA_ "GenSigTimeoutTime_SGCP" SG_ 496 MessageCounter_PARK_DATA 0;
BA_ "GenSigTimeoutTime_TCM" SG_ 496 MessageCounter_PARK_DATA 0;
BA_ "GenSigTimeoutTime_AGSM" SG_ 496 CRC_PARK_DATA 0;
BA_ "GenSigTimeoutTime_ECM" SG_ 496 CRC_PARK_DATA 0;
BA_ "GenSigTimeoutTime_MCPA" SG_ 496 CRC_PARK_DATA 0;
BA_ "GenSigTimeoutTime_MCPB" SG_ 496 CRC_PARK_DATA 0;
BA_ "GenSigTimeoutTime_SGCP" SG_ 496 CRC_PARK_DATA 0;
BA_ "GenSigTimeoutTime_TCM" SG_ 496 CRC_PARK_DATA 0;
BA_ "GenSigTimeoutTime_AGSM" SG_ 496 PlockFailSts 0;
BA_ "GenSigTimeoutTime_ECM" SG_ 496 PlockFailSts 0;
BA_ "GenSigTimeoutTime_MCPA" SG_ 496 PlockFailSts 0;
BA_ "GenSigTimeoutTime_MCPB" SG_ 496 PlockFailSts 0;
BA_ "GenSigTimeoutTime_SGCP" SG_ 496 PlockFailSts 0;
BA_ "GenSigTimeoutTime_TCM" SG_ 496 PlockFailSts 0;
BA_ "GenSigTimeoutTime_AGSM" SG_ 496 Plock_PosSensor 0;
BA_ "GenSigTimeoutTime_ECM" SG_ 496 Plock_PosSensor 0;
BA_ "GenSigTimeoutTime_MCPA" SG_ 496 Plock_PosSensor 0;
BA_ "GenSigTimeoutTime_MCPB" SG_ 496 Plock_PosSensor 0;
BA_ "GenSigTimeoutTime_SGCP" SG_ 496 Plock_PosSensor 0;
BA_ "GenSigTimeoutTime_TCM" SG_ 496 Plock_PosSensor 0;
BA_ "GenSigTimeoutTime_AGSM" SG_ 496 Plock_MotorPosSts 0;
BA_ "GenSigTimeoutTime_ECM" SG_ 496 Plock_MotorPosSts 0;
BA_ "GenSigTimeoutTime_MCPA" SG_ 496 Plock_MotorPosSts 0;
BA_ "GenSigTimeoutTime_MCPB" SG_ 496 Plock_MotorPosSts 0;
BA_ "GenSigTimeoutTime_SGCP" SG_ 496 Plock_MotorPosSts 0;
BA_ "GenSigTimeoutTime_TCM" SG_ 496 Plock_MotorPosSts 0;
BA_ "GenSigTimeoutTime_AGSM" SG_ 496 MPR_PosSensor 0;
BA_ "GenSigTimeoutTime_ECM" SG_ 496 MPR_PosSensor 0;
BA_ "GenSigTimeoutTime_MCPA" SG_ 496 MPR_PosSensor 0;
BA_ "GenSigTimeoutTime_MCPB" SG_ 496 MPR_PosSensor 0;
BA_ "GenSigTimeoutTime_SGCP" SG_ 496 MPR_PosSensor 0;
BA_ "GenSigTimeoutTime_TCM" SG_ 496 MPR_PosSensor 0;
BA_ "GenSigTimeoutTime_AGSM" SG_ 496 Plock_fdbk_sts 0;
BA_ "GenSigTimeoutTime_ECM" SG_ 496 Plock_fdbk_sts 0;
BA_ "GenSigTimeoutTime_MCPA" SG_ 496 Plock_fdbk_sts 0;
BA_ "GenSigTimeoutTime_MCPB" SG_ 496 Plock_fdbk_sts 0;
BA_ "GenSigTimeoutTime_SGCP" SG_ 496 Plock_fdbk_sts 0;
BA_ "GenSigTimeoutTime_TCM" SG_ 496 Plock_fdbk_sts 0;
BA_ "GenSigTimeoutTime_AGSM" SG_ 1454 MCPB_Service_Lamp_Request 0;
BA_ "GenSigTimeoutTime_ECM" SG_ 1454 MCPB_Service_Lamp_Request 0;
BA_ "GenSigTimeoutTime_MCPA" SG_ 1454 MCPB_Service_Lamp_Request 0;
BA_ "GenSigTimeoutTime_MCPB" SG_ 1454 MCPB_Service_Lamp_Request 0;
BA_ "GenSigTimeoutTime_SGCP" SG_ 1454 MCPB_Service_Lamp_Request 0;
BA_ "GenSigTimeoutTime_TCM" SG_ 1454 MCPB_Service_Lamp_Request 0;
BA_ "GenSigTimeoutTime_TCM" SG_ 1444 MCPA_Service_Lamp_Request 0;
BA_ "GenSigTimeoutTime_AGSM" SG_ 1444 MCPA_Service_Lamp_Request 0;
BA_ "GenSigTimeoutTime_ECM" SG_ 1444 MCPA_Service_Lamp_Request 0;
BA_ "GenSigTimeoutTime_MCPA" SG_ 1444 MCPA_Service_Lamp_Request 0;
BA_ "GenSigTimeoutTime_MCPB" SG_ 1444 MCPA_Service_Lamp_Request 0;
BA_ "GenSigTimeoutTime_SGCP" SG_ 1444 MCPA_Service_Lamp_Request 0;
BA_ "GenSigSendType" SG_ 105 T7_Sensor_Temp 3;
BA_ "GenSigTimeoutTime_AGSM" SG_ 105 T7_Sensor_Temp 0;
BA_ "GenSigTimeoutTime_ECM" SG_ 105 T7_Sensor_Temp 0;
BA_ "GenSigTimeoutTime_EVCU2" SG_ 105 T7_Sensor_Temp 0;
BA_ "GenSigTimeoutTime_TCM" SG_ 105 T7_Sensor_Temp 0;
BA_ "GenSigSendType" SG_ 105 T7_CoolantTempVldty 3;
BA_ "GenSigTimeoutTime_AGSM" SG_ 105 T7_CoolantTempVldty 0;
BA_ "GenSigTimeoutTime_ECM" SG_ 105 T7_CoolantTempVldty 0;
BA_ "GenSigTimeoutTime_EVCU2" SG_ 105 T7_CoolantTempVldty 0;
BA_ "GenSigTimeoutTime_TCM" SG_ 105 T7_CoolantTempVldty 0;
BA_ "GenSigSendType" SG_ 105 T4_Sensor_Temp 3;
BA_ "GenSigTimeoutTime_AGSM" SG_ 105 T4_Sensor_Temp 0;
BA_ "GenSigTimeoutTime_ECM" SG_ 105 T4_Sensor_Temp 0;
BA_ "GenSigTimeoutTime_EVCU2" SG_ 105 T4_Sensor_Temp 0;
BA_ "GenSigTimeoutTime_TCM" SG_ 105 T4_Sensor_Temp 0;
BA_ "GenSigStartValue" SG_ 105 PwrElecSnsr_TEMP 255;
BA_ "GenSigTimeoutTime_AGSM" SG_ 105 PwrElecSnsr_TEMP 0;
BA_ "GenSigTimeoutTime_ECM" SG_ 105 PwrElecSnsr_TEMP 0;
BA_ "GenSigTimeoutTime_EVCU2" SG_ 105 PwrElecSnsr_TEMP 0;
BA_ "GenSigTimeoutTime_MCPA" SG_ 105 PwrElecSnsr_TEMP 0;
BA_ "GenSigTimeoutTime_MCPB" SG_ 105 PwrElecSnsr_TEMP 0;
BA_ "GenSigTimeoutTime_TCM" SG_ 105 PwrElecSnsr_TEMP 0;
BA_ "GenSigStartValue" SG_ 105 PwrElecPmp_TEMP 255;
BA_ "GenSigTimeoutTime_AGSM" SG_ 105 PwrElecPmp_TEMP 0;
BA_ "GenSigTimeoutTime_ECM" SG_ 105 PwrElecPmp_TEMP 0;
BA_ "GenSigTimeoutTime_EVCU2" SG_ 105 PwrElecPmp_TEMP 0;
BA_ "GenSigTimeoutTime_MCPA" SG_ 105 PwrElecPmp_TEMP 0;
BA_ "GenSigTimeoutTime_MCPB" SG_ 105 PwrElecPmp_TEMP 0;
BA_ "GenSigTimeoutTime_TCM" SG_ 105 PwrElecPmp_TEMP 0;
BA_ "GenSigSendType" SG_ 105 PIMRR_CoolantFlow 3;
BA_ "GenSigTimeoutTime_AGSM" SG_ 105 PIMRR_CoolantFlow 0;
BA_ "GenSigTimeoutTime_ECM" SG_ 105 PIMRR_CoolantFlow 0;
BA_ "GenSigTimeoutTime_EVCU2" SG_ 105 PIMRR_CoolantFlow 0;
BA_ "GenSigTimeoutTime_MCPA" SG_ 105 PIMRR_CoolantFlow 0;
BA_ "GenSigTimeoutTime_MCPB" SG_ 105 PIMRR_CoolantFlow 0;
BA_ "GenSigTimeoutTime_TCM" SG_ 105 PIMRR_CoolantFlow 0;
BA_ "GenSigTimeoutTime_AGSM" SG_ 260 INVRRInterlockSts 0;
BA_ "GenSigTimeoutTime_ECM" SG_ 260 INVRRInterlockSts 0;
BA_ "GenSigTimeoutTime_MCPA" SG_ 260 INVRRInterlockSts 0;
BA_ "GenSigTimeoutTime_MCPB" SG_ 260 INVRRInterlockSts 0;
BA_ "GenSigTimeoutTime_SGCP" SG_ 260 INVRRInterlockSts 0;
BA_ "GenSigTimeoutTime_TCM" SG_ 260 INVRRInterlockSts 0;
BA_ "GenSigTimeoutTime_AGSM" SG_ 260 InvRR_DC_Voltage 0;
BA_ "GenSigTimeoutTime_ECM" SG_ 260 InvRR_DC_Voltage 0;
BA_ "GenSigTimeoutTime_MCPA" SG_ 260 InvRR_DC_Voltage 0;
BA_ "GenSigTimeoutTime_MCPB" SG_ 260 InvRR_DC_Voltage 0;
BA_ "GenSigTimeoutTime_SGCP" SG_ 260 InvRR_DC_Voltage 0;
BA_ "GenSigTimeoutTime_TCM" SG_ 260 InvRR_DC_Voltage 0;
BA_ "GenSigTimeoutTime_AGSM" SG_ 260 InvRR_DerateReason 0;
BA_ "GenSigTimeoutTime_ECM" SG_ 260 InvRR_DerateReason 0;
BA_ "GenSigTimeoutTime_MCPA" SG_ 260 InvRR_DerateReason 0;
BA_ "GenSigTimeoutTime_MCPB" SG_ 260 InvRR_DerateReason 0;
BA_ "GenSigTimeoutTime_SGCP" SG_ 260 InvRR_DerateReason 0;
BA_ "GenSigTimeoutTime_TCM" SG_ 260 InvRR_DerateReason 0;
BA_ "GenSigTimeoutTime_AGSM" SG_ 260 InvRR_ACVoltage 0;
BA_ "GenSigTimeoutTime_ECM" SG_ 260 InvRR_ACVoltage 0;
BA_ "GenSigTimeoutTime_MCPA" SG_ 260 InvRR_ACVoltage 0;
BA_ "GenSigTimeoutTime_MCPB" SG_ 260 InvRR_ACVoltage 0;
BA_ "GenSigTimeoutTime_SGCP" SG_ 260 InvRR_ACVoltage 0;
BA_ "GenSigTimeoutTime_TCM" SG_ 260 InvRR_ACVoltage 0;
BA_ "GenSigStartValue" SG_ 260 RPM_MCPB 32768;
BA_ "GenSigTimeoutTime_AGSM" SG_ 260 RPM_MCPB 0;
BA_ "GenSigTimeoutTime_ECM" SG_ 260 RPM_MCPB 0;
BA_ "GenSigTimeoutTime_MCPA" SG_ 260 RPM_MCPB 0;
BA_ "GenSigTimeoutTime_MCPB" SG_ 260 RPM_MCPB 0;
BA_ "GenSigTimeoutTime_SGCP" SG_ 260 RPM_MCPB 0;
BA_ "GenSigTimeoutTime_TCM" SG_ 260 RPM_MCPB 0;
BA_ "GenSigTimeoutTime_AGSM" SG_ 260 MCPB_Torque_Achieved_V 0;
BA_ "GenSigTimeoutTime_ECM" SG_ 260 MCPB_Torque_Achieved_V 0;
BA_ "GenSigTimeoutTime_MCPA" SG_ 260 MCPB_Torque_Achieved_V 0;
BA_ "GenSigTimeoutTime_MCPB" SG_ 260 MCPB_Torque_Achieved_V 0;
BA_ "GenSigTimeoutTime_SGCP" SG_ 260 MCPB_Torque_Achieved_V 0;
BA_ "GenSigTimeoutTime_TCM" SG_ 260 MCPB_Torque_Achieved_V 0;
BA_ "GenSigStartValue" SG_ 260 MCPB_Torque_Achieved 4096;
BA_ "GenSigTimeoutTime_AGSM" SG_ 260 MCPB_Torque_Achieved 0;
BA_ "GenSigTimeoutTime_ECM" SG_ 260 MCPB_Torque_Achieved 0;
BA_ "GenSigTimeoutTime_MCPA" SG_ 260 MCPB_Torque_Achieved 0;
BA_ "GenSigTimeoutTime_MCPB" SG_ 260 MCPB_Torque_Achieved 0;
BA_ "GenSigTimeoutTime_SGCP" SG_ 260 MCPB_Torque_Achieved 0;
BA_ "GenSigTimeoutTime_TCM" SG_ 260 MCPB_Torque_Achieved 0;
BA_ "GenSigTimeoutTime_AGSM" SG_ 260 MCPB_TorqAchieved_AEMD_V 0;
BA_ "GenSigTimeoutTime_ECM" SG_ 260 MCPB_TorqAchieved_AEMD_V 0;
BA_ "GenSigTimeoutTime_MCPA" SG_ 260 MCPB_TorqAchieved_AEMD_V 0;
BA_ "GenSigTimeoutTime_MCPB" SG_ 260 MCPB_TorqAchieved_AEMD_V 0;
BA_ "GenSigTimeoutTime_SGCP" SG_ 260 MCPB_TorqAchieved_AEMD_V 0;
BA_ "GenSigTimeoutTime_TCM" SG_ 260 MCPB_TorqAchieved_AEMD_V 0;
BA_ "GenSigStartValue" SG_ 260 MCPB_TorqAchieved_AEMD 4096;
BA_ "GenSigTimeoutTime_AGSM" SG_ 260 MCPB_TorqAchieved_AEMD 0;
BA_ "GenSigTimeoutTime_ECM" SG_ 260 MCPB_TorqAchieved_AEMD 0;
BA_ "GenSigTimeoutTime_MCPA" SG_ 260 MCPB_TorqAchieved_AEMD 0;
BA_ "GenSigTimeoutTime_MCPB" SG_ 260 MCPB_TorqAchieved_AEMD 0;
BA_ "GenSigTimeoutTime_SGCP" SG_ 260 MCPB_TorqAchieved_AEMD 0;
BA_ "GenSigTimeoutTime_TCM" SG_ 260 MCPB_TorqAchieved_AEMD 0;
BA_ "GenSigTimeoutTime_AGSM" SG_ 260 MCPB_Spd_Lim 0;
BA_ "GenSigTimeoutTime_ECM" SG_ 260 MCPB_Spd_Lim 0;
BA_ "GenSigTimeoutTime_MCPA" SG_ 260 MCPB_Spd_Lim 0;
BA_ "GenSigTimeoutTime_MCPB" SG_ 260 MCPB_Spd_Lim 0;
BA_ "GenSigTimeoutTime_SGCP" SG_ 260 MCPB_Spd_Lim 0;
BA_ "GenSigTimeoutTime_TCM" SG_ 260 MCPB_Spd_Lim 0;
BA_ "GenSigTimeoutTime_AGSM" SG_ 260 MCPB_RPM_V 0;
BA_ "GenSigTimeoutTime_ECM" SG_ 260 MCPB_RPM_V 0;
BA_ "GenSigTimeoutTime_MCPA" SG_ 260 MCPB_RPM_V 0;
BA_ "GenSigTimeoutTime_MCPB" SG_ 260 MCPB_RPM_V 0;
BA_ "GenSigTimeoutTime_SGCP" SG_ 260 MCPB_RPM_V 0;
BA_ "GenSigTimeoutTime_TCM" SG_ 260 MCPB_RPM_V 0;
BA_ "GenSigStartValue" SG_ 260 MCPB_MtrMinCpbltyTrq 4096;
BA_ "GenSigTimeoutTime_AGSM" SG_ 260 MCPB_MtrMinCpbltyTrq 0;
BA_ "GenSigTimeoutTime_ECM" SG_ 260 MCPB_MtrMinCpbltyTrq 0;
BA_ "GenSigTimeoutTime_MCPA" SG_ 260 MCPB_MtrMinCpbltyTrq 0;
BA_ "GenSigTimeoutTime_MCPB" SG_ 260 MCPB_MtrMinCpbltyTrq 0;
BA_ "GenSigTimeoutTime_SGCP" SG_ 260 MCPB_MtrMinCpbltyTrq 0;
BA_ "GenSigTimeoutTime_TCM" SG_ 260 MCPB_MtrMinCpbltyTrq 0;
BA_ "GenSigStartValue" SG_ 260 MCPB_MtrMaxCpbltyTrq 4096;
BA_ "GenSigTimeoutTime_AGSM" SG_ 260 MCPB_MtrMaxCpbltyTrq 0;
BA_ "GenSigTimeoutTime_ECM" SG_ 260 MCPB_MtrMaxCpbltyTrq 0;
BA_ "GenSigTimeoutTime_MCPA" SG_ 260 MCPB_MtrMaxCpbltyTrq 0;
BA_ "GenSigTimeoutTime_MCPB" SG_ 260 MCPB_MtrMaxCpbltyTrq 0;
BA_ "GenSigTimeoutTime_SGCP" SG_ 260 MCPB_MtrMaxCpbltyTrq 0;
BA_ "GenSigTimeoutTime_TCM" SG_ 260 MCPB_MtrMaxCpbltyTrq 0;
BA_ "GenSigTimeoutTime_AGSM" SG_ 260 MCPB_MtrIndex 0;
BA_ "GenSigTimeoutTime_ECM" SG_ 260 MCPB_MtrIndex 0;
BA_ "GenSigTimeoutTime_MCPA" SG_ 260 MCPB_MtrIndex 0;
BA_ "GenSigTimeoutTime_MCPB" SG_ 260 MCPB_MtrIndex 0;
BA_ "GenSigTimeoutTime_SGCP" SG_ 260 MCPB_MtrIndex 0;
BA_ "GenSigTimeoutTime_TCM" SG_ 260 MCPB_MtrIndex 0;
BA_ "GenSigStartValue" SG_ 260 MCPB_MinTorq 4096;
BA_ "GenSigTimeoutTime_AGSM" SG_ 260 MCPB_MinTorq 0;
BA_ "GenSigTimeoutTime_ECM" SG_ 260 MCPB_MinTorq 0;
BA_ "GenSigTimeoutTime_MCPA" SG_ 260 MCPB_MinTorq 0;
BA_ "GenSigTimeoutTime_MCPB" SG_ 260 MCPB_MinTorq 0;
BA_ "GenSigTimeoutTime_SGCP" SG_ 260 MCPB_MinTorq 0;
BA_ "GenSigTimeoutTime_TCM" SG_ 260 MCPB_MinTorq 0;
BA_ "GenSigStartValue" SG_ 260 MCPB_MaxTorq 4096;
BA_ "GenSigTimeoutTime_AGSM" SG_ 260 MCPB_MaxTorq 0;
BA_ "GenSigTimeoutTime_ECM" SG_ 260 MCPB_MaxTorq 0;
BA_ "GenSigTimeoutTime_MCPA" SG_ 260 MCPB_MaxTorq 0;
BA_ "GenSigTimeoutTime_MCPB" SG_ 260 MCPB_MaxTorq 0;
BA_ "GenSigTimeoutTime_SGCP" SG_ 260 MCPB_MaxTorq 0;
BA_ "GenSigTimeoutTime_TCM" SG_ 260 MCPB_MaxTorq 0;
BA_ "GenSigTimeoutTime_AGSM" SG_ 260 MCPB_Invrtr_State 0;
BA_ "GenSigTimeoutTime_ECM" SG_ 260 MCPB_Invrtr_State 0;
BA_ "GenSigTimeoutTime_MCPA" SG_ 260 MCPB_Invrtr_State 0;
BA_ "GenSigTimeoutTime_MCPB" SG_ 260 MCPB_Invrtr_State 0;
BA_ "GenSigTimeoutTime_SGCP" SG_ 260 MCPB_Invrtr_State 0;
BA_ "GenSigTimeoutTime_TCM" SG_ 260 MCPB_Invrtr_State 0;
BA_ "GenSigTimeoutTime_AGSM" SG_ 260 MCPB_HV_CnctrOpn_Req 0;
BA_ "GenSigTimeoutTime_ECM" SG_ 260 MCPB_HV_CnctrOpn_Req 0;
BA_ "GenSigTimeoutTime_MCPA" SG_ 260 MCPB_HV_CnctrOpn_Req 0;
BA_ "GenSigTimeoutTime_MCPB" SG_ 260 MCPB_HV_CnctrOpn_Req 0;
BA_ "GenSigTimeoutTime_SGCP" SG_ 260 MCPB_HV_CnctrOpn_Req 0;
BA_ "GenSigTimeoutTime_TCM" SG_ 260 MCPB_HV_CnctrOpn_Req 0;
BA_ "GenSigTimeoutTime_AGSM" SG_ 260 MCPB_Dschrge_Status 0;
BA_ "GenSigTimeoutTime_ECM" SG_ 260 MCPB_Dschrge_Status 0;
BA_ "GenSigTimeoutTime_MCPA" SG_ 260 MCPB_Dschrge_Status 0;
BA_ "GenSigTimeoutTime_MCPB" SG_ 260 MCPB_Dschrge_Status 0;
BA_ "GenSigTimeoutTime_SGCP" SG_ 260 MCPB_Dschrge_Status 0;
BA_ "GenSigTimeoutTime_TCM" SG_ 260 MCPB_Dschrge_Status 0;
BA_ "GenSigTimeoutTime_AGSM" SG_ 260 MCPB_DeratingFactor 0;
BA_ "GenSigTimeoutTime_ECM" SG_ 260 MCPB_DeratingFactor 0;
BA_ "GenSigTimeoutTime_MCPA" SG_ 260 MCPB_DeratingFactor 0;
BA_ "GenSigTimeoutTime_MCPB" SG_ 260 MCPB_DeratingFactor 0;
BA_ "GenSigTimeoutTime_SGCP" SG_ 260 MCPB_DeratingFactor 0;
BA_ "GenSigTimeoutTime_TCM" SG_ 260 MCPB_DeratingFactor 0;
BA_ "GenSigTimeoutTime_AGSM" SG_ 260 MCPB_DC_Volt_V 0;
BA_ "GenSigTimeoutTime_ECM" SG_ 260 MCPB_DC_Volt_V 0;
BA_ "GenSigTimeoutTime_MCPA" SG_ 260 MCPB_DC_Volt_V 0;
BA_ "GenSigTimeoutTime_MCPB" SG_ 260 MCPB_DC_Volt_V 0;
BA_ "GenSigTimeoutTime_SGCP" SG_ 260 MCPB_DC_Volt_V 0;
BA_ "GenSigTimeoutTime_TCM" SG_ 260 MCPB_DC_Volt_V 0;
BA_ "GenSigTimeoutTime_AGSM" SG_ 260 MCPB_DC_Current_V 0;
BA_ "GenSigTimeoutTime_ECM" SG_ 260 MCPB_DC_Current_V 0;
BA_ "GenSigTimeoutTime_MCPA" SG_ 260 MCPB_DC_Current_V 0;
BA_ "GenSigTimeoutTime_MCPB" SG_ 260 MCPB_DC_Current_V 0;
BA_ "GenSigTimeoutTime_SGCP" SG_ 260 MCPB_DC_Current_V 0;
BA_ "GenSigTimeoutTime_TCM" SG_ 260 MCPB_DC_Current_V 0;
BA_ "GenSigStartValue" SG_ 260 MCPB_DC_Current 16384;
BA_ "GenSigTimeoutTime_AGSM" SG_ 260 MCPB_DC_Current 0;
BA_ "GenSigTimeoutTime_ECM" SG_ 260 MCPB_DC_Current 0;
BA_ "GenSigTimeoutTime_MCPA" SG_ 260 MCPB_DC_Current 0;
BA_ "GenSigTimeoutTime_MCPB" SG_ 260 MCPB_DC_Current 0;
BA_ "GenSigTimeoutTime_SGCP" SG_ 260 MCPB_DC_Current 0;
BA_ "GenSigTimeoutTime_TCM" SG_ 260 MCPB_DC_Current 0;
BA_ "GenSigTimeoutTime_AGSM" SG_ 260 MCPB_CpbltySpdDivVolt 0;
BA_ "GenSigTimeoutTime_ECM" SG_ 260 MCPB_CpbltySpdDivVolt 0;
BA_ "GenSigTimeoutTime_MCPA" SG_ 260 MCPB_CpbltySpdDivVolt 0;
BA_ "GenSigTimeoutTime_MCPB" SG_ 260 MCPB_CpbltySpdDivVolt 0;
BA_ "GenSigTimeoutTime_SGCP" SG_ 260 MCPB_CpbltySpdDivVolt 0;
BA_ "GenSigTimeoutTime_TCM" SG_ 260 MCPB_CpbltySpdDivVolt 0;
BA_ "GenSigTimeoutTime_AGSM" SG_ 260 MCPB_AccelRawV 0;
BA_ "GenSigTimeoutTime_ECM" SG_ 260 MCPB_AccelRawV 0;
BA_ "GenSigTimeoutTime_MCPA" SG_ 260 MCPB_AccelRawV 0;
BA_ "GenSigTimeoutTime_MCPB" SG_ 260 MCPB_AccelRawV 0;
BA_ "GenSigTimeoutTime_SGCP" SG_ 260 MCPB_AccelRawV 0;
BA_ "GenSigTimeoutTime_TCM" SG_ 260 MCPB_AccelRawV 0;
BA_ "GenSigTimeoutTime_AGSM" SG_ 260 MCPB_AccelRaw 0;
BA_ "GenSigTimeoutTime_ECM" SG_ 260 MCPB_AccelRaw 0;
BA_ "GenSigTimeoutTime_MCPA" SG_ 260 MCPB_AccelRaw 0;
BA_ "GenSigTimeoutTime_MCPB" SG_ 260 MCPB_AccelRaw 0;
BA_ "GenSigTimeoutTime_SGCP" SG_ 260 MCPB_AccelRaw 0;
BA_ "GenSigTimeoutTime_TCM" SG_ 260 MCPB_AccelRaw 0;
BA_ "GenSigTimeoutTime_AGSM" SG_ 260 MCPB_6SO_Status 0;
BA_ "GenSigTimeoutTime_ECM" SG_ 260 MCPB_6SO_Status 0;
BA_ "GenSigTimeoutTime_MCPA" SG_ 260 MCPB_6SO_Status 0;
BA_ "GenSigTimeoutTime_MCPB" SG_ 260 MCPB_6SO_Status 0;
BA_ "GenSigTimeoutTime_SGCP" SG_ 260 MCPB_6SO_Status 0;
BA_ "GenSigTimeoutTime_TCM" SG_ 260 MCPB_6SO_Status 0;
BA_ "GenSigTimeoutTime_AGSM" SG_ 260 MCPB_3PS_Pos 0;
BA_ "GenSigTimeoutTime_ECM" SG_ 260 MCPB_3PS_Pos 0;
BA_ "GenSigTimeoutTime_MCPA" SG_ 260 MCPB_3PS_Pos 0;
BA_ "GenSigTimeoutTime_MCPB" SG_ 260 MCPB_3PS_Pos 0;
BA_ "GenSigTimeoutTime_SGCP" SG_ 260 MCPB_3PS_Pos 0;
BA_ "GenSigTimeoutTime_TCM" SG_ 260 MCPB_3PS_Pos 0;
BA_ "GenSigTimeoutTime_AGSM" SG_ 260 MC_PRR1 0;
BA_ "GenSigTimeoutTime_ECM" SG_ 260 MC_PRR1 0;
BA_ "GenSigTimeoutTime_MCPA" SG_ 260 MC_PRR1 0;
BA_ "GenSigTimeoutTime_MCPB" SG_ 260 MC_PRR1 0;
BA_ "GenSigTimeoutTime_SGCP" SG_ 260 MC_PRR1 0;
BA_ "GenSigTimeoutTime_TCM" SG_ 260 MC_PRR1 0;
BA_ "GenSigTimeoutTime_AGSM" SG_ 260 InvRR_CoolantTemp 0;
BA_ "GenSigTimeoutTime_ECM" SG_ 260 InvRR_CoolantTemp 0;
BA_ "GenSigTimeoutTime_MCPA" SG_ 260 InvRR_CoolantTemp 0;
BA_ "GenSigTimeoutTime_MCPB" SG_ 260 InvRR_CoolantTemp 0;
BA_ "GenSigTimeoutTime_SGCP" SG_ 260 InvRR_CoolantTemp 0;
BA_ "GenSigTimeoutTime_TCM" SG_ 260 InvRR_CoolantTemp 0;
BA_ "GenSigTimeoutTime_AGSM" SG_ 260 CRC_PRR1 0;
BA_ "GenSigTimeoutTime_ECM" SG_ 260 CRC_PRR1 0;
BA_ "GenSigTimeoutTime_MCPA" SG_ 260 CRC_PRR1 0;
BA_ "GenSigTimeoutTime_MCPB" SG_ 260 CRC_PRR1 0;
BA_ "GenSigTimeoutTime_SGCP" SG_ 260 CRC_PRR1 0;
BA_ "GenSigTimeoutTime_TCM" SG_ 260 CRC_PRR1 0;
BA_ "GenSigTimeoutTime_AGSM" SG_ 260 MCPB_SPT_Stat 0;
BA_ "GenSigTimeoutTime_ECM" SG_ 260 MCPB_SPT_Stat 0;
BA_ "GenSigTimeoutTime_MCPA" SG_ 260 MCPB_SPT_Stat 0;
BA_ "GenSigTimeoutTime_MCPB" SG_ 260 MCPB_SPT_Stat 0;
BA_ "GenSigTimeoutTime_SGCP" SG_ 260 MCPB_SPT_Stat 0;
BA_ "GenSigTimeoutTime_TCM" SG_ 260 MCPB_SPT_Stat 0;
BA_ "GenSigStartValue" SG_ 1062 MCPA_Temp 40;
BA_ "GenSigTimeoutTime_AGSM" SG_ 1062 MCPA_Temp 0;
BA_ "GenSigTimeoutTime_ECM" SG_ 1062 MCPA_Temp 0;
BA_ "GenSigTimeoutTime_MCPA" SG_ 1062 MCPA_Temp 0;
BA_ "GenSigTimeoutTime_MCPB" SG_ 1062 MCPA_Temp 0;
BA_ "GenSigTimeoutTime_SGCP" SG_ 1062 MCPA_Temp 0;
BA_ "GenSigTimeoutTime_TCM" SG_ 1062 MCPA_Temp 0;
BA_ "GenSigStartValue" SG_ 1062 MCPA_Rotor_Temperature 255;
BA_ "GenSigTimeoutTime_AGSM" SG_ 1062 MCPA_Rotor_Temperature 0;
BA_ "GenSigTimeoutTime_ECM" SG_ 1062 MCPA_Rotor_Temperature 0;
BA_ "GenSigTimeoutTime_MCPA" SG_ 1062 MCPA_Rotor_Temperature 0;
BA_ "GenSigTimeoutTime_MCPB" SG_ 1062 MCPA_Rotor_Temperature 0;
BA_ "GenSigTimeoutTime_SGCP" SG_ 1062 MCPA_Rotor_Temperature 0;
BA_ "GenSigTimeoutTime_TCM" SG_ 1062 MCPA_Rotor_Temperature 0;
BA_ "GenSigStartValue" SG_ 1062 MCPA_Inverter_Temp 40;
BA_ "GenSigTimeoutTime_AGSM" SG_ 1062 MCPA_Inverter_Temp 0;
BA_ "GenSigTimeoutTime_ECM" SG_ 1062 MCPA_Inverter_Temp 0;
BA_ "GenSigTimeoutTime_MCPA" SG_ 1062 MCPA_Inverter_Temp 0;
BA_ "GenSigTimeoutTime_MCPB" SG_ 1062 MCPA_Inverter_Temp 0;
BA_ "GenSigTimeoutTime_SGCP" SG_ 1062 MCPA_Inverter_Temp 0;
BA_ "GenSigTimeoutTime_TCM" SG_ 1062 MCPA_Inverter_Temp 0;
BA_ "GenSigStartValue" SG_ 1062 MCPA_Control_Board_Temperature 255;
BA_ "GenSigTimeoutTime_AGSM" SG_ 1062 MCPA_Control_Board_Temperature 0;
BA_ "GenSigTimeoutTime_ECM" SG_ 1062 MCPA_Control_Board_Temperature 0;
BA_ "GenSigTimeoutTime_MCPA" SG_ 1062 MCPA_Control_Board_Temperature 0;
BA_ "GenSigTimeoutTime_MCPB" SG_ 1062 MCPA_Control_Board_Temperature 0;
BA_ "GenSigTimeoutTime_SGCP" SG_ 1062 MCPA_Control_Board_Temperature 0;
BA_ "GenSigTimeoutTime_TCM" SG_ 1062 MCPA_Control_Board_Temperature 0;
BA_ "GenSigTimeoutTime_AGSM" SG_ 1062 CLrDiagInfo_MCPA 0;
BA_ "GenSigTimeoutTime_ECM" SG_ 1062 CLrDiagInfo_MCPA 0;
BA_ "GenSigTimeoutTime_MCPA" SG_ 1062 CLrDiagInfo_MCPA 0;
BA_ "GenSigTimeoutTime_MCPB" SG_ 1062 CLrDiagInfo_MCPA 0;
BA_ "GenSigTimeoutTime_SGCP" SG_ 1062 CLrDiagInfo_MCPA 0;
BA_ "GenSigTimeoutTime_TCM" SG_ 1062 CLrDiagInfo_MCPA 0;
BA_ "GenSigTimeoutTime_AGSM" SG_ 1062 MessageCounter_MCPA_DATA2 0;
BA_ "GenSigTimeoutTime_ECM" SG_ 1062 MessageCounter_MCPA_DATA2 0;
BA_ "GenSigTimeoutTime_MCPA" SG_ 1062 MessageCounter_MCPA_DATA2 0;
BA_ "GenSigTimeoutTime_MCPB" SG_ 1062 MessageCounter_MCPA_DATA2 0;
BA_ "GenSigTimeoutTime_SGCP" SG_ 1062 MessageCounter_MCPA_DATA2 0;
BA_ "GenSigTimeoutTime_TCM" SG_ 1062 MessageCounter_MCPA_DATA2 0;
BA_ "GenSigTimeoutTime_AGSM" SG_ 1062 CRC_MCPA_DATA2 0;
BA_ "GenSigTimeoutTime_ECM" SG_ 1062 CRC_MCPA_DATA2 0;
BA_ "GenSigTimeoutTime_MCPA" SG_ 1062 CRC_MCPA_DATA2 0;
BA_ "GenSigTimeoutTime_MCPB" SG_ 1062 CRC_MCPA_DATA2 0;
BA_ "GenSigTimeoutTime_SGCP" SG_ 1062 CRC_MCPA_DATA2 0;
BA_ "GenSigTimeoutTime_TCM" SG_ 1062 CRC_MCPA_DATA2 0;
BA_ "GenSigTimeoutTime_AGSM" SG_ 1062 MCPA_PIM_DC_Side_Busbar_Temp 0;
BA_ "GenSigTimeoutTime_ECM" SG_ 1062 MCPA_PIM_DC_Side_Busbar_Temp 0;
BA_ "GenSigTimeoutTime_MCPA" SG_ 1062 MCPA_PIM_DC_Side_Busbar_Temp 0;
BA_ "GenSigTimeoutTime_MCPB" SG_ 1062 MCPA_PIM_DC_Side_Busbar_Temp 0;
BA_ "GenSigTimeoutTime_SGCP" SG_ 1062 MCPA_PIM_DC_Side_Busbar_Temp 0;
BA_ "GenSigTimeoutTime_TCM" SG_ 1062 MCPA_PIM_DC_Side_Busbar_Temp 0;
BA_ "GenSigTimeoutTime_AGSM" SG_ 1062 MCPA_Service_Lamp_Request_2 0;
BA_ "GenSigTimeoutTime_ECM" SG_ 1062 MCPA_Service_Lamp_Request_2 0;
BA_ "GenSigTimeoutTime_MCPA" SG_ 1062 MCPA_Service_Lamp_Request_2 0;
BA_ "GenSigTimeoutTime_MCPB" SG_ 1062 MCPA_Service_Lamp_Request_2 0;
BA_ "GenSigTimeoutTime_SGCP" SG_ 1062 MCPA_Service_Lamp_Request_2 0;
BA_ "GenSigTimeoutTime_TCM" SG_ 1062 MCPA_Service_Lamp_Request_2 0;
BA_ "GenSigTimeoutTime_AGSM" SG_ 300 UDCMax_Unlim_MCPB 0;
BA_ "GenSigTimeoutTime_ECM" SG_ 300 UDCMax_Unlim_MCPB 0;
BA_ "GenSigTimeoutTime_EVCU2" SG_ 300 UDCMax_Unlim_MCPB 0;
BA_ "GenSigTimeoutTime_MCPA" SG_ 300 UDCMax_Unlim_MCPB 0;
BA_ "GenSigTimeoutTime_SGCP" SG_ 300 UDCMax_Unlim_MCPB 0;
BA_ "GenSigTimeoutTime_TCM" SG_ 300 UDCMax_Unlim_MCPB 0;
BA_ "GenSigTimeoutTime_ECM" SG_ 300 UDCMax_Unlim_MCPA 0;
BA_ "GenSigTimeoutTime_EVCU2" SG_ 300 UDCMax_Unlim_MCPA 0;
BA_ "GenSigTimeoutTime_MCPB" SG_ 300 UDCMax_Unlim_MCPA 0;
BA_ "GenSigTimeoutTime_SGCP" SG_ 300 UDCMax_Unlim_MCPA 0;
BA_ "GenSigTimeoutTime_TCM" SG_ 300 UDCMax_Unlim_MCPA 0;
BA_ "GenSigTimeoutTime_AGSM" SG_ 300 UDCMax_Unlim_MCPA 0;
BA_ "GenSigTimeoutTime_AGSM" SG_ 300 TqGrdtLim_MCPB 0;
BA_ "GenSigTimeoutTime_ECM" SG_ 300 TqGrdtLim_MCPB 0;
BA_ "GenSigTimeoutTime_EVCU2" SG_ 300 TqGrdtLim_MCPB 0;
BA_ "GenSigTimeoutTime_MCPA" SG_ 300 TqGrdtLim_MCPB 0;
BA_ "GenSigTimeoutTime_SGCP" SG_ 300 TqGrdtLim_MCPB 0;
BA_ "GenSigTimeoutTime_TCM" SG_ 300 TqGrdtLim_MCPB 0;
BA_ "GenSigTimeoutTime_AGSM" SG_ 300 TqGrdtLim_MCPA 0;
BA_ "GenSigTimeoutTime_ECM" SG_ 300 TqGrdtLim_MCPA 0;
BA_ "GenSigTimeoutTime_EVCU2" SG_ 300 TqGrdtLim_MCPA 0;
BA_ "GenSigTimeoutTime_MCPB" SG_ 300 TqGrdtLim_MCPA 0;
BA_ "GenSigTimeoutTime_SGCP" SG_ 300 TqGrdtLim_MCPA 0;
BA_ "GenSigTimeoutTime_TCM" SG_ 300 TqGrdtLim_MCPA 0;
BA_ "GenSigStartValue" SG_ 300 TorqueCommand_MCPB 4096;
BA_ "GenSigTimeoutTime_AGSM" SG_ 300 TorqueCommand_MCPB 0;
BA_ "GenSigTimeoutTime_ECM" SG_ 300 TorqueCommand_MCPB 0;
BA_ "GenSigTimeoutTime_EVCU2" SG_ 300 TorqueCommand_MCPB 0;
BA_ "GenSigTimeoutTime_MCPA" SG_ 300 TorqueCommand_MCPB 0;
BA_ "GenSigTimeoutTime_SGCP" SG_ 300 TorqueCommand_MCPB 0;
BA_ "GenSigTimeoutTime_TCM" SG_ 300 TorqueCommand_MCPB 0;
BA_ "GenSigStartValue" SG_ 300 TorqueCommand_MCPA 4096;
BA_ "GenSigTimeoutTime_AGSM" SG_ 300 TorqueCommand_MCPA 0;
BA_ "GenSigTimeoutTime_ECM" SG_ 300 TorqueCommand_MCPA 0;
BA_ "GenSigTimeoutTime_EVCU2" SG_ 300 TorqueCommand_MCPA 0;
BA_ "GenSigTimeoutTime_MCPB" SG_ 300 TorqueCommand_MCPA 0;
BA_ "GenSigTimeoutTime_SGCP" SG_ 300 TorqueCommand_MCPA 0;
BA_ "GenSigTimeoutTime_TCM" SG_ 300 TorqueCommand_MCPA 0;
BA_ "GenSigStartValue" SG_ 300 TargetMotorRPM_MCPB 32768;
BA_ "GenSigTimeoutTime_AGSM" SG_ 300 TargetMotorRPM_MCPB 0;
BA_ "GenSigTimeoutTime_ECM" SG_ 300 TargetMotorRPM_MCPB 0;
BA_ "GenSigTimeoutTime_EVCU2" SG_ 300 TargetMotorRPM_MCPB 0;
BA_ "GenSigTimeoutTime_MCPA" SG_ 300 TargetMotorRPM_MCPB 0;
BA_ "GenSigTimeoutTime_SGCP" SG_ 300 TargetMotorRPM_MCPB 0;
BA_ "GenSigTimeoutTime_TCM" SG_ 300 TargetMotorRPM_MCPB 0;
BA_ "GenSigStartValue" SG_ 300 TargetMotorRPM_MCPA 32768;
BA_ "GenSigTimeoutTime_AGSM" SG_ 300 TargetMotorRPM_MCPA 0;
BA_ "GenSigTimeoutTime_ECM" SG_ 300 TargetMotorRPM_MCPA 0;
BA_ "GenSigTimeoutTime_EVCU2" SG_ 300 TargetMotorRPM_MCPA 0;
BA_ "GenSigTimeoutTime_MCPB" SG_ 300 TargetMotorRPM_MCPA 0;
BA_ "GenSigTimeoutTime_SGCP" SG_ 300 TargetMotorRPM_MCPA 0;
BA_ "GenSigTimeoutTime_TCM" SG_ 300 TargetMotorRPM_MCPA 0;
BA_ "GenSigTimeoutTime_AGSM" SG_ 300 SpdGrdtLim_MCPB 0;
BA_ "GenSigTimeoutTime_ECM" SG_ 300 SpdGrdtLim_MCPB 0;
BA_ "GenSigTimeoutTime_EVCU2" SG_ 300 SpdGrdtLim_MCPB 0;
BA_ "GenSigTimeoutTime_MCPA" SG_ 300 SpdGrdtLim_MCPB 0;
BA_ "GenSigTimeoutTime_SGCP" SG_ 300 SpdGrdtLim_MCPB 0;
BA_ "GenSigTimeoutTime_TCM" SG_ 300 SpdGrdtLim_MCPB 0;
BA_ "GenSigTimeoutTime_AGSM" SG_ 300 SpdGrdtLim_MCPA 0;
BA_ "GenSigTimeoutTime_ECM" SG_ 300 SpdGrdtLim_MCPA 0;
BA_ "GenSigTimeoutTime_EVCU2" SG_ 300 SpdGrdtLim_MCPA 0;
BA_ "GenSigTimeoutTime_MCPB" SG_ 300 SpdGrdtLim_MCPA 0;
BA_ "GenSigTimeoutTime_SGCP" SG_ 300 SpdGrdtLim_MCPA 0;
BA_ "GenSigTimeoutTime_TCM" SG_ 300 SpdGrdtLim_MCPA 0;
BA_ "GenSigTimeoutTime_AGSM" SG_ 300 Mtr_6SO_Request_MCPB 0;
BA_ "GenSigTimeoutTime_ECM" SG_ 300 Mtr_6SO_Request_MCPB 0;
BA_ "GenSigTimeoutTime_EVCU2" SG_ 300 Mtr_6SO_Request_MCPB 0;
BA_ "GenSigTimeoutTime_MCPA" SG_ 300 Mtr_6SO_Request_MCPB 0;
BA_ "GenSigTimeoutTime_SGCP" SG_ 300 Mtr_6SO_Request_MCPB 0;
BA_ "GenSigTimeoutTime_TCM" SG_ 300 Mtr_6SO_Request_MCPB 0;
BA_ "GenSigTimeoutTime_AGSM" SG_ 300 Mtr_6SO_Request_MCPA 0;
BA_ "GenSigTimeoutTime_ECM" SG_ 300 Mtr_6SO_Request_MCPA 0;
BA_ "GenSigTimeoutTime_EVCU2" SG_ 300 Mtr_6SO_Request_MCPA 0;
BA_ "GenSigTimeoutTime_MCPB" SG_ 300 Mtr_6SO_Request_MCPA 0;
BA_ "GenSigTimeoutTime_SGCP" SG_ 300 Mtr_6SO_Request_MCPA 0;
BA_ "GenSigTimeoutTime_TCM" SG_ 300 Mtr_6SO_Request_MCPA 0;
BA_ "GenSigTimeoutTime_ECM" SG_ 300 ModeCommand_MCPB 0;
BA_ "GenSigTimeoutTime_EVCU2" SG_ 300 ModeCommand_MCPB 0;
BA_ "GenSigTimeoutTime_MCPA" SG_ 300 ModeCommand_MCPB 0;
BA_ "GenSigTimeoutTime_SGCP" SG_ 300 ModeCommand_MCPB 0;
BA_ "GenSigTimeoutTime_TCM" SG_ 300 ModeCommand_MCPB 0;
BA_ "GenSigTimeoutTime_AGSM" SG_ 300 ModeCommand_MCPB 0;
BA_ "GenSigTimeoutTime_AGSM" SG_ 300 ModeCommand_MCPA 0;
BA_ "GenSigTimeoutTime_ECM" SG_ 300 ModeCommand_MCPA 0;
BA_ "GenSigTimeoutTime_EVCU2" SG_ 300 ModeCommand_MCPA 0;
BA_ "GenSigTimeoutTime_MCPB" SG_ 300 ModeCommand_MCPA 0;
BA_ "GenSigTimeoutTime_SGCP" SG_ 300 ModeCommand_MCPA 0;
BA_ "GenSigTimeoutTime_TCM" SG_ 300 ModeCommand_MCPA 0;
BA_ "GenSigTimeoutTime_AGSM" SG_ 300 MessageCounter_INVTARGET1 0;
BA_ "GenSigTimeoutTime_ECM" SG_ 300 MessageCounter_INVTARGET1 0;
BA_ "GenSigTimeoutTime_EVCU2" SG_ 300 MessageCounter_INVTARGET1 0;
BA_ "GenSigTimeoutTime_TCM" SG_ 300 MessageCounter_INVTARGET1 0;
BA_ "GenSigTimeoutTime_AGSM" SG_ 300 CRC_INVTARGET1 0;
BA_ "GenSigTimeoutTime_ECM" SG_ 300 CRC_INVTARGET1 0;
BA_ "GenSigTimeoutTime_EVCU2" SG_ 300 CRC_INVTARGET1 0;
BA_ "GenSigTimeoutTime_TCM" SG_ 300 CRC_INVTARGET1 0;
BA_ "GenSigStartValue" SG_ 300 AEMD_MinOffset_MCPB 4095;
BA_ "GenSigTimeoutTime_AGSM" SG_ 300 AEMD_MinOffset_MCPB 0;
BA_ "GenSigTimeoutTime_ECM" SG_ 300 AEMD_MinOffset_MCPB 0;
BA_ "GenSigTimeoutTime_EVCU2" SG_ 300 AEMD_MinOffset_MCPB 0;
BA_ "GenSigTimeoutTime_MCPA" SG_ 300 AEMD_MinOffset_MCPB 0;
BA_ "GenSigTimeoutTime_SGCP" SG_ 300 AEMD_MinOffset_MCPB 0;
BA_ "GenSigTimeoutTime_TCM" SG_ 300 AEMD_MinOffset_MCPB 0;
BA_ "GenSigStartValue" SG_ 300 AEMD_MinOffset_MCPA 4095;
BA_ "GenSigTimeoutTime_AGSM" SG_ 300 AEMD_MinOffset_MCPA 0;
BA_ "GenSigTimeoutTime_ECM" SG_ 300 AEMD_MinOffset_MCPA 0;
BA_ "GenSigTimeoutTime_EVCU2" SG_ 300 AEMD_MinOffset_MCPA 0;
BA_ "GenSigTimeoutTime_MCPB" SG_ 300 AEMD_MinOffset_MCPA 0;
BA_ "GenSigTimeoutTime_SGCP" SG_ 300 AEMD_MinOffset_MCPA 0;
BA_ "GenSigTimeoutTime_TCM" SG_ 300 AEMD_MinOffset_MCPA 0;
BA_ "GenSigTimeoutTime_AGSM" SG_ 300 AEMD_MaxOffset_MCPB 0;
BA_ "GenSigTimeoutTime_ECM" SG_ 300 AEMD_MaxOffset_MCPB 0;
BA_ "GenSigTimeoutTime_EVCU2" SG_ 300 AEMD_MaxOffset_MCPB 0;
BA_ "GenSigTimeoutTime_MCPA" SG_ 300 AEMD_MaxOffset_MCPB 0;
BA_ "GenSigTimeoutTime_SGCP" SG_ 300 AEMD_MaxOffset_MCPB 0;
BA_ "GenSigTimeoutTime_TCM" SG_ 300 AEMD_MaxOffset_MCPB 0;
BA_ "GenSigTimeoutTime_AGSM" SG_ 300 AEMD_MaxOffset_MCPA 0;
BA_ "GenSigTimeoutTime_ECM" SG_ 300 AEMD_MaxOffset_MCPA 0;
BA_ "GenSigTimeoutTime_EVCU2" SG_ 300 AEMD_MaxOffset_MCPA 0;
BA_ "GenSigTimeoutTime_MCPB" SG_ 300 AEMD_MaxOffset_MCPA 0;
BA_ "GenSigTimeoutTime_SGCP" SG_ 300 AEMD_MaxOffset_MCPA 0;
BA_ "GenSigTimeoutTime_TCM" SG_ 300 AEMD_MaxOffset_MCPA 0;
BA_ "GenSigTimeoutTime_AGSM" SG_ 300 AEMD_Sclr_Gn_MCPB 0;
BA_ "GenSigTimeoutTime_ECM" SG_ 300 AEMD_Sclr_Gn_MCPB 0;
BA_ "GenSigTimeoutTime_EVCU2" SG_ 300 AEMD_Sclr_Gn_MCPB 0;
BA_ "GenSigTimeoutTime_MCPA" SG_ 300 AEMD_Sclr_Gn_MCPB 0;
BA_ "GenSigTimeoutTime_SGCP" SG_ 300 AEMD_Sclr_Gn_MCPB 0;
BA_ "GenSigTimeoutTime_TCM" SG_ 300 AEMD_Sclr_Gn_MCPB 0;
BA_ "GenSigTimeoutTime_AGSM" SG_ 300 AEMD_Sclr_Gn_MCPA 0;
BA_ "GenSigTimeoutTime_ECM" SG_ 300 AEMD_Sclr_Gn_MCPA 0;
BA_ "GenSigTimeoutTime_EVCU2" SG_ 300 AEMD_Sclr_Gn_MCPA 0;
BA_ "GenSigTimeoutTime_MCPB" SG_ 300 AEMD_Sclr_Gn_MCPA 0;
BA_ "GenSigTimeoutTime_SGCP" SG_ 300 AEMD_Sclr_Gn_MCPA 0;
BA_ "GenSigTimeoutTime_TCM" SG_ 300 AEMD_Sclr_Gn_MCPA 0;
BA_ "GenSigTimeoutTime_AGSM" SG_ 300 AEMD_Cutoff_FreqHigh_MCPB 0;
BA_ "GenSigTimeoutTime_ECM" SG_ 300 AEMD_Cutoff_FreqHigh_MCPB 0;
BA_ "GenSigTimeoutTime_EVCU2" SG_ 300 AEMD_Cutoff_FreqHigh_MCPB 0;
BA_ "GenSigTimeoutTime_MCPA" SG_ 300 AEMD_Cutoff_FreqHigh_MCPB 0;
BA_ "GenSigTimeoutTime_SGCP" SG_ 300 AEMD_Cutoff_FreqHigh_MCPB 0;
BA_ "GenSigTimeoutTime_TCM" SG_ 300 AEMD_Cutoff_FreqHigh_MCPB 0;
BA_ "GenSigTimeoutTime_AGSM" SG_ 300 AEMD_Cutoff_FreqHigh_MCPA 0;
BA_ "GenSigTimeoutTime_ECM" SG_ 300 AEMD_Cutoff_FreqHigh_MCPA 0;
BA_ "GenSigTimeoutTime_EVCU2" SG_ 300 AEMD_Cutoff_FreqHigh_MCPA 0;
BA_ "GenSigTimeoutTime_MCPB" SG_ 300 AEMD_Cutoff_FreqHigh_MCPA 0;
BA_ "GenSigTimeoutTime_SGCP" SG_ 300 AEMD_Cutoff_FreqHigh_MCPA 0;
BA_ "GenSigTimeoutTime_TCM" SG_ 300 AEMD_Cutoff_FreqHigh_MCPA 0;
BA_ "GenSigTimeoutTime_AGSM" SG_ 300 Pwr_Electronics_Loop_FlwRate_MCP 0;
BA_ "GenSigTimeoutTime_ECM" SG_ 300 Pwr_Electronics_Loop_FlwRate_MCP 0;
BA_ "GenSigTimeoutTime_EVCU2" SG_ 300 Pwr_Electronics_Loop_FlwRate_MCP 0;
BA_ "GenSigTimeoutTime_MCPB" SG_ 300 Pwr_Electronics_Loop_FlwRate_MCP 0;
BA_ "GenSigTimeoutTime_SGCP" SG_ 300 Pwr_Electronics_Loop_FlwRate_MCP 0;
BA_ "GenSigTimeoutTime_TCM" SG_ 300 Pwr_Electronics_Loop_FlwRate_MCP 0;
BA_ "SystemSignalLongSymbol" SG_ 300 Pwr_Electronics_Loop_FlwRate_MCP "Pwr_Electronics_Loop_FlwRate_MCPA";
BA_ "GenSigTimeoutTime_AGSM" SG_ 300 AEMD_Cutoff_FreqLow_MCPB 0;
BA_ "GenSigTimeoutTime_ECM" SG_ 300 AEMD_Cutoff_FreqLow_MCPB 0;
BA_ "GenSigTimeoutTime_EVCU2" SG_ 300 AEMD_Cutoff_FreqLow_MCPB 0;
BA_ "GenSigTimeoutTime_MCPA" SG_ 300 AEMD_Cutoff_FreqLow_MCPB 0;
BA_ "GenSigTimeoutTime_SGCP" SG_ 300 AEMD_Cutoff_FreqLow_MCPB 0;
BA_ "GenSigTimeoutTime_TCM" SG_ 300 AEMD_Cutoff_FreqLow_MCPB 0;
BA_ "GenSigTimeoutTime_AGSM" SG_ 300 AEMD_Cutoff_FreqLow_MCPA 0;
BA_ "GenSigTimeoutTime_ECM" SG_ 300 AEMD_Cutoff_FreqLow_MCPA 0;
BA_ "GenSigTimeoutTime_EVCU2" SG_ 300 AEMD_Cutoff_FreqLow_MCPA 0;
BA_ "GenSigTimeoutTime_MCPB" SG_ 300 AEMD_Cutoff_FreqLow_MCPA 0;
BA_ "GenSigTimeoutTime_SGCP" SG_ 300 AEMD_Cutoff_FreqLow_MCPA 0;
BA_ "GenSigTimeoutTime_TCM" SG_ 300 AEMD_Cutoff_FreqLow_MCPA 0;
BA_ "GenSigTimeoutTime_AGSM" SG_ 300 Pwr_Electronics_Loop_FlwRat_0000 0;
BA_ "GenSigTimeoutTime_ECM" SG_ 300 Pwr_Electronics_Loop_FlwRat_0000 0;
BA_ "GenSigTimeoutTime_EVCU2" SG_ 300 Pwr_Electronics_Loop_FlwRat_0000 0;
BA_ "GenSigTimeoutTime_MCPA" SG_ 300 Pwr_Electronics_Loop_FlwRat_0000 0;
BA_ "GenSigTimeoutTime_SGCP" SG_ 300 Pwr_Electronics_Loop_FlwRat_0000 0;
BA_ "GenSigTimeoutTime_TCM" SG_ 300 Pwr_Electronics_Loop_FlwRat_0000 0;
BA_ "SystemSignalLongSymbol" SG_ 300 Pwr_Electronics_Loop_FlwRat_0000 "Pwr_Electronics_Loop_FlwRate_MCPB";
BA_ "GenSigStartValue" SG_ 1063 MCPB_Temp 40;
BA_ "GenSigTimeoutTime_AGSM" SG_ 1063 MCPB_Temp 0;
BA_ "GenSigTimeoutTime_ECM" SG_ 1063 MCPB_Temp 0;
BA_ "GenSigTimeoutTime_MCPA" SG_ 1063 MCPB_Temp 0;
BA_ "GenSigTimeoutTime_MCPB" SG_ 1063 MCPB_Temp 0;
BA_ "GenSigTimeoutTime_SGCP" SG_ 1063 MCPB_Temp 0;
BA_ "GenSigTimeoutTime_TCM" SG_ 1063 MCPB_Temp 0;
BA_ "GenSigStartValue" SG_ 1063 MCPB_Rotor_Temperature 255;
BA_ "GenSigTimeoutTime_AGSM" SG_ 1063 MCPB_Rotor_Temperature 0;
BA_ "GenSigTimeoutTime_ECM" SG_ 1063 MCPB_Rotor_Temperature 0;
BA_ "GenSigTimeoutTime_MCPA" SG_ 1063 MCPB_Rotor_Temperature 0;
BA_ "GenSigTimeoutTime_MCPB" SG_ 1063 MCPB_Rotor_Temperature 0;
BA_ "GenSigTimeoutTime_SGCP" SG_ 1063 MCPB_Rotor_Temperature 0;
BA_ "GenSigTimeoutTime_TCM" SG_ 1063 MCPB_Rotor_Temperature 0;
BA_ "GenSigStartValue" SG_ 1063 MCPB_Inverter_Temp 40;
BA_ "GenSigTimeoutTime_AGSM" SG_ 1063 MCPB_Inverter_Temp 0;
BA_ "GenSigTimeoutTime_ECM" SG_ 1063 MCPB_Inverter_Temp 0;
BA_ "GenSigTimeoutTime_MCPA" SG_ 1063 MCPB_Inverter_Temp 0;
BA_ "GenSigTimeoutTime_MCPB" SG_ 1063 MCPB_Inverter_Temp 0;
BA_ "GenSigTimeoutTime_SGCP" SG_ 1063 MCPB_Inverter_Temp 0;
BA_ "GenSigTimeoutTime_TCM" SG_ 1063 MCPB_Inverter_Temp 0;
BA_ "GenSigStartValue" SG_ 1063 MCPB_Control_Board_Temperature 255;
BA_ "GenSigTimeoutTime_AGSM" SG_ 1063 MCPB_Control_Board_Temperature 0;
BA_ "GenSigTimeoutTime_ECM" SG_ 1063 MCPB_Control_Board_Temperature 0;
BA_ "GenSigTimeoutTime_MCPA" SG_ 1063 MCPB_Control_Board_Temperature 0;
BA_ "GenSigTimeoutTime_MCPB" SG_ 1063 MCPB_Control_Board_Temperature 0;
BA_ "GenSigTimeoutTime_SGCP" SG_ 1063 MCPB_Control_Board_Temperature 0;
BA_ "GenSigTimeoutTime_TCM" SG_ 1063 MCPB_Control_Board_Temperature 0;
BA_ "GenSigTimeoutTime_AGSM" SG_ 1063 CLrDiagInfo_MCPB 0;
BA_ "GenSigTimeoutTime_ECM" SG_ 1063 CLrDiagInfo_MCPB 0;
BA_ "GenSigTimeoutTime_MCPA" SG_ 1063 CLrDiagInfo_MCPB 0;
BA_ "GenSigTimeoutTime_MCPB" SG_ 1063 CLrDiagInfo_MCPB 0;
BA_ "GenSigTimeoutTime_SGCP" SG_ 1063 CLrDiagInfo_MCPB 0;
BA_ "GenSigTimeoutTime_TCM" SG_ 1063 CLrDiagInfo_MCPB 0;
BA_ "GenSigTimeoutTime_AGSM" SG_ 1063 MessageCounter_MCPB_DATA2 0;
BA_ "GenSigTimeoutTime_ECM" SG_ 1063 MessageCounter_MCPB_DATA2 0;
BA_ "GenSigTimeoutTime_MCPA" SG_ 1063 MessageCounter_MCPB_DATA2 0;
BA_ "GenSigTimeoutTime_MCPB" SG_ 1063 MessageCounter_MCPB_DATA2 0;
BA_ "GenSigTimeoutTime_SGCP" SG_ 1063 MessageCounter_MCPB_DATA2 0;
BA_ "GenSigTimeoutTime_TCM" SG_ 1063 MessageCounter_MCPB_DATA2 0;
BA_ "GenSigTimeoutTime_AGSM" SG_ 1063 CRC_MCPB_DATA2 0;
BA_ "GenSigTimeoutTime_ECM" SG_ 1063 CRC_MCPB_DATA2 0;
BA_ "GenSigTimeoutTime_MCPA" SG_ 1063 CRC_MCPB_DATA2 0;
BA_ "GenSigTimeoutTime_MCPB" SG_ 1063 CRC_MCPB_DATA2 0;
BA_ "GenSigTimeoutTime_SGCP" SG_ 1063 CRC_MCPB_DATA2 0;
BA_ "GenSigTimeoutTime_TCM" SG_ 1063 CRC_MCPB_DATA2 0;
BA_ "GenSigTimeoutTime_AGSM" SG_ 1063 MCPB_PIM_DC_Side_Busbar_Temp 0;
BA_ "GenSigTimeoutTime_ECM" SG_ 1063 MCPB_PIM_DC_Side_Busbar_Temp 0;
BA_ "GenSigTimeoutTime_MCPA" SG_ 1063 MCPB_PIM_DC_Side_Busbar_Temp 0;
BA_ "GenSigTimeoutTime_MCPB" SG_ 1063 MCPB_PIM_DC_Side_Busbar_Temp 0;
BA_ "GenSigTimeoutTime_SGCP" SG_ 1063 MCPB_PIM_DC_Side_Busbar_Temp 0;
BA_ "GenSigTimeoutTime_TCM" SG_ 1063 MCPB_PIM_DC_Side_Busbar_Temp 0;
BA_ "GenSigTimeoutTime_AGSM" SG_ 1063 MCPB_Service_Lamp_Request_2 0;
BA_ "GenSigTimeoutTime_ECM" SG_ 1063 MCPB_Service_Lamp_Request_2 0;
BA_ "GenSigTimeoutTime_MCPA" SG_ 1063 MCPB_Service_Lamp_Request_2 0;
BA_ "GenSigTimeoutTime_MCPB" SG_ 1063 MCPB_Service_Lamp_Request_2 0;
BA_ "GenSigTimeoutTime_SGCP" SG_ 1063 MCPB_Service_Lamp_Request_2 0;
BA_ "GenSigTimeoutTime_TCM" SG_ 1063 MCPB_Service_Lamp_Request_2 0;
BA_ "GenSigTimeoutTime_AGSM" SG_ 292 MessageCounter_BATT_HV_STATUS1 0;
BA_ "GenSigTimeoutTime_ECM" SG_ 292 MessageCounter_BATT_HV_STATUS1 0;
BA_ "GenSigTimeoutTime_EVCU2" SG_ 292 MessageCounter_BATT_HV_STATUS1 0;
BA_ "GenSigTimeoutTime_TCM" SG_ 292 MessageCounter_BATT_HV_STATUS1 0;
BA_ "GenSigTimeoutTime_AGSM" SG_ 292 CRC_BATT_HV_STATUS1 0;
BA_ "GenSigTimeoutTime_ECM" SG_ 292 CRC_BATT_HV_STATUS1 0;
BA_ "GenSigTimeoutTime_EVCU2" SG_ 292 CRC_BATT_HV_STATUS1 0;
BA_ "GenSigTimeoutTime_TCM" SG_ 292 CRC_BATT_HV_STATUS1 0;
BA_ "GenSigTimeoutTime_AGSM" SG_ 292 BPCM_HV_TractionBusVoltage 0;
BA_ "GenSigTimeoutTime_ECM" SG_ 292 BPCM_HV_TractionBusVoltage 0;
BA_ "GenSigTimeoutTime_EVCU2" SG_ 292 BPCM_HV_TractionBusVoltage 0;
BA_ "GenSigTimeoutTime_TCM" SG_ 292 BPCM_HV_TractionBusVoltage 0;
BA_ "GenSigTimeoutTime_AGSM" SG_ 292 BPCM_HV_Trac_Bus_Sts 0;
BA_ "GenSigTimeoutTime_ECM" SG_ 292 BPCM_HV_Trac_Bus_Sts 0;
BA_ "GenSigTimeoutTime_EVCU2" SG_ 292 BPCM_HV_Trac_Bus_Sts 0;
BA_ "GenSigTimeoutTime_TCM" SG_ 292 BPCM_HV_Trac_Bus_Sts 0;
BA_ "GenSigTimeoutTime_AGSM" SG_ 2654339273 GenericFailSts_FD16_SGCP 0;
BA_ "GenSigTimeoutTime_ECM" SG_ 2654339273 GenericFailSts_FD16_SGCP 0;
BA_ "GenSigTimeoutTime_MCPA" SG_ 2654339273 GenericFailSts_FD16_SGCP 0;
BA_ "GenSigTimeoutTime_MCPB" SG_ 2654339273 GenericFailSts_FD16_SGCP 0;
BA_ "GenSigTimeoutTime_SGCP" SG_ 2654339273 GenericFailSts_FD16_SGCP 0;
BA_ "GenSigTimeoutTime_TCM" SG_ 2654339273 GenericFailSts_FD16_SGCP 0;
BA_ "GenSigTimeoutTime_AGSM" SG_ 2654339273 EOL_FD16_SGCP 0;
BA_ "GenSigTimeoutTime_ECM" SG_ 2654339273 EOL_FD16_SGCP 0;
BA_ "GenSigTimeoutTime_MCPA" SG_ 2654339273 EOL_FD16_SGCP 0;
BA_ "GenSigTimeoutTime_MCPB" SG_ 2654339273 EOL_FD16_SGCP 0;
BA_ "GenSigTimeoutTime_SGCP" SG_ 2654339273 EOL_FD16_SGCP 0;
BA_ "GenSigTimeoutTime_TCM" SG_ 2654339273 EOL_FD16_SGCP 0;
BA_ "GenSigTimeoutTime_AGSM" SG_ 2654339273 CurrentFailSts_FD16_SGCP 0;
BA_ "GenSigTimeoutTime_ECM" SG_ 2654339273 CurrentFailSts_FD16_SGCP 0;
BA_ "GenSigTimeoutTime_MCPA" SG_ 2654339273 CurrentFailSts_FD16_SGCP 0;
BA_ "GenSigTimeoutTime_MCPB" SG_ 2654339273 CurrentFailSts_FD16_SGCP 0;
BA_ "GenSigTimeoutTime_SGCP" SG_ 2654339273 CurrentFailSts_FD16_SGCP 0;
BA_ "GenSigTimeoutTime_TCM" SG_ 2654339273 CurrentFailSts_FD16_SGCP 0;
BA_ "GenSigTimeoutTime_AGSM" SG_ 2654339161 EOL_FD16_MCPB 0;
BA_ "GenSigTimeoutTime_ECM" SG_ 2654339161 EOL_FD16_MCPB 0;
BA_ "GenSigTimeoutTime_MCPA" SG_ 2654339161 EOL_FD16_MCPB 0;
BA_ "GenSigTimeoutTime_MCPB" SG_ 2654339161 EOL_FD16_MCPB 0;
BA_ "GenSigTimeoutTime_SGCP" SG_ 2654339161 EOL_FD16_MCPB 0;
BA_ "GenSigTimeoutTime_TCM" SG_ 2654339161 EOL_FD16_MCPB 0;
BA_ "GenSigTimeoutTime_AGSM" SG_ 2654339161 GenericFailSts_FD16_MCPB 0;
BA_ "GenSigTimeoutTime_ECM" SG_ 2654339161 GenericFailSts_FD16_MCPB 0;
BA_ "GenSigTimeoutTime_MCPA" SG_ 2654339161 GenericFailSts_FD16_MCPB 0;
BA_ "GenSigTimeoutTime_MCPB" SG_ 2654339161 GenericFailSts_FD16_MCPB 0;
BA_ "GenSigTimeoutTime_SGCP" SG_ 2654339161 GenericFailSts_FD16_MCPB 0;
BA_ "GenSigTimeoutTime_TCM" SG_ 2654339161 GenericFailSts_FD16_MCPB 0;
BA_ "GenSigTimeoutTime_AGSM" SG_ 2654339161 CurrentFailSts_FD16_MCPB 0;
BA_ "GenSigTimeoutTime_ECM" SG_ 2654339161 CurrentFailSts_FD16_MCPB 0;
BA_ "GenSigTimeoutTime_MCPA" SG_ 2654339161 CurrentFailSts_FD16_MCPB 0;
BA_ "GenSigTimeoutTime_MCPB" SG_ 2654339161 CurrentFailSts_FD16_MCPB 0;
BA_ "GenSigTimeoutTime_SGCP" SG_ 2654339161 CurrentFailSts_FD16_MCPB 0;
BA_ "GenSigTimeoutTime_TCM" SG_ 2654339161 CurrentFailSts_FD16_MCPB 0;
BA_ "GenSigTimeoutTime_AGSM" SG_ 2654339160 EOL_FD16_MCPA 0;
BA_ "GenSigTimeoutTime_ECM" SG_ 2654339160 EOL_FD16_MCPA 0;
BA_ "GenSigTimeoutTime_MCPA" SG_ 2654339160 EOL_FD16_MCPA 0;
BA_ "GenSigTimeoutTime_MCPB" SG_ 2654339160 EOL_FD16_MCPA 0;
BA_ "GenSigTimeoutTime_SGCP" SG_ 2654339160 EOL_FD16_MCPA 0;
BA_ "GenSigTimeoutTime_TCM" SG_ 2654339160 EOL_FD16_MCPA 0;
BA_ "GenSigTimeoutTime_AGSM" SG_ 2654339160 GenericFailSts_FD16_MCPA 0;
BA_ "GenSigTimeoutTime_ECM" SG_ 2654339160 GenericFailSts_FD16_MCPA 0;
BA_ "GenSigTimeoutTime_MCPA" SG_ 2654339160 GenericFailSts_FD16_MCPA 0;
BA_ "GenSigTimeoutTime_MCPB" SG_ 2654339160 GenericFailSts_FD16_MCPA 0;
BA_ "GenSigTimeoutTime_SGCP" SG_ 2654339160 GenericFailSts_FD16_MCPA 0;
BA_ "GenSigTimeoutTime_TCM" SG_ 2654339160 GenericFailSts_FD16_MCPA 0;
BA_ "GenSigTimeoutTime_AGSM" SG_ 2654339160 CurrentFailSts_FD16_MCPA 0;
BA_ "GenSigTimeoutTime_ECM" SG_ 2654339160 CurrentFailSts_FD16_MCPA 0;
BA_ "GenSigTimeoutTime_MCPA" SG_ 2654339160 CurrentFailSts_FD16_MCPA 0;
BA_ "GenSigTimeoutTime_MCPB" SG_ 2654339160 CurrentFailSts_FD16_MCPA 0;
BA_ "GenSigTimeoutTime_SGCP" SG_ 2654339160 CurrentFailSts_FD16_MCPA 0;
BA_ "GenSigTimeoutTime_TCM" SG_ 2654339160 CurrentFailSts_FD16_MCPA 0;
BA_ "GenSigTimeoutTime_AGSM" SG_ 2564682364 N_PDU_18DDF27C 0;
BA_ "GenSigTimeoutTime_ECM" SG_ 2564682364 N_PDU_18DDF27C 0;
BA_ "GenSigTimeoutTime_EVCU2" SG_ 2564682364 N_PDU_18DDF27C 0;
BA_ "GenSigTimeoutTime_MCPA" SG_ 2564682364 N_PDU_18DDF27C 0;
BA_ "GenSigTimeoutTime_MCPB" SG_ 2564682364 N_PDU_18DDF27C 0;
BA_ "GenSigTimeoutTime_SGCP" SG_ 2564682364 N_PDU_18DDF27C 0;
BA_ "GenSigTimeoutTime_AGSM" SG_ 2564485756 N_PDU_18DAF27C 0;
BA_ "GenSigTimeoutTime_ECM" SG_ 2564485756 N_PDU_18DAF27C 0;
BA_ "GenSigTimeoutTime_EVCU2" SG_ 2564485756 N_PDU_18DAF27C 0;
BA_ "GenSigTimeoutTime_MCPA" SG_ 2564485756 N_PDU_18DAF27C 0;
BA_ "GenSigTimeoutTime_MCPB" SG_ 2564485756 N_PDU_18DAF27C 0;
BA_ "GenSigTimeoutTime_SGCP" SG_ 2564485756 N_PDU_18DAF27C 0;
BA_ "GenSigTimeoutTime_AGSM" SG_ 2564455666 N_PDU_18DA7CF2 0;
BA_ "GenSigTimeoutTime_ECM" SG_ 2564455666 N_PDU_18DA7CF2 0;
BA_ "GenSigTimeoutTime_EVCU2" SG_ 2564455666 N_PDU_18DA7CF2 0;
BA_ "GenSigTimeoutTime_MCPA" SG_ 2564455666 N_PDU_18DA7CF2 0;
BA_ "GenSigTimeoutTime_MCPB" SG_ 2564455666 N_PDU_18DA7CF2 0;
BA_ "GenSigTimeoutTime_SGCP" SG_ 2564455666 N_PDU_18DA7CF2 0;
BA_ "GenSigTimeoutTime_AGSM" SG_ 243 SGCP_Torque_Achieved_V 0;
BA_ "GenSigTimeoutTime_ECM" SG_ 243 SGCP_Torque_Achieved_V 0;
BA_ "GenSigTimeoutTime_MCPA" SG_ 243 SGCP_Torque_Achieved_V 0;
BA_ "GenSigTimeoutTime_MCPB" SG_ 243 SGCP_Torque_Achieved_V 0;
BA_ "GenSigTimeoutTime_SGCP" SG_ 243 SGCP_Torque_Achieved_V 0;
BA_ "GenSigTimeoutTime_TCM" SG_ 243 SGCP_Torque_Achieved_V 0;
BA_ "GenSigStartValue" SG_ 243 SGCP_Torque_Achieved 4096;
BA_ "GenSigTimeoutTime_AGSM" SG_ 243 SGCP_Torque_Achieved 0;
BA_ "GenSigTimeoutTime_ECM" SG_ 243 SGCP_Torque_Achieved 0;
BA_ "GenSigTimeoutTime_MCPA" SG_ 243 SGCP_Torque_Achieved 0;
BA_ "GenSigTimeoutTime_MCPB" SG_ 243 SGCP_Torque_Achieved 0;
BA_ "GenSigTimeoutTime_SGCP" SG_ 243 SGCP_Torque_Achieved 0;
BA_ "GenSigTimeoutTime_TCM" SG_ 243 SGCP_Torque_Achieved 0;
BA_ "GenSigTimeoutTime_AGSM" SG_ 243 SGCP_TorqAchieved_AEMD_V 0;
BA_ "GenSigTimeoutTime_ECM" SG_ 243 SGCP_TorqAchieved_AEMD_V 0;
BA_ "GenSigTimeoutTime_MCPA" SG_ 243 SGCP_TorqAchieved_AEMD_V 0;
BA_ "GenSigTimeoutTime_MCPB" SG_ 243 SGCP_TorqAchieved_AEMD_V 0;
BA_ "GenSigTimeoutTime_SGCP" SG_ 243 SGCP_TorqAchieved_AEMD_V 0;
BA_ "GenSigTimeoutTime_TCM" SG_ 243 SGCP_TorqAchieved_AEMD_V 0;
BA_ "GenSigStartValue" SG_ 243 SGCP_TorqAchieved_AEMD 4096;
BA_ "GenSigTimeoutTime_AGSM" SG_ 243 SGCP_TorqAchieved_AEMD 0;
BA_ "GenSigTimeoutTime_ECM" SG_ 243 SGCP_TorqAchieved_AEMD 0;
BA_ "GenSigTimeoutTime_MCPA" SG_ 243 SGCP_TorqAchieved_AEMD 0;
BA_ "GenSigTimeoutTime_MCPB" SG_ 243 SGCP_TorqAchieved_AEMD 0;
BA_ "GenSigTimeoutTime_SGCP" SG_ 243 SGCP_TorqAchieved_AEMD 0;
BA_ "GenSigTimeoutTime_TCM" SG_ 243 SGCP_TorqAchieved_AEMD 0;
BA_ "GenSigTimeoutTime_AGSM" SG_ 243 SGCP_SPT_Stat 0;
BA_ "GenSigTimeoutTime_ECM" SG_ 243 SGCP_SPT_Stat 0;
BA_ "GenSigTimeoutTime_MCPA" SG_ 243 SGCP_SPT_Stat 0;
BA_ "GenSigTimeoutTime_MCPB" SG_ 243 SGCP_SPT_Stat 0;
BA_ "GenSigTimeoutTime_SGCP" SG_ 243 SGCP_SPT_Stat 0;
BA_ "GenSigTimeoutTime_TCM" SG_ 243 SGCP_SPT_Stat 0;
BA_ "GenSigTimeoutTime_AGSM" SG_ 243 SGCP_Spd_Lim 0;
BA_ "GenSigTimeoutTime_ECM" SG_ 243 SGCP_Spd_Lim 0;
BA_ "GenSigTimeoutTime_MCPA" SG_ 243 SGCP_Spd_Lim 0;
BA_ "GenSigTimeoutTime_MCPB" SG_ 243 SGCP_Spd_Lim 0;
BA_ "GenSigTimeoutTime_SGCP" SG_ 243 SGCP_Spd_Lim 0;
BA_ "GenSigTimeoutTime_TCM" SG_ 243 SGCP_Spd_Lim 0;
BA_ "GenSigTimeoutTime_AGSM" SG_ 243 SGCP_RPM_V 0;
BA_ "GenSigTimeoutTime_ECM" SG_ 243 SGCP_RPM_V 0;
BA_ "GenSigTimeoutTime_MCPA" SG_ 243 SGCP_RPM_V 0;
BA_ "GenSigTimeoutTime_MCPB" SG_ 243 SGCP_RPM_V 0;
BA_ "GenSigTimeoutTime_SGCP" SG_ 243 SGCP_RPM_V 0;
BA_ "GenSigTimeoutTime_TCM" SG_ 243 SGCP_RPM_V 0;
BA_ "GenSigStartValue" SG_ 243 SGCP_RPM 32768;
BA_ "GenSigTimeoutTime_AGSM" SG_ 243 SGCP_RPM 0;
BA_ "GenSigTimeoutTime_ECM" SG_ 243 SGCP_RPM 0;
BA_ "GenSigTimeoutTime_MCPA" SG_ 243 SGCP_RPM 0;
BA_ "GenSigTimeoutTime_MCPB" SG_ 243 SGCP_RPM 0;
BA_ "GenSigTimeoutTime_SGCP" SG_ 243 SGCP_RPM 0;
BA_ "GenSigTimeoutTime_TCM" SG_ 243 SGCP_RPM 0;
BA_ "GenSigTimeoutTime_MCPA" SG_ 243 SGCP_MtrMinCpbltyTrq 0;
BA_ "GenSigTimeoutTime_MCPB" SG_ 243 SGCP_MtrMinCpbltyTrq 0;
BA_ "GenSigTimeoutTime_SGCP" SG_ 243 SGCP_MtrMinCpbltyTrq 0;
BA_ "GenSigTimeoutTime_TCM" SG_ 243 SGCP_MtrMinCpbltyTrq 0;
BA_ "GenSigStartValue" SG_ 243 SGCP_MtrMinCpbltyTrq 4096;
BA_ "GenSigTimeoutTime_AGSM" SG_ 243 SGCP_MtrMinCpbltyTrq 0;
BA_ "GenSigTimeoutTime_ECM" SG_ 243 SGCP_MtrMinCpbltyTrq 0;
BA_ "GenSigStartValue" SG_ 243 SGCP_MtrMaxCpbltyTrq 4096;
BA_ "GenSigTimeoutTime_AGSM" SG_ 243 SGCP_MtrMaxCpbltyTrq 0;
BA_ "GenSigTimeoutTime_ECM" SG_ 243 SGCP_MtrMaxCpbltyTrq 0;
BA_ "GenSigTimeoutTime_MCPA" SG_ 243 SGCP_MtrMaxCpbltyTrq 0;
BA_ "GenSigTimeoutTime_MCPB" SG_ 243 SGCP_MtrMaxCpbltyTrq 0;
BA_ "GenSigTimeoutTime_SGCP" SG_ 243 SGCP_MtrMaxCpbltyTrq 0;
BA_ "GenSigTimeoutTime_TCM" SG_ 243 SGCP_MtrMaxCpbltyTrq 0;
BA_ "GenSigTimeoutTime_AGSM" SG_ 243 SGCP_MtrIndex 0;
BA_ "GenSigTimeoutTime_ECM" SG_ 243 SGCP_MtrIndex 0;
BA_ "GenSigTimeoutTime_MCPA" SG_ 243 SGCP_MtrIndex 0;
BA_ "GenSigTimeoutTime_MCPB" SG_ 243 SGCP_MtrIndex 0;
BA_ "GenSigTimeoutTime_SGCP" SG_ 243 SGCP_MtrIndex 0;
BA_ "GenSigTimeoutTime_TCM" SG_ 243 SGCP_MtrIndex 0;
BA_ "GenSigStartValue" SG_ 243 SGCP_MinTorq 4096;
BA_ "GenSigTimeoutTime_AGSM" SG_ 243 SGCP_MinTorq 0;
BA_ "GenSigTimeoutTime_ECM" SG_ 243 SGCP_MinTorq 0;
BA_ "GenSigTimeoutTime_MCPA" SG_ 243 SGCP_MinTorq 0;
BA_ "GenSigTimeoutTime_MCPB" SG_ 243 SGCP_MinTorq 0;
BA_ "GenSigTimeoutTime_SGCP" SG_ 243 SGCP_MinTorq 0;
BA_ "GenSigTimeoutTime_TCM" SG_ 243 SGCP_MinTorq 0;
BA_ "GenSigStartValue" SG_ 243 SGCP_MaxTorq 4096;
BA_ "GenSigTimeoutTime_AGSM" SG_ 243 SGCP_MaxTorq 0;
BA_ "GenSigTimeoutTime_ECM" SG_ 243 SGCP_MaxTorq 0;
BA_ "GenSigTimeoutTime_MCPA" SG_ 243 SGCP_MaxTorq 0;
BA_ "GenSigTimeoutTime_MCPB" SG_ 243 SGCP_MaxTorq 0;
BA_ "GenSigTimeoutTime_SGCP" SG_ 243 SGCP_MaxTorq 0;
BA_ "GenSigTimeoutTime_TCM" SG_ 243 SGCP_MaxTorq 0;
BA_ "GenSigTimeoutTime_AGSM" SG_ 243 SGCP_Invrtr_State 0;
BA_ "GenSigTimeoutTime_ECM" SG_ 243 SGCP_Invrtr_State 0;
BA_ "GenSigTimeoutTime_MCPA" SG_ 243 SGCP_Invrtr_State 0;
BA_ "GenSigTimeoutTime_MCPB" SG_ 243 SGCP_Invrtr_State 0;
BA_ "GenSigTimeoutTime_SGCP" SG_ 243 SGCP_Invrtr_State 0;
BA_ "GenSigTimeoutTime_TCM" SG_ 243 SGCP_Invrtr_State 0;
BA_ "GenSigTimeoutTime_AGSM" SG_ 243 SGCP_InterlockSts 0;
BA_ "GenSigTimeoutTime_ECM" SG_ 243 SGCP_InterlockSts 0;
BA_ "GenSigTimeoutTime_MCPA" SG_ 243 SGCP_InterlockSts 0;
BA_ "GenSigTimeoutTime_MCPB" SG_ 243 SGCP_InterlockSts 0;
BA_ "GenSigTimeoutTime_SGCP" SG_ 243 SGCP_InterlockSts 0;
BA_ "GenSigTimeoutTime_TCM" SG_ 243 SGCP_InterlockSts 0;
BA_ "GenSigTimeoutTime_AGSM" SG_ 243 SGCP_HV_CnctrOpn_Req 0;
BA_ "GenSigTimeoutTime_ECM" SG_ 243 SGCP_HV_CnctrOpn_Req 0;
BA_ "GenSigTimeoutTime_MCPA" SG_ 243 SGCP_HV_CnctrOpn_Req 0;
BA_ "GenSigTimeoutTime_MCPB" SG_ 243 SGCP_HV_CnctrOpn_Req 0;
BA_ "GenSigTimeoutTime_SGCP" SG_ 243 SGCP_HV_CnctrOpn_Req 0;
BA_ "GenSigTimeoutTime_TCM" SG_ 243 SGCP_HV_CnctrOpn_Req 0;
BA_ "GenSigTimeoutTime_AGSM" SG_ 243 SGCP_Dschrge_Status 0;
BA_ "GenSigTimeoutTime_ECM" SG_ 243 SGCP_Dschrge_Status 0;
BA_ "GenSigTimeoutTime_MCPA" SG_ 243 SGCP_Dschrge_Status 0;
BA_ "GenSigTimeoutTime_MCPB" SG_ 243 SGCP_Dschrge_Status 0;
BA_ "GenSigTimeoutTime_SGCP" SG_ 243 SGCP_Dschrge_Status 0;
BA_ "GenSigTimeoutTime_TCM" SG_ 243 SGCP_Dschrge_Status 0;
BA_ "GenSigTimeoutTime_AGSM" SG_ 243 SGCP_DeratingFactor 0;
BA_ "GenSigTimeoutTime_ECM" SG_ 243 SGCP_DeratingFactor 0;
BA_ "GenSigTimeoutTime_MCPA" SG_ 243 SGCP_DeratingFactor 0;
BA_ "GenSigTimeoutTime_MCPB" SG_ 243 SGCP_DeratingFactor 0;
BA_ "GenSigTimeoutTime_SGCP" SG_ 243 SGCP_DeratingFactor 0;
BA_ "GenSigTimeoutTime_TCM" SG_ 243 SGCP_DeratingFactor 0;
BA_ "GenSigTimeoutTime_AGSM" SG_ 243 SGCP_DerateReason 0;
BA_ "GenSigTimeoutTime_ECM" SG_ 243 SGCP_DerateReason 0;
BA_ "GenSigTimeoutTime_MCPA" SG_ 243 SGCP_DerateReason 0;
BA_ "GenSigTimeoutTime_MCPB" SG_ 243 SGCP_DerateReason 0;
BA_ "GenSigTimeoutTime_SGCP" SG_ 243 SGCP_DerateReason 0;
BA_ "GenSigTimeoutTime_TCM" SG_ 243 SGCP_DerateReason 0;
BA_ "GenSigTimeoutTime_AGSM" SG_ 243 SGCP_DC_Voltage 0;
BA_ "GenSigTimeoutTime_ECM" SG_ 243 SGCP_DC_Voltage 0;
BA_ "GenSigTimeoutTime_MCPA" SG_ 243 SGCP_DC_Voltage 0;
BA_ "GenSigTimeoutTime_MCPB" SG_ 243 SGCP_DC_Voltage 0;
BA_ "GenSigTimeoutTime_SGCP" SG_ 243 SGCP_DC_Voltage 0;
BA_ "GenSigTimeoutTime_TCM" SG_ 243 SGCP_DC_Voltage 0;
BA_ "GenSigTimeoutTime_AGSM" SG_ 243 SGCP_DC_Volt_V 0;
BA_ "GenSigTimeoutTime_ECM" SG_ 243 SGCP_DC_Volt_V 0;
BA_ "GenSigTimeoutTime_MCPA" SG_ 243 SGCP_DC_Volt_V 0;
BA_ "GenSigTimeoutTime_MCPB" SG_ 243 SGCP_DC_Volt_V 0;
BA_ "GenSigTimeoutTime_SGCP" SG_ 243 SGCP_DC_Volt_V 0;
BA_ "GenSigTimeoutTime_TCM" SG_ 243 SGCP_DC_Volt_V 0;
BA_ "GenSigTimeoutTime_AGSM" SG_ 243 SGCP_DC_Current_V 0;
BA_ "GenSigTimeoutTime_ECM" SG_ 243 SGCP_DC_Current_V 0;
BA_ "GenSigTimeoutTime_MCPA" SG_ 243 SGCP_DC_Current_V 0;
BA_ "GenSigTimeoutTime_MCPB" SG_ 243 SGCP_DC_Current_V 0;
BA_ "GenSigTimeoutTime_SGCP" SG_ 243 SGCP_DC_Current_V 0;
BA_ "GenSigTimeoutTime_TCM" SG_ 243 SGCP_DC_Current_V 0;
BA_ "GenSigStartValue" SG_ 243 SGCP_DC_Current 16384;
BA_ "GenSigTimeoutTime_AGSM" SG_ 243 SGCP_DC_Current 0;
BA_ "GenSigTimeoutTime_ECM" SG_ 243 SGCP_DC_Current 0;
BA_ "GenSigTimeoutTime_MCPA" SG_ 243 SGCP_DC_Current 0;
BA_ "GenSigTimeoutTime_MCPB" SG_ 243 SGCP_DC_Current 0;
BA_ "GenSigTimeoutTime_SGCP" SG_ 243 SGCP_DC_Current 0;
BA_ "GenSigTimeoutTime_TCM" SG_ 243 SGCP_DC_Current 0;
BA_ "GenSigTimeoutTime_AGSM" SG_ 243 SGCP_CpbltySpdDivVolt 0;
BA_ "GenSigTimeoutTime_ECM" SG_ 243 SGCP_CpbltySpdDivVolt 0;
BA_ "GenSigTimeoutTime_MCPA" SG_ 243 SGCP_CpbltySpdDivVolt 0;
BA_ "GenSigTimeoutTime_MCPB" SG_ 243 SGCP_CpbltySpdDivVolt 0;
BA_ "GenSigTimeoutTime_SGCP" SG_ 243 SGCP_CpbltySpdDivVolt 0;
BA_ "GenSigTimeoutTime_TCM" SG_ 243 SGCP_CpbltySpdDivVolt 0;
BA_ "GenSigTimeoutTime_AGSM" SG_ 243 SGCP_Comm_Fail_CAN 0;
BA_ "GenSigTimeoutTime_ECM" SG_ 243 SGCP_Comm_Fail_CAN 0;
BA_ "GenSigTimeoutTime_MCPA" SG_ 243 SGCP_Comm_Fail_CAN 0;
BA_ "GenSigTimeoutTime_MCPB" SG_ 243 SGCP_Comm_Fail_CAN 0;
BA_ "GenSigTimeoutTime_SGCP" SG_ 243 SGCP_Comm_Fail_CAN 0;
BA_ "GenSigTimeoutTime_TCM" SG_ 243 SGCP_Comm_Fail_CAN 0;
BA_ "GenSigTimeoutTime_AGSM" SG_ 243 SGCP_AccelRawV 0;
BA_ "GenSigTimeoutTime_ECM" SG_ 243 SGCP_AccelRawV 0;
BA_ "GenSigTimeoutTime_MCPA" SG_ 243 SGCP_AccelRawV 0;
BA_ "GenSigTimeoutTime_MCPB" SG_ 243 SGCP_AccelRawV 0;
BA_ "GenSigTimeoutTime_SGCP" SG_ 243 SGCP_AccelRawV 0;
BA_ "GenSigTimeoutTime_TCM" SG_ 243 SGCP_AccelRawV 0;
BA_ "GenSigTimeoutTime_AGSM" SG_ 243 SGCP_AccelRaw 0;
BA_ "GenSigTimeoutTime_ECM" SG_ 243 SGCP_AccelRaw 0;
BA_ "GenSigTimeoutTime_MCPA" SG_ 243 SGCP_AccelRaw 0;
BA_ "GenSigTimeoutTime_MCPB" SG_ 243 SGCP_AccelRaw 0;
BA_ "GenSigTimeoutTime_SGCP" SG_ 243 SGCP_AccelRaw 0;
BA_ "GenSigTimeoutTime_TCM" SG_ 243 SGCP_AccelRaw 0;
BA_ "GenSigTimeoutTime_AGSM" SG_ 243 SGCP_6SO_Status 0;
BA_ "GenSigTimeoutTime_ECM" SG_ 243 SGCP_6SO_Status 0;
BA_ "GenSigTimeoutTime_MCPA" SG_ 243 SGCP_6SO_Status 0;
BA_ "GenSigTimeoutTime_MCPB" SG_ 243 SGCP_6SO_Status 0;
BA_ "GenSigTimeoutTime_SGCP" SG_ 243 SGCP_6SO_Status 0;
BA_ "GenSigTimeoutTime_TCM" SG_ 243 SGCP_6SO_Status 0;
BA_ "GenSigTimeoutTime_AGSM" SG_ 243 SGCP_3PS_Pos 0;
BA_ "GenSigTimeoutTime_ECM" SG_ 243 SGCP_3PS_Pos 0;
BA_ "GenSigTimeoutTime_MCPA" SG_ 243 SGCP_3PS_Pos 0;
BA_ "GenSigTimeoutTime_MCPB" SG_ 243 SGCP_3PS_Pos 0;
BA_ "GenSigTimeoutTime_SGCP" SG_ 243 SGCP_3PS_Pos 0;
BA_ "GenSigTimeoutTime_TCM" SG_ 243 SGCP_3PS_Pos 0;
BA_ "GenSigTimeoutTime_AGSM" SG_ 243 MC_SGCP_PWT1 0;
BA_ "GenSigTimeoutTime_ECM" SG_ 243 MC_SGCP_PWT1 0;
BA_ "GenSigTimeoutTime_MCPA" SG_ 243 MC_SGCP_PWT1 0;
BA_ "GenSigTimeoutTime_MCPB" SG_ 243 MC_SGCP_PWT1 0;
BA_ "GenSigTimeoutTime_SGCP" SG_ 243 MC_SGCP_PWT1 0;
BA_ "GenSigTimeoutTime_TCM" SG_ 243 MC_SGCP_PWT1 0;
BA_ "GenSigTimeoutTime_AGSM" SG_ 243 CRC_SGCP_PWT1 0;
BA_ "GenSigTimeoutTime_ECM" SG_ 243 CRC_SGCP_PWT1 0;
BA_ "GenSigTimeoutTime_MCPA" SG_ 243 CRC_SGCP_PWT1 0;
BA_ "GenSigTimeoutTime_MCPB" SG_ 243 CRC_SGCP_PWT1 0;
BA_ "GenSigTimeoutTime_SGCP" SG_ 243 CRC_SGCP_PWT1 0;
BA_ "GenSigTimeoutTime_TCM" SG_ 243 CRC_SGCP_PWT1 0;
VAL_ 262 TxAC_EMCC_rq_W 0 "False" 1 "True" ;
VAL_ 262 TRANS_CLU_SLIP_MODE_W 0 "NORMAL" 1 "MDS_RQ" 2 "IDFSO_RQ" 3 "AC_EN_DIS_RQ" 4 "IDFSO_ACTIVE" 5 "MDS_IDFSO_ACT" 7 "SNA" ;
VAL_ 262 PowertrainPrplsnActv 0 "Off" 1 "Active" ;
VAL_ 262 LV12PwrFreeRq_W 0 "Level 1 or 2 Power free Mode NOT active" 1 "Level 1 or 2 Power free Mode Active" ;
VAL_ 262 KickDownRequest_W 0 "No_kd_request" 1 "Kd_request" ;
VAL_ 262 IntakeAirTemperature_W 255 "SNA" ;
VAL_ 262 GasPedalPositionFailSts_W 0 "Fail_not_present" 1 "Fail_present" ;
VAL_ 262 GasPedalPosition_W 255 "SNA" ;
VAL_ 262 ESS_ENG_ST_W 1 "ENS Stopped / ENS_STOPPED" 2 "ENS Request Start / ENS_RQ_ST" 3 "ENS Running / ENS_RUN" 4 "ENS Stop Pending / ENS_STOP_PEND" 5 "ENS Start protection / ENS_ST_PRTCT" 6 "ENS Start inhibit / ENS_ST_INH" 7 "ENS disabled / ENS_DSBL" 8 "ENS_IHB_LATCH" 9 "ENS Starting / ENS_Starting" 15 "SNA" ;
VAL_ 262 EngTrq_Enbl_Rq_TCM_W 0 "Not_Active" 1 "Active" ;
VAL_ 262 EngineSts_W 0 "Engine_Off" 1 "Engine_Cranking" 2 "Engine_On" 3 "SNA" ;
VAL_ 262 EngineSpeedFailSts_W 0 "Fail_not_present" 1 "Fail_present" ;
VAL_ 262 EngineSpeed_W 16383 "SNA" ;
VAL_ 262 EngineIdleRefSpeed 4095 "SNA" ;
VAL_ 262 EngineFrictionTorque_W 511 "SNA" ;
VAL_ 262 ECM_LHOM_W 0 "Not_In_Limp_Home" 1 "In_Limp_Home" ;
VAL_ 262 ECM_LHOM_Trans_W 0 "Limp Home not Active" 1 "No Redundant Torque Req" 2 "Precise Torque +/-15%" 3 "Imprecise Torque" ;
VAL_ 262 CrankHold_W 0 "Not_Active" 1 "Active" ;
VAL_ 262 ESS_EBOOST_BRKHLD_STATUS 0 "Default_Hold_BSM" 1 "ImmediateRelease" 2 "PositiveGradeTorqueBlending" 3 "NegativeGradeTorqueBlending" 7 "SNA" ;
VAL_ 262 Engine_Stall_Detected 0 "No_Stall_Detected" 1 "Stall_Detected" ;
VAL_ 262 EssEngStrtIsNotAllwdID 0 "EssReady" 1 "ESSActive" 2 "Inhibit" 3 "Disarm" 4 "Disable" 7 "SNA" ;
VAL_ 262 EssEngStrtIsNotAllwd 0 "Start_Allowed" 1 "Start_Not_Allowed" ;
VAL_ 262 EssEngStopIsNotAllwdID 0 "Engine_OverridableID" 1 "Engine_NotOverridableID" 2 "Aftertreatment_NotOverridableID" 3 "Burnoff_NotOverridableID" 4 "OBD_NotOverridableID" 5 "Sparkfoul_NotOverridableID" 6 "Hood_NotOverridableID" 7 "StaleFuel_NotOverridableID" 8 "Temperatures_NotOverridable" 9 "Occupant_NotOverridable" 15 "SNA" ;
VAL_ 262 EssEngStopIsNotAllwd 0 "Stop_Allowed" 1 "Stop_Not_Allowed" ;
VAL_ 262 EssEngSt 0 "Stopped" 1 "Starting" 2 "Running" 3 "Spinning" 4 "Stopping" 5 "Reversing" 6 "Not_Used" 7 "SNA" ;
VAL_ 262 EssEngModReq 0 "Do_Nothing" 1 "Prepare_for_Start" 2 "Start" 3 "Prepare_for_Stop" 4 "Stop" 7 "SNA" ;
VAL_ 262 CompressionTest 0 "CompressionTest_NotActive" 1 "CompressionTest_Active" ;
VAL_ 258 VehicleSpeedVSOSig 8191 "SNA" ;
VAL_ 258 LongAccelerationFailSts_BSM 0 "Fail_Not_Present" 1 "Fail_Present" ;
VAL_ 258 LongAcceleration_BSM 4095 "SNA" ;
VAL_ 258 LatAccelerationFailSts_BSM 0 "Fail_Not_Present" 1 "Fail_Present" ;
VAL_ 258 LatAcceleration_BSM 4095 "SNA" ;
VAL_ 258 ESCActive 0 "Not_active" 1 "Active" ;
VAL_ 258 ABSActive 0 "Not_active" 1 "Active" ;
VAL_ 476 ShiftLockFailSts 0 "Fail_not_Present" 1 "Fail_Present" ;
VAL_ 476 PRNDFailSts 0 "Fail_Not_Present" 1 "Fail_Present" ;
VAL_ 476 PRNDdisplayFailSts 0 "Fail_not_present" 1 "Fail_present" ;
VAL_ 476 APCM_Stat 0 "OFF" 1 "ON" 2 "PENDING" 3 "SNA" ;
VAL_ 476 SolenoidFlt 0 "No Fault" 1 "Fault" ;
VAL_ 476 ShiftLever_PositionFlt 0 "No Fault" 1 "Fault" ;
VAL_ 476 Low_Mode_Req 0 "Not_Pressed" 1 "Pressed" ;
VAL_ 476 ShiftLeverPositionReq 0 "No_Selection_Active_Or_Available" 1 "P" 2 "R" 3 "N" 4 "D" 5 "L" 6 "TIP_Autostick" 7 "Plus" 8 "Minus" 9 "Sport" 10 "Not_Used" 11 "Not_Used" 12 "Not_Used" 13 "Not_Used" 14 "Not_Used" 15 "SNA" ;
VAL_ 242 INVFInterlockSts 0 "Not_Performed" 1 "OK" 2 "Fail" 3 "Invalid" ;
VAL_ 242 InvF_DC_Voltage 1023 "SNA" ;
VAL_ 242 InvF_DerateReason 0 "Reason1" 1 "Reason2" 2 "Reason3" 3 "Reason4" 4 "Reason5" 5 "Reason6" 6 "Reason7" 7 "Reason8" 8 "Reason9" 9 "Reason10" 10 "Reason11" 11 "Reason12" 12 "Reason13" 13 "Reason14" 14 "Reason15" 15 "Reason16" ;
VAL_ 242 MCPA_TorqAchieved_AEMD_V 0 "Valid" 1 "Invalid" ;
VAL_ 242 MCPA_RPM_V 0 "Valid" 1 "Invalid" ;
VAL_ 242 MCPA_MtrMinCpbltyTrq 8191 "SNA" ;
VAL_ 242 MCPA_MtrMaxCpbltyTrq 8191 "SNA" ;
VAL_ 242 MCPA_MtrIndex 31 "SNA" ;
VAL_ 242 MCPA_MinTorq 8191 "SNA" ;
VAL_ 242 MCPA_MaxTorq 8191 "SNA" ;
VAL_ 242 MCPA_Invrtr_State 0 "NORMAL_POWER_STAGE_OFF " 1 "NORMAL_POWER_STAGE_ON " 2 "NORMAL_POWER_STAGE_OVERRIDE" 3 "ACTIVE_DISCHARGE " 4 "INVERTER_FAULTED " 5 "NORMAL_POWER_STAGE_OFF_HV_RQD" 6 "NORMAL_VC_PRIMING" 7 "NORMAL_VC_ON" ;
VAL_ 242 MCPA_HV_CnctrOpn_Req 0 "False" 1 "True" ;
VAL_ 242 MCPA_Dschrge_Status 0 "AD_INDETERMINATE" 1 "AD_INPROGRESS" 2 "AD_COMPLETE" 3 "AD_FAILED" ;
VAL_ 242 MCPA_DeratingFactor 63 "SNA" ;
VAL_ 242 MCPA_DC_Volt_V 0 "Valid" 1 "Invalid" ;
VAL_ 242 MCPA_DC_Current_V 0 "Valid" 1 "Invalid" ;
VAL_ 242 MCPA_CpbltySpdDivVolt 65535 "SNA" ;
VAL_ 242 MCPA_AccelRawV 0 "Valid" 1 "Invalid" ;
VAL_ 242 MCPA_6SO_Status 0 "3PS" 1 "6SO" 2 "Switching" 3 "SNA" ;
VAL_ 242 MCPA_3PS_Pos 0 "False" 1 "True" ;
VAL_ 242 InvF_CoolantTemp 2047 "SNA" ;
VAL_ 242 MCPA_Torque_Achieved_V 0 "Valid" 1 "Invalid" ;
VAL_ 242 MCPA_SPT_Stat 0 "Undetermined " 1 "Passed" 2 "Failed" ;
VAL_ 2654486617 CBV_bit3_NMCoordinatorBit_1E3840 0 "Start of synchronized shutdown is not requested by main coordinator" 1 "Start of synchronized shutdown is requested by main coordinator" ;
VAL_ 2654486617 CBV_bit4_ActiveWakeupBit_1E38405 0 "PassiveWakeup" 1 "ActiveWakeup" ;
VAL_ 2654486617 CBV_bit6_PartialNtwInfBit_1E3840 0 "NM PDU contains no Partial Network request information" 1 "NM PDU contains Partial Network request information" ;
VAL_ 2654486617 CBV_bit0_RepeatMessageRequestBit 0 "Repeat Message State not requested" 1 "Repeat Message State requested" ;
VAL_ 2654486616 CBV_bit0_RepeatMessageReque_0000 0 "Repeat Message State not requested" 1 "Repeat Message State requested" ;
VAL_ 2654486616 CBV_bit3_NMCoordinatorBit_1_0000 0 "Start of synchronized shutdown is not requested by main coordinator" 1 "Start of synchronized shutdown is requested by main coordinator" ;
VAL_ 2654486616 CBV_bit4_ActiveWakeupBit_1E_0000 0 "PassiveWakeup" 1 "ActiveWakeup" ;
VAL_ 2654486616 CBV_bit6_PartialNtwInfBit_1_0000 0 "NM PDU contains no Partial Network request information" 1 "NM PDU contains Partial Network request information" ;
VAL_ 496 PlockFailSts 0 "Fault_Not_Present" 1 "Derating" 2 "Retrying" 3 "Non recoverable critical fault" 7 "SNA" ;
VAL_ 496 Plock_PosSensor 0 "Init" 1 "Unknown" 2 "Engaged" 3 "Between Engaged and Disengaged" 4 "Tooth to Tooth" 5 "Disengaged" 7 "SNA" ;
VAL_ 496 Plock_MotorPosSts 0 "Init" 1 "Unknown" 2 "Engaged Endstop" 3 "Engaged" 4 "Between Engaged and Disengaged" 5 "Disengaged" 6 "Disengaged Endstop" 7 "SNA" ;
VAL_ 496 MPR_PosSensor 0 "Init" 1 "Unknown" 2 "Engaged" 3 "Disengaged" 7 "SNA" ;
VAL_ 496 Plock_fdbk_sts 0 "Init" 1 "Engaging" 2 "Engaged" 3 "Disengaging" 4 "Disengaged" 5 "Fault" 7 "SNA" ;
VAL_ 1454 MCPB_Service_Lamp_Request 0 "False" 1 "True" ;
VAL_ 1444 MCPA_Service_Lamp_Request 0 "False" 1 "True" ;
VAL_ 105 T7_CoolantTempVldty 0 "Valid" 1 "Not_Valid" ;
VAL_ 105 PwrElecSnsr_TEMP 255 "SNA" ;
VAL_ 105 PwrElecPmp_TEMP 255 "SNA" ;
VAL_ 260 INVRRInterlockSts 0 "Not_Performed" 1 "OK" 2 "Fail" 3 "Invalid" ;
VAL_ 260 InvRR_DC_Voltage 1023 "SNA" ;
VAL_ 260 InvRR_DerateReason 0 "Reason1" 1 "Reason2" 2 "Reason3" 3 "Reason4" 4 "Reason5" 5 "Reason6" 6 "Reason7" 7 "Reason8" 8 "Reason9" 9 "Reason10" 10 "Reason11" 11 "Reason12" 12 "Reason13" 13 "Reason14" 14 "Reason15" 15 "Reason16" ;
VAL_ 260 InvRR_ACVoltage 1023 "SNA" ;
VAL_ 260 MCPB_Torque_Achieved_V 0 "Valid" 1 "Invalid" ;
VAL_ 260 MCPB_TorqAchieved_AEMD_V 0 "Valid" 1 "Invalid" ;
VAL_ 260 MCPB_RPM_V 0 "Valid" 1 "Invalid" ;
VAL_ 260 MCPB_MtrMinCpbltyTrq 8191 "SNA" ;
VAL_ 260 MCPB_MtrMaxCpbltyTrq 8191 "SNA" ;
VAL_ 260 MCPB_MtrIndex 31 "SNA" ;
VAL_ 260 MCPB_MinTorq 8191 "SNA" ;
VAL_ 260 MCPB_MaxTorq 8191 "SNA" ;
VAL_ 260 MCPB_Invrtr_State 0 "NORMAL_POWER_STAGE_OFF " 1 "NORMAL_POWER_STAGE_ON " 2 "NORMAL_POWER_STAGE_OVERRIDE" 3 "ACTIVE_DISCHARGE " 4 "INVERTER_FAULTED " 5 "NORMAL_POWER_STAGE_OFF_HV_RQD" 6 "NORMAL_VC_PRIMING" 7 "NORMAL_VC_ON" ;
VAL_ 260 MCPB_HV_CnctrOpn_Req 0 "False" 1 "True" ;
VAL_ 260 MCPB_Dschrge_Status 0 "AD_INDETERMINATE" 1 "AD_INPROGRESS" 2 "AD_COMPLETE" 3 "AD_FAILED" ;
VAL_ 260 MCPB_DeratingFactor 63 "SNA" ;
VAL_ 260 MCPB_DC_Volt_V 0 "Valid" 1 "Invalid" ;
VAL_ 260 MCPB_DC_Current_V 0 "Valid" 1 "Invalid" ;
VAL_ 260 MCPB_CpbltySpdDivVolt 65535 "SNA" ;
VAL_ 260 MCPB_AccelRawV 0 "Valid" 1 "Invalid" ;
VAL_ 260 MCPB_6SO_Status 0 "3PS" 1 "6SO" 2 "Switching" 3 "SNA" ;
VAL_ 260 MCPB_3PS_Pos 0 "False" 1 "True" ;
VAL_ 260 InvRR_CoolantTemp 2047 "SNA" ;
VAL_ 260 MCPB_SPT_Stat 0 "Undetermined " 1 "Passed" 2 "Failed" ;
VAL_ 1062 MCPA_Temp 255 "SNA" ;
VAL_ 1062 MCPA_Rotor_Temperature 255 "SNA" ;
VAL_ 1062 MCPA_Inverter_Temp 255 "SNA" ;
VAL_ 1062 MCPA_Control_Board_Temperature 255 "SNA" ;
VAL_ 1062 CLrDiagInfo_MCPA 0 "False" 1 "True" ;
VAL_ 1062 MCPA_PIM_DC_Side_Busbar_Temp 255 "SNA" ;
VAL_ 300 Mtr_6SO_Request_MCPB 0 "False" 1 "True" ;
VAL_ 300 Mtr_6SO_Request_MCPA 0 "False" 1 "True" ;
VAL_ 300 ModeCommand_MCPB 0 "Inverter_Disabled" 1 "Torque_Control" 2 "Speed_Control" 3 "Active_Discharge" 4 "Disable_Immediate" 5 "Voltage_Control" 6 "Rapid_Shutdown" 7 "Shutdown_Initiated" 8 "ROL_Routine" 9 "Active_Short_Circuit" 15 "SNA" ;
VAL_ 300 ModeCommand_MCPA 0 "Inverter_Disabled" 1 "Torque_Control" 2 "Speed_Control" 3 "Active_Discharge" 4 "Disable_Immediate" 5 "Voltage_Control" 6 "0x6 Rapid_Shutdown" 7 "Shutdown_Initiated" 8 "ROL_Routine" 9 "Active_Short_Circuit" 15 "SNA" ;
VAL_ 300 AEMD_Sclr_Gn_MCPB 511 "SNA" ;
VAL_ 300 AEMD_Sclr_Gn_MCPA 511 "SNA" ;
VAL_ 1063 MCPB_Temp 255 "SNA" ;
VAL_ 1063 MCPB_Rotor_Temperature 255 "SNA" ;
VAL_ 1063 MCPB_Inverter_Temp 255 "SNA" ;
VAL_ 1063 MCPB_Control_Board_Temperature 255 "SNA" ;
VAL_ 1063 CLrDiagInfo_MCPB 0 "False" 1 "True" ;
VAL_ 1063 MCPB_PIM_DC_Side_Busbar_Temp 255 "SNA" ;
VAL_ 292 BPCM_HV_TractionBusVoltage 2047 "SNA" ;
VAL_ 292 BPCM_HV_Trac_Bus_Sts 0 "Open" 1 "Closed" 2 "Precharging" 3 "Precharging_Failed" 4 "Precharging_Inhibited" 7 "SNA" ;
VAL_ 2654339273 GenericFailSts_FD16_SGCP 0 "No_Fail_Present" 1 "Fail_Present" ;
VAL_ 2654339273 EOL_FD16_SGCP 0 "No_EOL_Programming" 1 "EOL_Programming" ;
VAL_ 2654339273 CurrentFailSts_FD16_SGCP 0 "No_Fail_Present" 1 "Fail_Present" ;
VAL_ 2654339161 EOL_FD16_MCPB 0 "No_EOL_Programming" 1 "EOL_Programming" ;
VAL_ 2654339161 GenericFailSts_FD16_MCPB 0 "No_Fail_Present" 1 "Fail_Present" ;
VAL_ 2654339161 CurrentFailSts_FD16_MCPB 0 "No_Fail_Present" 1 "Fail_Present" ;
VAL_ 2654339160 EOL_FD16_MCPA 0 "No_EOL_Programming" 1 "EOL_Programming" ;
VAL_ 2654339160 GenericFailSts_FD16_MCPA 0 "No_Fail_Present" 1 "Fail_Present" ;
VAL_ 2654339160 CurrentFailSts_FD16_MCPA 0 "No_Fail_Present" 1 "Fail_Present" ;
VAL_ 243 SGCP_Torque_Achieved_V 0 "Valid" 1 "Invalid" ;
VAL_ 243 SGCP_TorqAchieved_AEMD_V 0 "Valid" 1 "Invalid" ;
VAL_ 243 SGCP_SPT_Stat 0 "Undetermined " 1 "Passed" 2 "Failed" ;
VAL_ 243 SGCP_RPM_V 0 "Valid" 1 "Invalid" ;
VAL_ 243 SGCP_MtrMinCpbltyTrq 8191 "SNA" ;
VAL_ 243 SGCP_MtrMaxCpbltyTrq 8191 "SNA" ;
VAL_ 243 SGCP_MtrIndex 31 "SNA" ;
VAL_ 243 SGCP_MinTorq 8191 "SNA" ;
VAL_ 243 SGCP_MaxTorq 8191 "SNA" ;
VAL_ 243 SGCP_Invrtr_State 0 "NORMAL_POWER_STAGE_OFF " 1 "NORMAL_POWER_STAGE_ON " 2 "NORMAL_POWER_STAGE_OVERRIDE" 3 "ACTIVE_DISCHARGE " 4 "INVERTER_FAULTED " 5 "NORMAL_POWER_STAGE_OFF_HV_RQD" 6 "NORMAL_VC_PRIMING" 7 "NORMAL_VC_ON" ;
VAL_ 243 SGCP_InterlockSts 0 "Not_Performed" 1 "OK" 2 "Fail" 3 "Invalid" ;
VAL_ 243 SGCP_HV_CnctrOpn_Req 0 "False" 1 "True" ;
VAL_ 243 SGCP_Dschrge_Status 0 "AD_DISABLED" 1 "AD_INPROGRESS" 2 "AD_COMPLETE" 3 "AD_FAILED" ;
VAL_ 243 SGCP_DeratingFactor 63 "SNA" ;
VAL_ 243 SGCP_DerateReason 0 "Reason1" 1 "Reason2" 2 "Reason3" 3 "Reason4" 4 "Reason5" 5 "Reason6" 6 "Reason7" 7 "Reason8" 8 "Reason9" 9 "Reason10" 10 "Reason11" 11 "Reason12" 12 "Reason13" 13 "Reason14" 14 "Reason15" 15 "Reason16" ;
VAL_ 243 SGCP_DC_Voltage 1023 "SNA" ;
VAL_ 243 SGCP_DC_Volt_V 0 "Valid" 1 "Invalid" ;
VAL_ 243 SGCP_DC_Current_V 0 "Valid" 1 "Invalid" ;
VAL_ 243 SGCP_CpbltySpdDivVolt 65535 "SNA" ;
VAL_ 243 SGCP_Comm_Fail_CAN 0 "No_Fault" 1 "MCPA_LOC_MCPB" 2 "MCPA_LOC_MCPC" 3 "MCPA_LOC_BPCM" 4 "MCPA_LOC_MCPB_MCPC" 5 "MCPA_LOC_MCPB_BPCM" 6 "MCPA_LOC_MCPC_BPCM" 7 "MCPA_LOC_MCPB_MCPC_BPCM" 8 "MCPA_LOC_VDCM" 14 "MCPA_Bus_Failure_CAN" 15 "SNA" ;
VAL_ 243 SGCP_AccelRawV 0 "Valid" 1 "Invalid" ;
VAL_ 243 SGCP_6SO_Status 0 "3PS" 1 "6SO" 2 "Switching" 3 "SNA" ;
VAL_ 243 SGCP_3PS_Pos 0 "False" 1 "True" ;
SIG_GROUP_ 262 ENGINE_FD_2_Pkt 1 : TxAC_EMCC_rq_W TRANS_CLU_SLIP_MODE_W PowertrainPrplsnActv MessageCounter_ENGINE2 LV12PwrFreeRq_W KickDownRequest_W IntakeAirTemperature_W GasPedalPositionFailSts_W GasPedalPosition_W ESS_RqShftPark_W ESS_ENG_ST_W EngTrq_Enbl_Rq_TCM_W EngineSts_W EngineSpeedFailSts_W EngineSpeed_W EngineIdleRefSpeed EngineFrictionTorque_W ECM_LHOM_W ECM_LHOM_Trans_W CRC_ENGINE2 CrankHold_W ESS_EBOOST_BRKHLD_STATUS Engine_Stall_Detected EssEngStrtIsNotAllwdID EssEngStrtIsNotAllwd EssEngStopIsNotAllwdID EssEngStopIsNotAllwd EssEngSt EssEngModReq CompressionTest;
SIG_GROUP_ 476 AGSM_FD_2_Pkt 1 : ShiftLockFailSts PRNDFailSts PRNDdisplayFailSts MessageCounter_AGSM2 CRC_AGSM2 APCM_Stat SolenoidFlt ShiftLever_PositionFlt Low_Mode_Req ShiftLeverPositionReq;
SIG_GROUP_ 242 PIM_F_Pkt 1 : MC_PF1 INVFInterlockSts InvF_DC_Voltage CRC_PF1 InvF_DerateReason MCPA_Torque_Achieved MCPA_TorqAchieved_AEMD_V MCPA_TorqAchieved_AEMD MCPA_Spd_Lim MCPA_RPM_V MCPA_RPM MCPA_MtrMinCpbltyTrq MCPA_MtrMaxCpbltyTrq MCPA_MtrIndex MCPA_MinTorq MCPA_MaxTorq MCPA_Invrtr_State MCPA_HV_CnctrOpn_Req MCPA_Dschrge_Status MCPA_DeratingFactor MCPA_DC_Volt_V MCPA_DC_Current_V MCPA_DC_Current MCPA_CpbltySpdDivVolt MCPA_AccelRawV MCPA_AccelRaw MCPA_6SO_Status MCPA_3PS_Pos InvF_CoolantTemp MCPA_Torque_Achieved_V MCPA_SPT_Stat;
SIG_GROUP_ 496 PARK_DATA_Pkt 1 : MessageCounter_PARK_DATA CRC_PARK_DATA PlockFailSts Plock_PosSensor Plock_MotorPosSts MPR_PosSensor Plock_fdbk_sts;
SIG_GROUP_ 1454 MCPB_DATA_Pkt 1 : MCPB_Service_Lamp_Request;
SIG_GROUP_ 1444 MCPA_DATA_Pkt 1 : MCPA_Service_Lamp_Request;
SIG_GROUP_ 260 PIM_RR_Pkt 1 : INVRRInterlockSts InvRR_DC_Voltage InvRR_DerateReason InvRR_ACVoltage RPM_MCPB MCPB_Torque_Achieved_V MCPB_Torque_Achieved MCPB_TorqAchieved_AEMD_V MCPB_TorqAchieved_AEMD MCPB_Spd_Lim MCPB_RPM_V MCPB_MtrMinCpbltyTrq MCPB_MtrMaxCpbltyTrq MCPB_MtrIndex MCPB_MinTorq MCPB_MaxTorq MCPB_Invrtr_State MCPB_HV_CnctrOpn_Req MCPB_Dschrge_Status MCPB_DeratingFactor MCPB_DC_Volt_V MCPB_DC_Current_V MCPB_DC_Current MCPB_CpbltySpdDivVolt MCPB_AccelRawV MCPB_AccelRaw MCPB_6SO_Status MCPB_3PS_Pos MC_PRR1 InvRR_CoolantTemp CRC_PRR1 MCPB_SPT_Stat;
SIG_GROUP_ 1062 MCPA_DATA2_Pkt 1 : MCPA_Temp MCPA_Rotor_Temperature MCPA_Inverter_Temp MCPA_Control_Board_Temperature CLrDiagInfo_MCPA MessageCounter_MCPA_DATA2 CRC_MCPA_DATA2 MCPA_PIM_DC_Side_Busbar_Temp MCPA_Service_Lamp_Request_2;
SIG_GROUP_ 300 INVTARGET1_Pkt 1 : UDCMax_Unlim_MCPB UDCMax_Unlim_MCPA TqGrdtLim_MCPB TqGrdtLim_MCPA TorqueCommand_MCPB TorqueCommand_MCPA TargetMotorRPM_MCPB TargetMotorRPM_MCPA SpdGrdtLim_MCPB SpdGrdtLim_MCPA Mtr_6SO_Request_MCPB Mtr_6SO_Request_MCPA ModeCommand_MCPB ModeCommand_MCPA MessageCounter_INVTARGET1 CRC_INVTARGET1 AEMD_MinOffset_MCPB AEMD_MinOffset_MCPA AEMD_MaxOffset_MCPB AEMD_MaxOffset_MCPA AEMD_Sclr_Gn_MCPB AEMD_Sclr_Gn_MCPA AEMD_Cutoff_FreqHigh_MCPB AEMD_Cutoff_FreqHigh_MCPA Pwr_Electronics_Loop_FlwRate_MCP AEMD_Cutoff_FreqLow_MCPB AEMD_Cutoff_FreqLow_MCPA Pwr_Electronics_Loop_FlwRat_0000;
SIG_GROUP_ 1063 MCPB_DATA2_Pkt 1 : MCPB_Temp MCPB_Rotor_Temperature MCPB_Inverter_Temp MCPB_Control_Board_Temperature CLrDiagInfo_MCPB MessageCounter_MCPB_DATA2 CRC_MCPB_DATA2 MCPB_PIM_DC_Side_Busbar_Temp MCPB_Service_Lamp_Request_2;
SIG_GROUP_ 292 BATTERY_HV_STATUS1_Pkt 1 : MessageCounter_BATT_HV_STATUS1 CRC_BATT_HV_STATUS1 BPCM_HV_TractionBusVoltage BPCM_HV_Trac_Bus_Sts;
SIG_GROUP_ 243 SGCP_PWT1_Pkt 1 : SGCP_Torque_Achieved_V SGCP_Torque_Achieved SGCP_TorqAchieved_AEMD_V SGCP_TorqAchieved_AEMD SGCP_SPT_Stat SGCP_Spd_Lim SGCP_RPM_V SGCP_RPM SGCP_MtrMinCpbltyTrq SGCP_MtrMaxCpbltyTrq SGCP_MtrIndex SGCP_MinTorq SGCP_MaxTorq SGCP_Invrtr_State SGCP_InterlockSts SGCP_HV_CnctrOpn_Req SGCP_Dschrge_Status SGCP_DeratingFactor SGCP_DerateReason SGCP_DC_Voltage SGCP_DC_Volt_V SGCP_DC_Current_V SGCP_DC_Current SGCP_CpbltySpdDivVolt SGCP_Comm_Fail_CAN SGCP_AccelRawV SGCP_AccelRaw SGCP_6SO_Status SGCP_3PS_Pos MC_SGCP_PWT1 CRC_SGCP_PWT1;
